VERSION ""

NS_ :

BS_:

BU_: VT OPC

BO_ 2632384254 VT12: 33 Vector__XXX
 SG_ AssignedAttribute2 m39 : 105|1@1+ (1,0) [0|1] "" Vector__XXX
 SG_ AssignedAttribute1 m39 : 104|1@1+ (1,0) [0|1] "" Vector__XXX
 SG_ FunctionAttribute m39 : 96|8@1+ (1,0) [0|255] "" Vector__XXX
 SG_ NumberOfInstances m39 : 88|8@1+ (1,0) [0|255] "" Vector__XXX
 SG_ NumberOfDifferentSets m39 : 80|8@1+ (1,0) [0|255] "" Vector__XXX
 SG_ NameOfAuxiliaryUnit m39 : 16|64@1+ (1,0) [0|0] "" Vector__XXX
 SG_ NumberOfAuxiliaryUnits m39 : 8|8@1+ (1,0) [0|255] "" Vector__XXX
 SG_ ExtendedVersionLables m211 : 8|256@1+ (1,0) [0|7.20575940379279E+016] "" Vector__XXX
 SG_ VTFunctionVTtoECU M : 0|8@1+ (1,0) [0|255] "" Vector__XXX
 SG_ BootTime m199 : 8|8@1+ (1,0) [0|255] "s" Vector__XXX
 SG_ NumberOfSupportedObjects m197 : 8|8@1+ (1,0) [0|255] "" Vector__XXX
 SG_ BckgndColourUserLayoutDataMask m196 : 8|8@1+ (1,0) [0|255] "" Vector__XXX
 SG_ ObjectID_1 m9 : 8|16@1+ (1,0) [0|65535] "" Vector__XXX
 SG_ InputNumber m33 : 8|8@1+ (1,0) [0|250] "" Vector__XXX
 SG_ TerminationCause m10 : 8|8@1+ (1,0) [0|255] "" Vector__XXX
 SG_ KeyActivationCode m0 : 8|8@1+ (1,0) [0|2] "" Vector__XXX
 SG_ ButtonActivationCode m1 : 8|8@1+ (1,0) [0|2] "" Vector__XXX
 SG_ XPosition m2 : 8|16@1+ (1,0) [0|65535] "" Vector__XXX
 SG_ VTSelectInputObjectID m3 : 8|16@1+ (1,0) [0|65535] "" Vector__XXX
 SG_ VTEscObjectID m4 : 8|16@1+ (1,0) [0|65535] "" Vector__XXX
 SG_ VTChangeNumericValueObjectID m5 : 8|16@1+ (1,0) [0|65535] "" Vector__XXX
 SG_ VTChangeActiveMaskObjectID m6 : 8|16@1+ (1,0) [0|65535] "" Vector__XXX
 SG_ VTChangeSoftKeyMaskParentID m7 : 8|16@1+ (1,0) [0|65535] "" Vector__XXX
 SG_ ObjectToChangeStringID m8 : 8|16@1+ (1,0) [0|65535] "" Vector__XXX
 SG_ ErrorCodeEndOfObjectPool1 m18 : 8|1@1+ (1,0) [0|1] "" Vector__XXX
 SG_ IdentityNumber m36 : 8|21@1+ (1,0) [0|2097150] "" Vector__XXX
 SG_ InputObjectId m38 : 8|16@1+ (1,0) [0|255] "" Vector__XXX
 SG_ AuxPreferredAssignmentRespError1 m34 : 8|1@1+ (1,0) [0|1] "" Vector__XXX
 SG_ InputStatusObjectId m37 : 8|16@1+ (1,0) [0|255] "" Vector__XXX
 SG_ ObjectEscapeID m146 : 8|16@1+ (1,0) [0|65535] "" Vector__XXX
 SG_ ObjectToHideShowID m160 : 8|16@1+ (1,0) [0|65535] "" Vector__XXX
 SG_ ObjectToEnableDisableID m161 : 8|16@1+ (1,0) [0|65535] "" Vector__XXX
 SG_ SelectInputObjectID m162 : 8|16@1+ (1,0) [0|65535] "" Vector__XXX
 SG_ ErrorCodeControlAudioDevice1 m163 : 8|1@1+ (1,0) [0|1] "" Vector__XXX
 SG_ ErrorCodeAudioVolume1 m164 : 8|1@1+ (1,0) [0|1] "" Vector__XXX
 SG_ ChangeChildLocationParentObjectI m165 : 8|16@1+ (1,0) [0|65535] "" Vector__XXX
 SG_ ObjectToSizeID m166 : 8|16@1+ (1,0) [0|65535] "" Vector__XXX
 SG_ ObjectToChangeColourID m167 : 8|16@1+ (1,0) [0|65535] "" Vector__XXX
 SG_ ObjectToChangeNumValueID m168 : 8|16@1+ (1,0) [0|65535] "" Vector__XXX
 SG_ ObjectToChangeEndPointID m169 : 8|16@1+ (1,0) [0|65535] "" Vector__XXX
 SG_ ObjectToChangeFontID m170 : 8|16@1+ (1,0) [0|65535] "" Vector__XXX
 SG_ ObjectToChangeLineAttributeID m171 : 8|16@1+ (1,0) [0|65535] "" Vector__XXX
 SG_ ObjectToChangeFillAttributesID m172 : 8|16@1+ (1,0) [0|65535] "" Vector__XXX
 SG_ ActiveMaskObjectID m173 : 8|16@1+ (1,0) [0|0] "" Vector__XXX
 SG_ DataOrAlarmMaskObjectID m174 : 8|16@1+ (1,0) [0|65535] "" Vector__XXX
 SG_ ObjectToChangeAttributeID m175 : 8|16@1+ (1,0) [0|65535] "" Vector__XXX
 SG_ AlarmMaskObjectID m176 : 8|16@1+ (1,0) [0|65535] "" Vector__XXX
 SG_ ListInputObjectID m177 : 8|16@1+ (1,0) [0|65535] "" Vector__XXX
 SG_ ErrorCodeDeleteObjectPool1 m178 : 8|1@1+ (1,0) [0|1] "" Vector__XXX
 SG_ ChangeChildPositionParentObjectI m180 : 8|16@1+ (1,0) [0|65535] "" Vector__XXX
 SG_ ErrorCodeSetObjectLabel1 m181 : 8|1@1+ (1,0) [0|1] "" Vector__XXX
 SG_ PolygonObjectToChangeID m182 : 8|16@1+ (1,0) [0|65535] "" Vector__XXX
 SG_ PolygonObjectToScaleID m183 : 8|16@1+ (1,0) [0|65535] "" Vector__XXX
 SG_ GraphicsContextObjectID m184 : 8|16@1+ (1,0) [0|65535] "" Vector__XXX
 SG_ ObjectToGetAttributeID m185 : 8|16@1+ (1,0) [0|65535] "" Vector__XXX
 SG_ ColourMapObjectID m186 : 8|16@1+ (1,0) [0|65535] "" Vector__XXX
 SG_ LockUnlockCommand m189 : 8|8@1+ (1,0) [0|1] "" Vector__XXX
 SG_ MacroObjecID m190 : 8|8@1+ (1,0) [0|255] "" Vector__XXX
 SG_ VersionNumberISO11783Part6 m192 : 8|8@1+ (1,0) [0|255] "" Vector__XXX
 SG_ CodePlane m193 : 8|8@1+ (1,0) [0|16] "" Vector__XXX
 SG_ NavigationSoftKeys m194 : 8|8@1+ (1,0) [0|254] "" Vector__XXX
 SG_ NrOfVersionStrings m224 : 8|8@1+ (1,0) [0|255] "" Vector__XXX
 SG_ ParentIDOfFaultyObject m240 : 8|16@1+ (1,0) [0|65535] "" Vector__XXX
 SG_ SourceAdressOfActiveWSM m254 : 8|8@1+ (1,0) [0|255] "" Vector__XXX
 SG_ ErrorCodeEndOfObjectPool2 m18 : 9|1@1+ (1,0) [0|1] "" Vector__XXX
 SG_ AuxPreferredAssignmentRespError2 m34 : 9|1@1+ (1,0) [0|1] "" Vector__XXX
 SG_ ErrorCodeSetObjectLabel2 m181 : 9|1@1+ (1,0) [0|1] "" Vector__XXX
 SG_ AuxPreferredAssignmentRespError3 m34 : 10|1@1+ (1,0) [0|1] "" Vector__XXX
 SG_ ErrorCodeSetObjectLabel3 m181 : 10|1@1+ (1,0) [0|1] "" Vector__XXX
 SG_ AuxPreferredAssignmentRespError4 m34 : 11|1@1+ (1,0) [0|1] "" Vector__XXX
 SG_ ErrorCodeSetObjectLabel4 m181 : 11|1@1+ (1,0) [0|1] "" Vector__XXX
 SG_ AuxPreferredAssignmentRespError5 m34 : 12|1@1+ (1,0) [0|1] "" Vector__XXX
 SG_ ErrorCodeEndOfObjectPool3 m18 : 12|1@1+ (1,0) [0|1] "" Vector__XXX
 SG_ ErrorCodeControlAudioDevice2 m163 : 12|1@1+ (1,0) [0|1] "" Vector__XXX
 SG_ ErrorCodeAudioVolume2 m164 : 12|1@1+ (1,0) [0|1] "" Vector__XXX
 SG_ ErrorCodeDeleteObjectPool2 m178 : 12|1@1+ (1,0) [0|1] "" Vector__XXX
 SG_ ErrorCodeSetObjectLabel5 m181 : 12|1@1+ (1,0) [0|1] "" Vector__XXX
 SG_ ErrorCodeSetObjectLabel6 m181 : 13|1@1+ (1,0) [0|1] "" Vector__XXX
 SG_ BckgndColourUserLayoutSoftkeyMas m196 : 16|8@1+ (1,0) [0|255] "" Vector__XXX
 SG_ AnalogValue m33 : 16|16@1+ (1,0) [0|65535] "" Vector__XXX
 SG_ AuxFunctObjOfFaultyAssignment m34 : 16|16@1- (1,0) [0|65535] "" Vector__XXX
 SG_ KeyObjectID m0 : 16|16@1+ (1,0) [0|65535] "" Vector__XXX
 SG_ ButtonObjectID m1 : 16|16@1+ (1,0) [0|65535] "" Vector__XXX
 SG_ ParentObjectIDOfFaultyObject m18 : 16|16@1+ (1,0) [0|65535] "" Vector__XXX
 SG_ ErrorCodeLockUnlockMask1 m189 : 16|1@1+ (1,0) [0|1] "" Vector__XXX
 SG_ ErrorCodeExecuteMacro1 m190 : 16|1@1+ (1,0) [0|1] "" Vector__XXX
 SG_ MemoryStatus m192 : 16|8@1+ (1,0) [0|1] "" Vector__XXX
 SG_ FirstWideChar m193 : 16|16@1+ (1,0) [0|65535] "" Vector__XXX
 SG_ SupportedGraphicMode m199 : 16|8@1+ (1,0) [0|2] "" Vector__XXX
 SG_ VersionLables m224 : 16|56@1+ (1,0) [0|0] "" Vector__XXX
 SG_ VisibleDataOrAlarmMaskObjectID m254 : 16|16@1+ (1,0) [0|65535] "" Vector__XXX
 SG_ ErrorCodeLockUnlockMask2 m189 : 17|1@1+ (1,0) [0|1] "" Vector__XXX
 SG_ ErrorCodeExecuteMacro2 m190 : 17|1@1+ (1,0) [0|1] "" Vector__XXX
 SG_ ErrorCodeLockUnlockMask3 m189 : 18|1@1+ (1,0) [0|1] "" Vector__XXX
 SG_ ErrorCodeExecuteMacro3 m190 : 18|1@1+ (1,0) [0|1] "" Vector__XXX
 SG_ ErrorCodeLockUnlockMask4 m189 : 19|1@1+ (1,0) [0|1] "" Vector__XXX
 SG_ ErrorCodeLockUnlockMask5 m189 : 20|1@1+ (1,0) [0|1] "" Vector__XXX
 SG_ ErrorCodeLockUnlockMask6 m189 : 21|1@1+ (1,0) [0|1] "" Vector__XXX
 SG_ ErrorCodeLockUnlockMask7 m189 : 22|1@1+ (1,0) [0|1] "" Vector__XXX
 SG_ ErrorCodeLockUnlockMask8 m189 : 23|1@1+ (1,0) [0|1] "" Vector__XXX
 SG_ Status_1 m9 : 24|8@1+ (1,0) [0|1] "" Vector__XXX
 SG_ YPosition m2 : 24|16@1+ (1,0) [0|65535] "" Vector__XXX
 SG_ VTSelectInputObjectStatus m3 : 24|8@1+ (1,0) [0|1] "" Vector__XXX
 SG_ ErrorCodeVTEsc1 m4 : 24|1@1+ (1,0) [0|1] "" Vector__XXX
 SG_ VTChangeSoftKeyMaskObjectID m7 : 24|16@1+ (1,0) [0|65535] "" Vector__XXX
 SG_ EnteredStringValue m8 : 24|8@1+ (1,0) [0|255] "" Vector__XXX
 SG_ Value1 m38 : 24|16@1+ (1,0) [0|65535] "" Vector__XXX
 SG_ AuxInputEnable m37 : 24|8@1+ (1,0) [0|1] "" Vector__XXX
 SG_ ErrorCodeEscapeObj1 m146 : 24|1@1+ (1,0) [0|1] "" Vector__XXX
 SG_ ObjectShowStatus m160 : 24|8@1+ (1,0) [0|1] "" Vector__XXX
 SG_ ObjectEnableStatus m161 : 24|8@1+ (1,0) [0|1] "" Vector__XXX
 SG_ ObjectSelectStatus m162 : 24|8@1+ (1,0) [0|2] "" Vector__XXX
 SG_ ChangeChildLocationObjectID m165 : 24|16@1+ (1,0) [0|65535] "" Vector__XXX
 SG_ ErrorCodeObjToSize1 m166 : 24|1@1+ (1,0) [0|1] "" Vector__XXX
 SG_ NewBackgroundColour m167 : 24|8@1+ (1,0) [0|255] "" Vector__XXX
 SG_ ErrorCodeChangeNumValue1 m168 : 24|1@1+ (1,0) [0|1] "" Vector__XXX
 SG_ ErrorCodeChangeEditPoint1 m169 : 24|1@1+ (1,0) [0|1] "" Vector__XXX
 SG_ ErrorCodeChangeFont1 m170 : 24|1@1+ (1,0) [0|1] "" Vector__XXX
 SG_ ErrorCodeChangeLineAttribute1 m171 : 24|1@1+ (1,0) [0|1] "" Vector__XXX
 SG_ ErrorCodeChangeFillAttributes1 m172 : 24|1@1+ (1,0) [0|1] "" Vector__XXX
 SG_ ErrorCodeChangeActiveMask1 m173 : 24|1@1+ (1,0) [0|1] "" Vector__XXX
 SG_ SoftKeyMaskObjectID m174 : 24|16@1+ (1,0) [0|65535] "" Vector__XXX
 SG_ AttributeToChangeID m175 : 24|8@1+ (1,0) [0|65535] "" Vector__XXX
 SG_ NewPriority m176 : 24|8@1+ (1,0) [0|255] "" Vector__XXX
 SG_ ListIndex m177 : 24|8@1+ (1,0) [0|255] "" Vector__XXX
 SG_ ChangeStringValueObjectID m179 : 24|16@1+ (1,0) [0|65535] "" Vector__XXX
 SG_ ChangeChildPositionObjectID m180 : 24|16@1+ (1,0) [0|65535] "" Vector__XXX
 SG_ ErrorCodeChangePoygonPoint1 m182 : 24|1@1+ (1,0) [0|1] "" Vector__XXX
 SG_ NewWidthAttribute m183 : 24|16@1+ (1,0) [0|65535] "" Vector__XXX
 SG_ SubCommandID m184 : 24|8@1+ (1,0) [0|0] "" Vector__XXX
 SG_ AttributeID m185 : 24|8@1+ (1,0) [0|0] "" Vector__XXX
 SG_ ErrorCodeSelectColourMap1 m186 : 24|1@1+ (1,0) [0|1] "" Vector__XXX
 SG_ Hardware1 m199 : 24|1@1+ (1,0) [0|1] "" Vector__XXX
 SG_ ObjectIDOfFaultyObject m240 : 24|16@1+ (1,0) [0|65535] "" Vector__XXX
 SG_ ErrorCodeObjToSize2 m166 : 25|1@1+ (1,0) [0|1] "" Vector__XXX
 SG_ ErrorCodeChangeNumValue2 m168 : 25|1@1+ (1,0) [0|1] "" Vector__XXX
 SG_ ErrorCodeChangeEditPoint2 m169 : 25|1@1+ (1,0) [0|1] "" Vector__XXX
 SG_ ErrorCodeChangeFont2 m170 : 25|1@1+ (1,0) [0|1] "" Vector__XXX
 SG_ ErrorCodeChangeLineAttribute2 m171 : 25|1@1+ (1,0) [0|1] "" Vector__XXX
 SG_ ErrorCodeChangeFillAttributes2 m172 : 25|1@1+ (1,0) [0|1] "" Vector__XXX
 SG_ ErrorCodeChangeActiveMask2 m173 : 25|1@1+ (1,0) [0|1] "" Vector__XXX
 SG_ ErrorCodeChangePoygonPoint2 m182 : 25|1@1+ (1,0) [0|1] "" Vector__XXX
 SG_ ErrorCodeSelectColourMap2 m186 : 25|1@1+ (1,0) [0|1] "" Vector__XXX
 SG_ Hardware2 m199 : 25|1@1+ (1,0) [0|1] "" Vector__XXX
 SG_ ErrorCodeMissingObjects m6 : 26|1@1+ (1,0) [0|1] "" Vector__XXX
 SG_ ErrorCodeObjToSize3 m166 : 26|1@1+ (1,0) [0|1] "" Vector__XXX
 SG_ ErrorCodeChangeFont3 m170 : 26|1@1+ (1,0) [0|1] "" Vector__XXX
 SG_ ErrorCodeChangeLineAttribute3 m171 : 26|1@1+ (1,0) [0|1] "" Vector__XXX
 SG_ ErrorCodeChangeFillAttributes3 m172 : 26|1@1+ (1,0) [0|1] "" Vector__XXX
 SG_ ErrorCodeChangeActiveMask3 m173 : 26|1@1+ (1,0) [0|1] "" Vector__XXX
 SG_ ErrorCodeChangePoygonPoint3 m182 : 26|1@1+ (1,0) [0|1] "" Vector__XXX
 SG_ Hardware3 m199 : 26|1@1+ (1,0) [0|1] "" Vector__XXX
 SG_ ErrorCodeMaskOrChildObjectError m6 : 27|1@1+ (1,0) [0|1] "" Vector__XXX
 SG_ ErrorCodeChangeFont4 m170 : 27|1@1+ (1,0) [0|1] "" Vector__XXX
 SG_ ErrorCodeChangeFillAttributes4 m172 : 27|1@1+ (1,0) [0|1] "" Vector__XXX
 SG_ ErrorCodeChangeActiveMask4 m173 : 27|1@1+ (1,0) [0|1] "" Vector__XXX
 SG_ Hardware4 m199 : 27|1@1+ (1,0) [0|1] "" Vector__XXX
 SG_ ErrorCodeChangeNumValue4 m168 : 28|1@1+ (1,0) [0|1] "" Vector__XXX
 SG_ ErrorCodeVTEsc2 m4 : 28|1@1+ (1,0) [0|1] "" Vector__XXX
 SG_ ErrorCodeAnyOtherError m6 : 28|1@1+ (1,0) [0|1] "" Vector__XXX
 SG_ ErrorCodeEscapeObj2 m146 : 28|1@1+ (1,0) [0|1] "" Vector__XXX
 SG_ ErrorCodeObjToSize4 m166 : 28|1@1+ (1,0) [0|1] "" Vector__XXX
 SG_ ErrorCodeChangeNumValue3 m168 : 26|1@1+ (1,0) [0|1] "" Vector__XXX
 SG_ ErrorCodeChangeEditPoint3 m169 : 28|1@1+ (1,0) [0|1] "" Vector__XXX
 SG_ ErrorCodeChangeFont5 m170 : 28|1@1+ (1,0) [0|1] "" Vector__XXX
 SG_ ErrorCodeChangeLineAttribute4 m171 : 28|1@1+ (1,0) [0|1] "" Vector__XXX
 SG_ ErrorCodeChangeFillAttributes5 m172 : 28|1@1+ (1,0) [0|1] "" Vector__XXX
 SG_ ErrorCodeChangeActiveMask5 m173 : 28|1@1+ (1,0) [0|1] "" Vector__XXX
 SG_ Hardware5 m199 : 28|1@1+ (1,0) [0|1] "" Vector__XXX
 SG_ ErrorCodePoolDeleted m6 : 29|1@1+ (1,0) [0|1] "" Vector__XXX
 SG_ ManufacturerCode m36 : 29|11@1+ (1,0) [0|2047] "" Vector__XXX
 SG_ ErrorCodeChangeFont6 m170 : 29|1@1+ (1,0) [0|1] "" Vector__XXX
 SG_ Hardware6 m199 : 29|1@1+ (1,0) [0|1] "" Vector__XXX
 SG_ ObjectID_2 m9 : 32|16@1+ (1,0) [0|65535] "" Vector__XXX
 SG_ NumTransitionsDisabledToEnabled m33 : 32|16@1+ (1,0) [0|65535] "" Vector__XXX
 SG_ KeyObjectParentID m0 : 32|16@1+ (1,0) [0|65535] "" Vector__XXX
 SG_ ButtonObjectParentID m1 : 32|16@1+ (1,0) [0|65535] "" Vector__XXX
 SG_ VTSelectInputObjectIsEdited m3 : 32|1@1+ (1,0) [0|1] "" Vector__XXX
 SG_ VTChangeNumericValueValue m5 : 32|32@1+ (1,0) [0|4294967295] "" Vector__XXX
 SG_ VTChangeActiveMaskErrorID m6 : 32|16@1+ (1,0) [0|65535] "" Vector__XXX
 SG_ ObjectIdOfFaultyObject m18 : 32|16@1+ (1,0) [0|65535] "" Vector__XXX
 SG_ ErrorCodeHideShowObj1 m160 : 32|1@1+ (1,0) [0|1] "" Vector__XXX
 SG_ ErrorCodeSelectObject1 m162 : 32|1@1+ (1,0) [0|1] "" Vector__XXX
 SG_ ErrorCodeChangeColour1 m167 : 32|1@1+ (1,0) [0|1] "" Vector__XXX
 SG_ ValueOfTheObject m168 : 32|32@1+ (1,0) [0|2704] "" Vector__XXX
 SG_ ErrorCodeChangeAttribute1 m175 : 32|1@1+ (1,0) [0|1] "" Vector__XXX
 SG_ ErrorCodeChangePriority1 m176 : 32|1@1+ (1,0) [0|1] "" Vector__XXX
 SG_ NewObjectID m177 : 32|16@1+ (1,0) [0|65535] "" Vector__XXX
 SG_ ErrorCodeGraphicsContextCmd1 m184 : 32|1@1+ (1,0) [0|1] "" Vector__XXX
 SG_ LastWideChar m193 : 32|16@1+ (1,0) [0|65535] "" Vector__XXX
 SG_ XDotsForSoftKeyDescriptor m194 : 32|8@1+ (1,0) [0|255] "" Vector__XXX
 SG_ NrOfXPixelsInDataAreaMask m199 : 32|16@1+ (1,0) [0|65535] "" Vector__XXX
 SG_ VisibleSoftKeyMaskObjectID m254 : 32|16@1+ (1,0) [0|65535] "" Vector__XXX
 SG_ ErrorCodeHideShowObj2 m160 : 33|1@1+ (1,0) [0|1] "" Vector__XXX
 SG_ ErrorCodeEnableDisableObj1 m161 : 33|1@1+ (1,0) [0|1] "" Vector__XXX
 SG_ ErrorCodeSelectObject2 m162 : 33|1@1+ (1,0) [0|1] "" Vector__XXX
 SG_ ErrorCodeChangeColour2 m167 : 33|1@1+ (1,0) [0|1] "" Vector__XXX
 SG_ ErrorCodeChangeAttribute2 m175 : 33|1@1+ (1,0) [0|1] "" Vector__XXX
 SG_ ErrorCodeChangePriority2 m176 : 33|1@1+ (1,0) [0|1] "" Vector__XXX
 SG_ ErrorCodeGraphicsContextCmd2 m184 : 33|1@1+ (1,0) [0|1] "" Vector__XXX
 SG_ ErrorCodeEnableDisableObj2 m161 : 34|1@1+ (1,0) [0|1] "" Vector__XXX
 SG_ ErrorCodeSelectObject3 m162 : 34|1@1+ (1,0) [0|1] "" Vector__XXX
 SG_ ErrorCodeChangeAttribute3 m175 : 34|1@1+ (1,0) [0|1] "" Vector__XXX
 SG_ ErrorCodeGraphicsContextCmd3 m184 : 34|1@1+ (1,0) [0|1] "" Vector__XXX
 SG_ ErrorCodeHideShowObj3 m160 : 35|1@1+ (1,0) [0|1] "" Vector__XXX
 SG_ ErrorCodeEnableDisableObj3 m161 : 35|1@1+ (1,0) [0|1] "" Vector__XXX
 SG_ ErrorCodeSelectObject4 m162 : 35|1@1+ (1,0) [0|1] "" Vector__XXX
 SG_ ErrorCodeGraphicsContextCmd4 m184 : 35|1@1+ (1,0) [0|1] "" Vector__XXX
 SG_ ErrorCodeEnableDisableObj4 m161 : 36|1@1+ (1,0) [0|1] "" Vector__XXX
 SG_ ErrorCodeSelectObject5 m162 : 36|1@1+ (1,0) [0|1] "" Vector__XXX
 SG_ ErrorCodeChangeColour3 m167 : 36|1@1+ (1,0) [0|1] "" Vector__XXX
 SG_ ErrorCodeChangeAttribute4 m175 : 35|1@1+ (1,0) [0|1] "" Vector__XXX
 SG_ ErrorCodeChangePriority3 m176 : 36|1@1+ (1,0) [0|1] "" Vector__XXX
 SG_ ErrorCodeGraphicsContextCmd5 m184 : 36|1@1+ (1,0) [0|1] "" Vector__XXX
 SG_ ErrorCodeSelectObject6 m162 : 37|1@1+ (1,0) [0|1] "" Vector__XXX
 SG_ ErrorCodeVTChangeSoftKeyMask1 m7 : 40|1@1+ (1,0) [0|1] "" Vector__XXX
 SG_ TouchState m2 : 40|8@1+ (1,0) [0|255] "" Vector__XXX
 SG_ ECUInstance m36 : 40|3@1+ (1,0) [0|7] "" Vector__XXX
 SG_ Value2 m38 : 40|16@1+ (1,0) [0|65535] "" Vector__XXX
 SG_ ErrorCodeChangeChildLocation1 m165 : 40|1@1+ (1,0) [0|1] "" Vector__XXX
 SG_ ErrorCodeChangeSoftKeyMask1 m174 : 40|1@1+ (1,0) [0|1] "" Vector__XXX
 SG_ ErrorCodeChangePosInvalidParent m180 : 40|1@1+ (1,0) [0|1] "" Vector__XXX
 SG_ NewHeigthAttribute m183 : 40|16@1+ (1,0) [0|0] "" Vector__XXX
 SG_ YDotsForSoftKeyDescriptor m194 : 40|8@1+ (1,0) [0|255] "" Vector__XXX
 SG_ FontSize_8x8 m195 : 40|1@1+ (1,0) [0|1] "" Vector__XXX
 SG_ AcknowledgmentStoreVersion m208 : 40|4@1+ (1,0) [0|8] "" Vector__XXX
 SG_ AcknowledgmentLoadVersion m209 : 40|4@1+ (1,0) [0|8] "" Vector__XXX
 SG_ AcknowledgmentDeleteVersion m210 : 40|4@1+ (1,0) [0|8] "" Vector__XXX
 SG_ ErrorCodeVtObjPoolError1 m240 : 40|1@1+ (1,0) [0|1] "" Vector__XXX
 SG_ ErrorCodeVTChangeSoftKeyMask2 m7 : 41|1@1+ (1,0) [0|1] "" Vector__XXX
 SG_ ErrorCodeChangeChildLocation2 m165 : 41|1@1+ (1,0) [0|1] "" Vector__XXX
 SG_ ErrorCodeChangeSoftKeyMask2 m174 : 41|1@1+ (1,0) [0|1] "" Vector__XXX
 SG_ ErrorCodeChangeStrObjectID m179 : 41|1@1+ (1,0) [0|1] "" Vector__XXX
 SG_ ErrorCodeChangePosInvalidObject m180 : 41|1@1+ (1,0) [0|1] "" Vector__XXX
 SG_ FontSize_8x12 m195 : 41|1@1+ (1,0) [0|1] "" Vector__XXX
 SG_ ErrorCodeVtObjPoolError2 m240 : 41|1@1+ (1,0) [0|1] "" Vector__XXX
 SG_ ErrorCodeVTChangeSoftKeyMask3 m7 : 42|1@1+ (1,0) [0|1] "" Vector__XXX
 SG_ ErrorCodeChangeSoftKeyMask3 m174 : 42|1@1+ (1,0) [0|1] "" Vector__XXX
 SG_ ErrorCodeChangeStrTooLong m179 : 42|1@1+ (1,0) [0|1] "" Vector__XXX
 SG_ FontSize_12x16 m195 : 42|1@1+ (1,0) [0|1] "" Vector__XXX
 SG_ ErrorCodeVtObjPoolError3 m240 : 42|1@1+ (1,0) [0|1] "" Vector__XXX
 SG_ ErrorCodeVTChangeSoftKeyMask4 m7 : 43|1@1+ (1,0) [0|1] "" Vector__XXX
 SG_ FunctionInstance m36 : 43|5@1+ (1,0) [0|31] "" Vector__XXX
 SG_ ErrorCodeChangeSoftKeyMask4 m174 : 43|1@1+ (1,0) [0|1] "" Vector__XXX
 SG_ ErrorCodeChangeStrError m179 : 43|1@1+ (1,0) [0|1] "" Vector__XXX
 SG_ FontSize_16x16 m195 : 43|1@1+ (1,0) [0|1] "" Vector__XXX
 SG_ ErrorCodeVtObjPoolError4 m240 : 43|1@1+ (1,0) [0|1] "" Vector__XXX
 SG_ ErrorCodeChangeStrValueInUse m179 : 44|1@1+ (1,0) [0|1] "" Vector__XXX
 SG_ ErrorCodeVTChangeSoftKeyMask5 m7 : 44|1@1+ (1,0) [0|1] "" Vector__XXX
 SG_ ErrorCodeChangeChildLocation5 m165 : 44|1@1+ (1,0) [0|1] "" Vector__XXX
 SG_ ErrorCodeChangeSoftKeyMask5 m174 : 44|1@1+ (1,0) [0|1] "" Vector__XXX
 SG_ ErrorCodeChangePosInvalidError m180 : 44|1@1+ (1,0) [0|1] "" Vector__XXX
 SG_ FontSize_16x24 m195 : 44|1@1+ (1,0) [0|1] "" Vector__XXX
 SG_ FontSize_24x32 m195 : 45|1@1+ (1,0) [0|1] "" Vector__XXX
 SG_ FontSize_32x32 m195 : 46|1@1+ (1,0) [0|1] "" Vector__XXX
 SG_ Status_2 m9 : 48|8@1+ (1,0) [0|1] "" Vector__XXX
 SG_ BooleanValue m33 : 48|8@1+ (1,0) [0|2] "" Vector__XXX
 SG_ SoftKeyCode m0 : 48|8@1+ (1,0) [0|255] "" Vector__XXX
 SG_ ButtonKeyCode m1 : 48|8@1+ (1,0) [0|255] "" Vector__XXX
 SG_ VTChangeActiveMaskParentID m6 : 48|16@1+ (1,0) [0|65535] "" Vector__XXX
 SG_ ErrorCodeObjectPool1 m18 : 48|1@1+ (1,0) [0|1] "" Vector__XXX
 SG_ Function m36 : 48|8@1+ (1,0) [0|255] "" Vector__XXX
 SG_ ErrorCodeChangeListItem1 m177 : 48|1@1+ (1,0) [0|1] "" Vector__XXX
 SG_ ErrorCodeGetSupportedWideChars1 m193 : 48|1@1+ (1,0) [0|1] "" Vector__XXX
 SG_ NumberOfPossibleVirtualSoftKeys m194 : 48|8@1+ (1,0) [0|255] "" Vector__XXX
 SG_ FontSize_32x48 m195 : 48|1@1+ (1,0) [0|1] "" Vector__XXX
 SG_ NrOfYPixelsInDataAreaMask m199 : 48|16@1+ (1,0) [0|65535] "" Vector__XXX
 SG_ VTBusyCode1 m254 : 48|1@1+ (1,0) [0|1] "" Vector__XXX
 SG_ ErrorCodeObjectPool2 m18 : 49|1@1+ (1,0) [0|1] "" Vector__XXX
 SG_ ErrorCodeChangeListItem2 m177 : 49|1@1+ (1,0) [0|1] "" Vector__XXX
 SG_ FontSize_48x64 m195 : 49|1@1+ (1,0) [0|1] "" Vector__XXX
 SG_ VTBusyCode2 m254 : 49|1@1+ (1,0) [0|1] "" Vector__XXX
 SG_ ErrorCodeObjectPool3 m18 : 50|1@1+ (1,0) [0|1] "" Vector__XXX
 SG_ ErrorCodeChangeListItem3 m177 : 50|1@1+ (1,0) [0|1] "" Vector__XXX
 SG_ FontSize_64x64 m195 : 50|1@1+ (1,0) [0|1] "" Vector__XXX
 SG_ VTBusyCode3 m254 : 50|1@1+ (1,0) [0|1] "" Vector__XXX
 SG_ ErrorCodeObjectPool4 m18 : 51|1@1+ (1,0) [0|1] "" Vector__XXX
 SG_ FontSize_64x96 m195 : 51|1@1+ (1,0) [0|1] "" Vector__XXX
 SG_ VTBusyCode4 m254 : 51|1@1+ (1,0) [0|1] "" Vector__XXX
 SG_ ErrorCodeChangeListItem4 m177 : 51|1@1+ (1,0) [0|1] "" Vector__XXX
 SG_ ErrorCodeChangeListItem5 m177 : 52|1@1+ (1,0) [0|1] "" Vector__XXX
 SG_ ErrorCodeGetSupportedWideChars2 m193 : 52|1@1+ (1,0) [0|1] "" Vector__XXX
 SG_ FontSize_96x128 m195 : 52|1@1+ (1,0) [0|1] "" Vector__XXX
 SG_ VTBusyCode5 m254 : 52|1@1+ (1,0) [0|1] "" Vector__XXX
 SG_ FontSize_128x128 m195 : 53|1@1+ (1,0) [0|1] "" Vector__XXX
 SG_ VTBusyCode7 m254 : 54|1@1+ (1,0) [0|1] "" Vector__XXX
 SG_ FontSize_128x192 m195 : 54|1@1+ (1,0) [0|1] "" Vector__XXX
 SG_ VTBusyCode8 m254 : 55|1@1+ (1,0) [0|1] "" Vector__XXX
 SG_ OperatingState1 m38 : 56|1@1+ (1,0) [0|1] "" Vector__XXX
 SG_ ErrorCodeChangePolygonScale1 m183 : 56|1@1+ (1,0) [0|1] "" Vector__XXX
 SG_ NumberOfRanges m193 : 56|8@1+ (1,0) [0|255] "" Vector__XXX
 SG_ NumberOfPhysicalSoftKeys m194 : 56|8@1+ (1,0) [0|255] "" Vector__XXX
 SG_ FontType_BoldText m195 : 56|1@1+ (1,0) [0|1] "" Vector__XXX
 SG_ VTFunctionCode m254 : 56|8@1+ (1,0) [0|255] "" Vector__XXX
 SG_ OperatingState2 m38 : 57|1@1+ (1,0) [0|1] "" Vector__XXX
 SG_ DeviceClass m36 : 57|7@1+ (1,0) [0|127] "" Vector__XXX
 SG_ FontType_CrossedOutText m195 : 57|1@1+ (1,0) [0|1] "" Vector__XXX
 SG_ FontType_UnderlinedText m195 : 58|1@1+ (1,0) [0|1] "" Vector__XXX
 SG_ FontType_ItalicsText m195 : 59|1@1+ (1,0) [0|1] "" Vector__XXX
 SG_ ErrorCodeChangePolygonScale5 m183 : 60|1@1+ (1,0) [0|1] "" Vector__XXX
 SG_ FontType_InvertedText m195 : 60|1@1+ (1,0) [0|1] "" Vector__XXX
 SG_ FontType_FlashInverted m195 : 61|1@1+ (1,0) [0|1] "" Vector__XXX
 SG_ FontType_FlashHidden m195 : 62|1@1+ (1,0) [0|1] "" Vector__XXX
 SG_ FontType_ProportionalFont m195 : 63|1@1+ (1,0) [0|1] "" Vector__XXX
 SG_ IndustryGroup m36 : 64|3@1+ (1,0) [0|7] "" Vector__XXX
 SG_ DeviceClassInstance m36 : 67|4@1+ (1,0) [0|15] "" Vector__XXX
 SG_ SelfConfigurableAddress m36 : 71|1@1+ (1,0) [0|1] "" Vector__XXX
 SG_ AuxiliaryFunctionType m36 : 72|4@1+ (1,0) [0|15] "" Vector__XXX
 SG_ ErrorCodeChangeAttribute5 m175 : 76|1@1+ (1,0) [0|1] "" Vector__XXX
 SG_ StoreAsPreferredAssignment m36 : 79|1@1+ (1,0) [0|1] "" Vector__XXX
 SG_ AuxiliaryInputObjectID m36 : 80|16@1+ (1,0) [0|65535] "" Vector__XXX
 SG_ AuxiliaryFunctionObjectID m36 : 96|16@1+ (1,0) [0|65535] "" Vector__XXX

BO_ 2565340926 VT21: 33 OPC
 SG_ AuxCapabilitiesRequestType m39 : 8|8@1+ (1,0) [0|255] "" Vector__XXX
 SG_ MacroObjectID_2 m188 : 8|16@1+ (1,0) [0|65535] "" Vector__XXX
 SG_ ExtendedVersionLabelToStore m212 : 8|256@1+ (1,0) [0|3338120000] "" Vector__XXX
 SG_ ExtendedVersionLabelToLoad m213 : 8|256@1+ (1,0) [0|3338120000] "" Vector__XXX
 SG_ ExtendedVersionLabelToDelete m214 : 8|256@1+ (1,0) [0|3338120000] "" Vector__XXX
 SG_ VTFunctionECUtoVT M : 0|8@1+ (1,0) [0|255] "" Vector__XXX
 SG_ ObjectId_1 m9 : 8|16@1+ (1,0) [0|65535] "" Vector__XXX
 SG_ SourceAddressOfAuxiliaryInputDev m32 : 8|8@1+ (1,0) [0|255] "" Vector__XXX
 SG_ InputObjectId m33 : 8|16@1+ (1,0) [0|255] "" Vector__XXX
 SG_ KeyActivationCode m0 : 8|8@1+ (1,0) [0|2] "" Vector__XXX
 SG_ ButtonActivationCode m1 : 8|8@1+ (1,0) [0|2] "" Vector__XXX
 SG_ XPosition m2 : 8|16@1+ (1,0) [0|65535] "" Vector__XXX
 SG_ VTSelectInputObjectID m3 : 8|16@1+ (1,0) [0|65535] "" Vector__XXX
 SG_ VTEscObjectID m4 : 8|16@1+ (1,0) [0|65535] "" Vector__XXX
 SG_ VTChangeNumericValueObjectID m5 : 8|16@1+ (1,0) [0|65535] "" Vector__XXX
 SG_ VTChangeActiveMaskObjectID m6 : 8|16@1+ (1,0) [0|65535] "" Vector__XXX
 SG_ VTChangeSoftKeyMaskParentID m7 : 8|16@1+ (1,0) [0|65535] "" Vector__XXX
 SG_ ChangeChildPositionParentOb_0000 m180 : 8|16@1+ (1,0) [0|65535] "" Vector__XXX
 SG_ ObjectPoolRecord m17 : 8|56@1+ (1,0) [0|3338120000] "" Vector__XXX
 SG_ AuxiliaryFunctionObjectID m36 : 8|16@1+ (1,0) [0|65535] "" Vector__XXX
 SG_ NumberOfInpuUnits m34 : 8|8@1+ (1,0) [0|255] "" Vector__XXX
 SG_ AuxModelIdentification m35 : 8|16@1+ (1,0) [0|65535] "" Vector__XXX
 SG_ InputStatusObjectId m37 : 8|16@1+ (1,0) [0|255] "" Vector__XXX
 SG_ ObjectToShowHideID m160 : 8|16@1+ (1,0) [0|65535] "" Vector__XXX
 SG_ ObjectoEnableDisbaleID m161 : 8|16@1+ (1,0) [0|65535] "" Vector__XXX
 SG_ SelectInputObjectID m162 : 8|16@1+ (1,0) [0|65535] "" Vector__XXX
 SG_ NumberOfRepetitions_Audio m163 : 8|8@1+ (1,0) [0|255] "" Vector__XXX
 SG_ AudioVolume m164 : 8|8@1+ (1,0) [0|100] "%" Vector__XXX
 SG_ ChangeChildLocationParentOb_0000 m165 : 8|16@1+ (1,0) [0|65535] "" Vector__XXX
 SG_ ObjectToSizeID m166 : 8|16@1+ (1,0) [0|65535] "" Vector__XXX
 SG_ ObjectToChangeColourID m167 : 8|16@1+ (1,0) [0|65535] "" Vector__XXX
 SG_ ObjectToChangeNumValueID m168 : 8|16@1+ (1,0) [0|65535] "" Vector__XXX
 SG_ ObjectToChangeEndPointID m169 : 8|16@1+ (1,0) [0|65535] "" Vector__XXX
 SG_ ObjectToChangeFontID m170 : 8|16@1+ (1,0) [0|65535] "" Vector__XXX
 SG_ ObjectToChangeLineAttributesID m171 : 8|16@1+ (1,0) [0|65535] "" Vector__XXX
 SG_ ObjectToChangeFillAttributesID m172 : 8|16@1+ (1,0) [0|65535] "" Vector__XXX
 SG_ WorkingSetObjectID m173 : 8|16@1+ (1,0) [0|65535] "" Vector__XXX
 SG_ MaskType m174 : 8|8@1+ (1,0) [0|255] "" Vector__XXX
 SG_ ObjectToChangeAttributeID m175 : 8|16@1+ (1,0) [0|65535] "" Vector__XXX
 SG_ AlarmMaskObjectID m176 : 8|16@1+ (1,0) [0|65535] "" Vector__XXX
 SG_ ListInputObjectID m177 : 8|16@1+ (1,0) [0|65535] "" Vector__XXX
 SG_ ObjectToChangeStringValueID m179 : 8|16@1+ (1,0) [0|65535] "" Vector__XXX
 SG_ ParentObjectID m8 : 8|16@1+ (1,0) [0|65535] "" Vector__XXX
 SG_ ObjectToAssociateLabelWithID m181 : 8|16@1+ (1,0) [0|65535] "" Vector__XXX
 SG_ PolygonObjectToChangeID m182 : 8|16@1+ (1,0) [0|65535] "" Vector__XXX
 SG_ PolygonObjectToScaleID m183 : 8|16@1+ (1,0) [0|65535] "" Vector__XXX
 SG_ GraphicsContextObjectID m184 : 8|16@1+ (1,0) [0|65535] "" Vector__XXX
 SG_ ObjectToGetAttributeID m185 : 8|16@1+ (1,0) [0|65535] "" Vector__XXX
 SG_ ColourMapObjectID m186 : 8|16@1+ (1,0) [0|65535] "" Vector__XXX
 SG_ LockUnlockCommand m189 : 8|8@1+ (1,0) [0|1] "" Vector__XXX
 SG_ MacroObjecID m190 : 8|8@1+ (1,0) [0|255] "" Vector__XXX
 SG_ CodePlane m193 : 8|8@1+ (1,0) [0|16] "" Vector__XXX
 SG_ VersionLabelToStore m208 : 8|56@1+ (1,0) [0|3338120000] "" Vector__XXX
 SG_ VersionLabelToLoad m209 : 8|56@1+ (1,0) [0|3338120000] "" Vector__XXX
 SG_ VersionLabelToDelete m210 : 8|56@1+ (1,0) [0|3338120000] "" Vector__XXX
 SG_ WSMaintenanceInitiating m3 : 8|1@1+ (1,0) [0|1] "" Vector__XXX
 SG_ AuxiliaryInputNumber m32 : 16|8@1+ (1,0) [0|255] "" Vector__XXX
 SG_ WSMaintenanceVersion m255M : 16|8@1+ (1,0) [0|255] "" Vector__XXX
 SG_ KeyObjectID m0 : 16|16@1+ (1,0) [0|65535] "" Vector__XXX
 SG_ ButtonObjectID m1 : 16|16@1+ (1,0) [0|65535] "" Vector__XXX
 SG_ Frequency_Audio m163 : 16|16@1+ (1,0) [0|65535] "hz" Vector__XXX
 SG_ DataOrAlarmMaskObjectID m174 : 16|16@1+ (1,0) [0|65535] "" Vector__XXX
 SG_ ObjectIDOfDataMaskToLock m189 : 16|16@1+ (1,0) [0|65535] "" Vector__XXX
 SG_ MemoryRequired m192 : 16|32@1+ (1,0) [0|4294967295] "" Vector__XXX
 SG_ FirstWideChar m193 : 16|16@1+ (1,0) [0|65535] "" Vector__XXX
 SG_ Status_1 m9 : 24|8@1+ (1,0) [0|1] "" Vector__XXX
 SG_ AuxiliaryFunctionID m32 : 24|16@1+ (1,0) [0|65535] "" Vector__XXX
 SG_ YPosition m2 : 24|16@1+ (1,0) [0|65535] "" Vector__XXX
 SG_ VTSelectInputObjectStatus m3 : 24|8@1+ (1,0) [0|1] "" Vector__XXX
 SG_ VTChangeSoftKeyMaskObjectID m7 : 24|16@1+ (1,0) [0|65535] "" Vector__XXX
 SG_ ObjectOfChangedStringValueID m8 : 24|16@1+ (1,0) [0|65535] "" Vector__XXX
 SG_ AssignmentErrorNotAccepted m36 : 24|1@1+ (1,0) [0|1] "" Vector__XXX
 SG_ AuxInputEnable m37 : 24|8@1+ (1,0) [0|1] "" Vector__XXX
 SG_ ShowOrHide m160 : 24|8@1+ (1,0) [0|1] "" Vector__XXX
 SG_ EnableOrDisable m161 : 24|8@1+ (1,0) [0|1] "" Vector__XXX
 SG_ SetFocusOpenForEditing m162 : 24|8@1+ (1,0) [0|255] "" Vector__XXX
 SG_ ChangeChildPositionObjectID m180 : 24|16@1+ (1,0) [0|65535] "" Vector__XXX
 SG_ NewWidth m166 : 24|16@1+ (1,0) [0|65535] "" Vector__XXX
 SG_ NewBackgroundColour m167 : 24|8@1+ (1,0) [0|255] "" Vector__XXX
 SG_ Width m169 : 24|16@1+ (1,0) [0|65535] "" Vector__XXX
 SG_ FontColour m170 : 24|8@1+ (1,0) [0|255] "" Vector__XXX
 SG_ LineColour m171 : 24|8@1+ (1,0) [0|255] "" Vector__XXX
 SG_ FillType m172 : 24|8@1+ (1,0) [0|255] "" Vector__XXX
 SG_ NewActiveMaskObjectID m173 : 24|16@1+ (1,0) [0|65535] "" Vector__XXX
 SG_ AttributeID m185 : 24|8@1+ (1,0) [0|16777200] "" Vector__XXX
 SG_ NewPriority m176 : 24|8@1+ (1,0) [0|255] "" Vector__XXX
 SG_ ListIndex m177 : 24|8@1+ (1,0) [0|255] "" Vector__XXX
 SG_ ChangeChildLocationObjectID m165 : 24|16@1+ (1,0) [0|65535] "" Vector__XXX
 SG_ StringVariableObjectID m181 : 24|16@1+ (1,0) [0|65535] "" Vector__XXX
 SG_ IndexOfThePointToReplace m182 : 24|8@1+ (1,0) [0|255] "" Vector__XXX
 SG_ NewWidthAttribute m183 : 24|16@1+ (1,0) [0|65535] "" Vector__XXX
 SG_ SubCommandID m184M : 24|8@1+ (1,0) [0|0] "" Vector__XXX
 SG_ AttributeIDToChange m175 : 24|8@1+ (1,0) [0|0] "" Vector__XXX
 SG_ TotalNumberOfBytes m179 : 24|16@1- (1,0) [0|0] "bytes" Vector__XXX
 SG_ Value1 m33 : 24|16@1+ (1,0) [0|65535] "" Vector__XXX
 SG_ ObjectId_2 m9 : 32|16@1+ (1,0) [0|65535] "" Vector__XXX
 SG_ KeyObjectParentID m0 : 32|16@1+ (1,0) [0|65535] "" Vector__XXX
 SG_ ButtonObjectParentID m1 : 32|16@1+ (1,0) [0|65535] "" Vector__XXX
 SG_ VTChangeNumericValueValue m5 : 32|32@1+ (1,0) [0|4294967295] "" Vector__XXX
 SG_ AuxErrorInvalidInputID m37 : 32|1@1+ (1,0) [0|1] "" Vector__XXX
 SG_ OnTimeDuration_Audio m163 : 32|16@1+ (1,0) [0|65535] "ms" Vector__XXX
 SG_ NewValue m168 : 32|32@1+ (1,0) [0|65535] "" Vector__XXX
 SG_ FontSize m170 : 32|8@1+ (1,0) [0|255] "" Vector__XXX
 SG_ LineWidth m171 : 32|8@1+ (1,0) [0|255] "" Vector__XXX
 SG_ FillColour m172 : 32|8@1+ (1,0) [0|255] "" Vector__XXX
 SG_ NewSoftKeyMaskObjectID m174 : 32|16@1+ (1,0) [0|65535] "" Vector__XXX
 SG_ NewAttributeValue m175 : 32|32@1+ (1,0) [0|0] "" Vector__XXX
 SG_ NewObjectID m177 : 32|16@1+ (1,0) [0|65535] "" Vector__XXX
 SG_ NewValueX m182 : 32|16@1+ (1,0) [0|65535] "" Vector__XXX
 SG_ LockTimeout m189 : 32|16@1+ (1,0) [0|65535] "" Vector__XXX
 SG_ LastWideChar m193 : 32|16@1+ (1,0) [0|65535] "" Vector__XXX
 SG_ PictureGraphicsID_Viewport m20 : 32|16@1+ (1,0) [0|65534] "" Vector__XXX
 SG_ PictureGraphicsID_Canvas m19 : 32|16@1+ (1,0) [0|65534] "" Vector__XXX
 SG_ ObjectID m18 : 32|16@1+ (1,0) [0|65534] "" Vector__XXX
 SG_ NewViewportWidth m17 : 32|16@1+ (1,0) [0|65535] "" Vector__XXX
 SG_ ViewportX_PanZoom m16 : 32|16@1- (1,0) [-32768|32767] "" Vector__XXX
 SG_ ZoomValue m15 : 32|32@1- (1,0) [-32|32] "" Vector__XXX
 SG_ ViewportX m14 : 32|16@1- (1,0) [-32768|32767] "" Vector__XXX
 SG_ TextOption m13 : 32|8@1+ (1,0) [0|1] "" Vector__XXX
 SG_ NumberOfPoints m12 : 32|8@1+ (1,0) [0|255] "" Vector__XXX
 SG_ EllipseWidth m11 : 32|16@1+ (1,0) [0|65535] "" Vector__XXX
 SG_ RectangleWidth_Draw m10 : 32|16@1+ (1,0) [0|65535] "" Vector__XXX
 SG_ EndPixelOffsetX m9 : 32|16@1- (1,0) [-32768|32767] "" Vector__XXX
 SG_ PixelOffsetX m8 : 32|16@1- (1,0) [-32768|32767] "" Vector__XXX
 SG_ RectangleHeight_Erase m7 : 48|16@1+ (1,0) [0|65535] "" Vector__XXX
 SG_ RectangleWidth_Erase m7 : 32|16@1+ (1,0) [0|65535] "" Vector__XXX
 SG_ FontAttributesObjectID m6 : 32|16@1+ (1,0) [0|65535] "" Vector__XXX
 SG_ FillAttributesObjectID m5 : 32|16@1+ (1,0) [0|65535] "" Vector__XXX
 SG_ LineAttributesObjectID m4 : 32|16@1+ (1,0) [0|65535] "" Vector__XXX
 SG_ BackgroundColour m3 : 32|8@1+ (1,0) [0|255] "" Vector__XXX
 SG_ ForegroundColour m2 : 32|8@1+ (1,0) [0|255] "" Vector__XXX
 SG_ CursorOffsetY m1 : 48|16@1- (1,0) [-32768|32767] "" Vector__XXX
 SG_ CursorOffsetX m1 : 32|16@1- (1,0) [-32768|32767] "" Vector__XXX
 SG_ CursorPosX m0 : 32|16@1- (1,0) [-32768|32767] "" Vector__XXX
 SG_ AuxErrorAnyOther m37 : 33|1@1+ (1,0) [0|1] "" Vector__XXX
 SG_ TextLength m13 : 40|8@1+ (1,0) [0|255] "bytes" Vector__XXX
 SG_ TouchState m2 : 40|8@1+ (1,0) [0|255] "" Vector__XXX
 SG_ XPosChangeTopLeft m165 : 40|8@1+ (1,-127) [-127|128] "" Vector__XXX
 SG_ NewHeight m166 : 40|16@1+ (1,0) [0|65535] "" Vector__XXX
 SG_ Height m169 : 40|16@1+ (1,0) [0|65535] "" Vector__XXX
 SG_ LabelFontType m181 : 40|8@1+ (1,0) [0|255] "" Vector__XXX
 SG_ LineArt m171 : 40|16@1+ (1,0) [0|65535] "" Vector__XXX
 SG_ FillPatternObjectID m172 : 40|16@1+ (1,0) [0|65535] "" Vector__XXX
 SG_ XPosChangeTopLeftLong m180 : 40|16@1- (1,0) [-32768|32767] "" Vector__XXX
 SG_ FontType m170 : 40|8@1+ (1,0) [0|255] "" Vector__XXX
 SG_ NewHeigthAttribute m183 : 40|16@1+ (1,0) [0|0] "" Vector__XXX
 SG_ Value2 m33 : 40|16@1+ (1,0) [0|65535] "" Vector__XXX
 SG_ NewStringValue m179 : 40|16@1+ (1,0) [0|65535] "" Vector__XXX
 SG_ CursorPosY m0 : 48|16@1- (1,0) [-32768|32767] "" Vector__XXX
 SG_ PixelOffsetY m8 : 48|16@1- (1,0) [-32768|32767] "" Vector__XXX
 SG_ EndPixelOffsetY m9 : 48|16@1- (1,0) [-32768|32767] "" Vector__XXX
 SG_ RectangleHeight_Draw m10 : 48|16@1+ (1,0) [0|65535] "" Vector__XXX
 SG_ EllipseHeight m11 : 48|16@1+ (1,0) [0|65535] "" Vector__XXX
 SG_ ViewportY m14 : 48|16@1- (1,0) [-32768|32767] "" Vector__XXX
 SG_ ViewportY_PanZoom m16 : 48|16@1- (1,0) [-32768|32767] "" Vector__XXX
 SG_ NewViewportHeight m17 : 48|16@1+ (1,0) [0|65535] "" Vector__XXX
 SG_ Status_2 m9 : 48|8@1+ (1,0) [0|1] "" Vector__XXX
 SG_ SoftKeyCode m0 : 48|8@1+ (1,0) [0|255] "" Vector__XXX
 SG_ ButtonKeyCode m1 : 48|8@1+ (1,0) [0|255] "" Vector__XXX
 SG_ OffTimeDuration_Audio m163 : 48|16@1+ (1,0) [0|65535] "ms" Vector__XXX
 SG_ YPosChangeTopLeft m165 : 48|8@1+ (1,-127) [-127|128] "" Vector__XXX
 SG_ FontStyle m170 : 48|8@1+ (1,0) [0|255] "" Vector__XXX
 SG_ GraphicRepresentationObjectID m181 : 48|16@1+ (1,0) [0|255] "" Vector__XXX
 SG_ NewValueY m182 : 48|16@1+ (1,0) [0|65535] "" Vector__XXX
 SG_ LineDirection m169 : 56|8@1+ (1,0) [0|1] "" Vector__XXX
 SG_ YPosChangeTopLeftLong m180 : 56|16@1- (1,0) [-32768|32767] "" Vector__XXX
 SG_ OperatingState1 m33 : 56|1@1+ (1,0) [0|1] "" Vector__XXX
 SG_ OperatingState2 m33 : 57|1@1+ (1,0) [0|1] "" Vector__XXX
 SG_ ZoomValue_PanZoom m16 : 64|32@1- (1,0) [-32|32] "" Vector__XXX
 SG_ ModelIdentificationCode m34 : 80|16@1+ (1,0) [0|65535] "" Vector__XXX
 SG_ NumOfPreferredFunctions m34 : 96|8@1- (1,0) [0|255] "" Vector__XXX
 SG_ AuxiliaryFunctionID_1 m34 : 104|16@1+ (1,0) [0|65535] "" Vector__XXX
 SG_ AuxiliaryInputID_1 m34 : 120|16@1+ (1,0) [0|65535] "" Vector__XXX

BO_ 2565406462 ACKM: 8 Vector__XXX
 SG_ ControlByte M : 0|8@1+ (1,0) [0|255] "" Vector__XXX
 SG_ GroupFunctionValue : 8|8@1+ (1,0) [0|255] "" Vector__XXX
 SG_ AddressAcknowledged m0 : 32|8@1+ (1,0) [0|255] "" Vector__XXX
 SG_ AddressNegativeAcknowledgement m1 : 32|8@1+ (1,0) [0|255] "" Vector__XXX
 SG_ AddressAccessDenied m2 : 32|8@1+ (1,0) [0|255] "" Vector__XXX
 SG_ AddressBusy m3 : 32|8@1+ (1,0) [0|255] "" Vector__XXX
 SG_ ParameterGroupNumber : 40|24@1+ (1,0) [0|16777215] "" Vector__XXX

BO_ 2565537534 RQST: 3 Vector__XXX
 SG_ ParameterGroupNumber : 0|24@1+ (1,0) [0|16777215] "" Vector__XXX

BO_ 2632711934 TPDT: 8 Vector__XXX
 SG_ SequenceNumber : 0|8@1+ (1,0) [0|255] "" Vector__XXX

BO_ 2632777470 TPCM: 8 Vector__XXX
 SG_ ControlByte M : 0|8@1+ (1,0) [0|255] "" Vector__XXX
 SG_ TotalMessageSizeEoMA m19 : 8|16@1+ (1,0) [0|64255] "counts" Vector__XXX
 SG_ TotalMessageSizeBAM m32 : 8|16@1+ (1,0) [0|64255] "counts" Vector__XXX
 SG_ TotalMessageSize m16 : 8|16@1+ (1,0) [0|64255] "counts" Vector__XXX
 SG_ NumberOfPacketsThatCanBeSent m17 : 8|8@1+ (1,0) [0|255] "" Vector__XXX
 SG_ ConnectionAbortReason m255 : 8|8@1+ (1,0) [0|255] "" Vector__XXX
 SG_ NextPacketNumberToBeSent m17 : 16|8@1+ (1,0) [0|255] "" Vector__XXX
 SG_ TotalNumberOfPacketsEoMA m19 : 24|8@1+ (1,0) [0|255] "" Vector__XXX
 SG_ TotalNumberOfPacketsBAM m32 : 24|8@1+ (1,0) [0|255] "" Vector__XXX
 SG_ TotalNumberOfPackets m16 : 24|8@1+ (1,0) [0|255] "" Vector__XXX
 SG_ MaximumNumberOfPackets m16 : 32|8@1+ (1,0) [0|255] "" Vector__XXX
 SG_ PGNumber : 40|24@1+ (1,0) [0|16777200] "" Vector__XXX

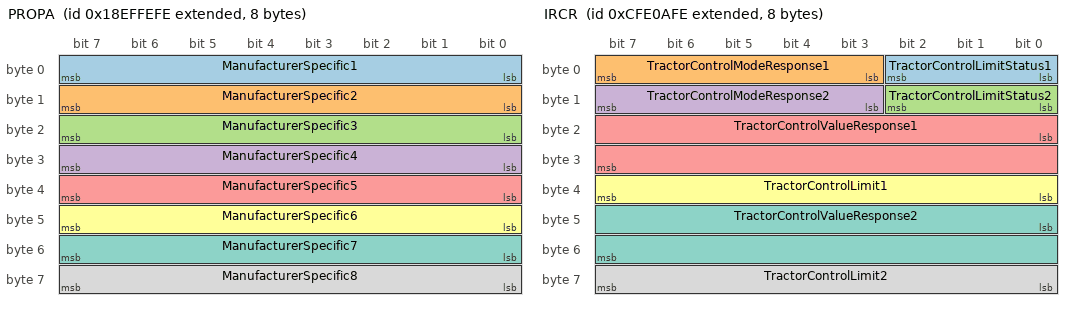
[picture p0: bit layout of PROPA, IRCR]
BO_ 2565865214 PROPA: 8 Vector__XXX
 SG_ ManufacturerSpecific1 : 0|8@1+ (1,0) [0|255] "" Vector__XXX
 SG_ ManufacturerSpecific2 : 8|8@1+ (1,0) [0|255] "" Vector__XXX
 SG_ ManufacturerSpecific3 : 16|8@1+ (1,0) [0|255] "" Vector__XXX
 SG_ ManufacturerSpecific4 : 24|8@1+ (1,0) [0|255] "" Vector__XXX
 SG_ ManufacturerSpecific5 : 32|8@1+ (1,0) [0|255] "" Vector__XXX
 SG_ ManufacturerSpecific6 : 40|8@1+ (1,0) [0|255] "" Vector__XXX
 SG_ ManufacturerSpecific7 : 48|8@1+ (1,0) [0|255] "" Vector__XXX
 SG_ ManufacturerSpecific8 : 56|8@1+ (1,0) [0|255] "" Vector__XXX

BO_ 2365458686 RTF: 8 Vector__XXX
 SG_ SpeedInfo_EngineSpeed : 0|1@1+ (1,0) [0|1] "" Vector__XXX
 SG_ SpeedInfo_GroundBasedSpeed : 1|1@1+ (1,0) [0|1] "" Vector__XXX
 SG_ SpeedInfo_WheelBasedSpeed : 2|1@1+ (1,0) [0|1] "" Vector__XXX
 SG_ PowerMgt_MaintainPower : 3|1@1+ (1,0) [0|1] "" Vector__XXX
 SG_ PowerMgt_MaxTimeTractorPower : 4|1@1+ (1,0) [0|1] "" Vector__XXX
 SG_ PowerMgt_KeySwitch : 5|1@1+ (1,0) [0|1] "" Vector__XXX
 SG_ TractorClass : 6|2@1+ (1,0) [0|3] "" Vector__XXX
 SG_ LanguageCmdStorageInTractorECU : 10|1@1+ (1,0) [0|1] "" Vector__XXX
 SG_ Lighting_MinimalSet : 11|1@1+ (1,0) [0|1] "" Vector__XXX
 SG_ PTOInfo_RearShaftEngagement : 12|1@1+ (1,0) [0|0] "" Vector__XXX
 SG_ PTOInfo_RearShaftSpeed : 13|1@1+ (1,0) [0|1] "" Vector__XXX
 SG_ HitchInfo_RearInWork : 14|1@1+ (1,0) [0|1] "" Vector__XXX
 SG_ HitchInfo_RearPosition : 15|1@1+ (1,0) [0|1] "" Vector__XXX
 SG_ EstimatedOrMeasuredAuxValveState : 16|1@1+ (1,0) [0|1] "" Vector__XXX
 SG_ Light_FullImplLightingMessageSet : 17|1@1+ (1,0) [0|1] "" Vector__XXX
 SG_ AddHitchParameter_RearDraft : 18|1@1+ (1,0) [0|1] "" Vector__XXX
 SG_ SpeedAndDist_WheelBasedDirection : 19|1@1+ (1,0) [0|1] "" Vector__XXX
 SG_ SpeedAndDist_WheelBasedDistance : 20|1@1+ (1,0) [0|1] "" Vector__XXX
 SG_ SpeedAndDist_GndBasedDirection : 21|1@1+ (1,0) [0|1] "" Vector__XXX
 SG_ SpeedAndDist_GndBasedDistance : 22|1@1+ (1,0) [0|1] "" Vector__XXX
 SG_ TimeDate : 23|1@1+ (1,0) [0|1] "" Vector__XXX
 SG_ LimitStatusReporting : 27|1@1+ (1,0) [0|0] "" Vector__XXX
 SG_ AuxiliaryValveCmd : 28|1@1+ (1,0) [0|1] "" Vector__XXX
 SG_ PTOCmd_RearPTOEngagementCmd : 29|1@1+ (1,0) [0|1] "" Vector__XXX
 SG_ PTOCmd_RearPTOSpeedCmd : 30|1@1+ (1,0) [0|1] "" Vector__XXX
 SG_ HitchCmd_RearHitchPosition : 31|1@1+ (1,0) [0|1] "" Vector__XXX
 SG_ DirectionControl : 32|1@1+ (1,0) [0|1] "" Vector__XXX
 SG_ SelectedMachineSpeedControl : 33|1@1+ (1,0) [0|1] "" Vector__XXX
 SG_ SelectedMachineSpeed : 34|1@1+ (1,0) [0|1] "" Vector__XXX
 SG_ OperatorExternalLightControls : 35|1@1+ (1,0) [0|1] "" Vector__XXX
 SG_ NavigPseudorangeNoiseStatistic : 37|1@1+ (1,0) [0|1] "" Vector__XXX
 SG_ NavigSystemPositionData : 38|1@1+ (1,0) [0|1] "" Vector__XXX
 SG_ NavigSystemHighOutputPosition : 39|1@1+ (1,0) [0|1] "" Vector__XXX
 SG_ PTOCmd_FrontPTOEngagementCmd : 40|1@1+ (1,0) [0|1] "" Vector__XXX
 SG_ PTOCmd_FrontPTOSpeedCmd : 41|1@1+ (1,0) [0|1] "" Vector__XXX
 SG_ HitchCmd_FrontHitchPosition : 42|1@1+ (1,0) [0|1] "" Vector__XXX
 SG_ AddHitchParameter__FrontDraft : 43|1@1+ (1,0) [0|1] "" Vector__XXX
 SG_ PTOInfo_FrontShaftEngagement : 44|1@1+ (1,0) [0|1] "" Vector__XXX
 SG_ PTOInfo_FrontShaftSpeed : 45|1@1+ (1,0) [0|1] "" Vector__XXX
 SG_ HitchInfo_FrontInWork : 46|1@1+ (1,0) [0|1] "" Vector__XXX
 SG_ HitchInfo_FrontPosition : 47|1@1+ (1,0) [0|1] "" Vector__XXX
 SG_ ReservedBitIndicator : 56|1@1- (1,0) [0|1] "" Vector__XXX

BO_ 2365458942 TFR: 8 Vector__XXX
 SG_ SpeedInfo_EngineSpeed : 0|1@1+ (1,0) [0|1] "" Vector__XXX
 SG_ SpeedInfo_GroundBasedSpeed : 1|1@1+ (1,0) [0|1] "" Vector__XXX
 SG_ SpeedInfo_WheelBasedSpeed : 2|1@1+ (1,0) [0|1] "" Vector__XXX
 SG_ PowerMgt_MaintainPower : 3|1@1+ (1,0) [0|1] "" Vector__XXX
 SG_ PowerMgt_MaxTimeTractorPower : 4|1@1+ (1,0) [0|1] "" Vector__XXX
 SG_ PowerMgt_KeySwitch : 5|1@1+ (1,0) [0|1] "" Vector__XXX
 SG_ TractorClass : 6|2@1+ (1,0) [0|3] "" Vector__XXX
 SG_ LanguageCmdStorageInTractorECU : 10|1@1+ (1,0) [0|1] "" Vector__XXX
 SG_ Lighting_MinimalSet : 11|1@1+ (1,0) [0|1] "" Vector__XXX
 SG_ PTOInfo_RearShaftEngagement : 12|1@1+ (1,0) [0|0] "" Vector__XXX
 SG_ PTOInfo_RearShaftSpeed : 13|1@1+ (1,0) [0|1] "" Vector__XXX
 SG_ HitchInfo_RearInWork : 14|1@1+ (1,0) [0|1] "" Vector__XXX
 SG_ HitchInfo_RearPosition : 15|1@1+ (1,0) [0|1] "" Vector__XXX
 SG_ EstimatedOrMeasuredAuxValveState : 16|1@1+ (1,0) [0|1] "" Vector__XXX
 SG_ Light_FullImplLightingMessageSet : 17|1@1+ (1,0) [0|1] "" Vector__XXX
 SG_ AddHitchParameter_RearDraft : 18|1@1+ (1,0) [0|1] "" Vector__XXX
 SG_ SpeedAndDist_WheelBasedDirection : 19|1@1+ (1,0) [0|1] "" Vector__XXX
 SG_ SpeedAndDist_WheelBasedDistance : 20|1@1+ (1,0) [0|1] "" Vector__XXX
 SG_ SpeedAndDist_GndBasedDirection : 21|1@1+ (1,0) [0|1] "" Vector__XXX
 SG_ SpeedAndDist_GndBasedDistance : 22|1@1+ (1,0) [0|1] "" Vector__XXX
 SG_ TimeDate : 23|1@1+ (1,0) [0|1] "" Vector__XXX
 SG_ LimitStatusReporting : 27|1@1+ (1,0) [0|0] "" Vector__XXX
 SG_ AuxiliaryValveCmd : 28|1@1+ (1,0) [0|1] "" Vector__XXX
 SG_ PTOCmd_RearPTOEngagementCmd : 29|1@1+ (1,0) [0|1] "" Vector__XXX
 SG_ PTOCmd_RearPTOSpeedCmd : 30|1@1+ (1,0) [0|1] "" Vector__XXX
 SG_ HitchCmd_RearHitchPosition : 31|1@1+ (1,0) [0|1] "" Vector__XXX
 SG_ NavigPseudorangeNoiseStatistic : 37|1@1+ (1,0) [0|1] "" Vector__XXX
 SG_ NavigSystemPositionData : 38|1@1+ (1,0) [0|1] "" Vector__XXX
 SG_ NavigSystemHighOutputPosition : 39|1@1+ (1,0) [0|1] "" Vector__XXX
 SG_ PTOCmd_FrontPTOEngagementCmd : 40|1@1+ (1,0) [0|1] "" Vector__XXX
 SG_ PTOCmd_FrontPTOSpeedCmd : 41|1@1+ (1,0) [0|1] "" Vector__XXX
 SG_ HitchCmd_FrontHitchPosition : 42|1@1+ (1,0) [0|1] "" Vector__XXX
 SG_ AddHitchParameter__FrontDraft : 43|1@1+ (1,0) [0|1] "" Vector__XXX
 SG_ PTOInfo_FrontShaftEngagement : 44|1@1+ (1,0) [0|1] "" Vector__XXX
 SG_ PTOInfo_FrontShaftSpeed : 45|1@1+ (1,0) [0|1] "" Vector__XXX
 SG_ HitchInfo_FrontInWork : 46|1@1+ (1,0) [0|1] "" Vector__XXX
 SG_ HitchInfo_FrontPosition : 47|1@1+ (1,0) [0|1] "" Vector__XXX
 SG_ ReservedBitIndicator : 56|1@1- (1,0) [0|1] "" Vector__XXX

BO_ 2365459198 IRCR: 8 Vector__XXX
 SG_ TractorControlLimitStatus1 : 0|3@1+ (1,0) [0|7] "" Vector__XXX
 SG_ TractorControlModeResponse1 : 3|5@1+ (1,0) [0|31] "" Vector__XXX
 SG_ TractorControlLimitStatus2 : 8|3@1+ (1,0) [0|7] "" Vector__XXX
 SG_ TractorControlModeResponse2 : 11|5@1+ (1,0) [0|31] "" Vector__XXX
 SG_ TractorControlValueResponse1 : 16|16@1+ (1,0) [0|0] "" Vector__XXX
 SG_ TractorControlLimit1 : 32|8@1- (1,0) [0|0] "" Vector__XXX
 SG_ TractorControlValueResponse2 : 40|16@1+ (1,0) [0|0] "" Vector__XXX
 SG_ TractorControlLimit2 : 56|8@1- (1,0) [0|0] "" Vector__XXX

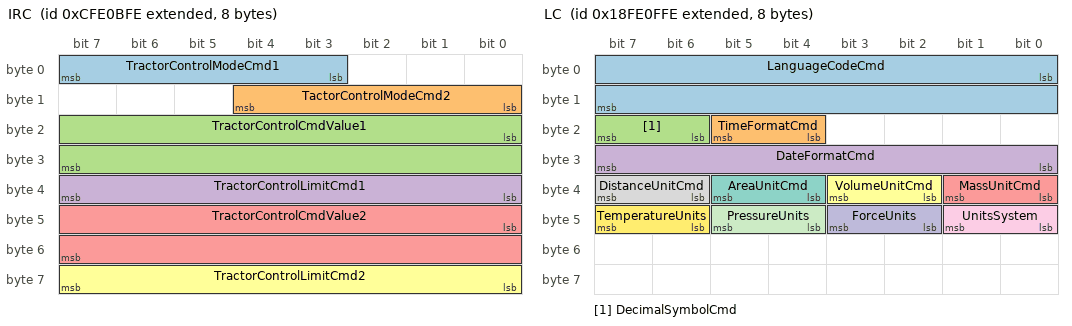
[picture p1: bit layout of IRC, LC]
BO_ 2365459454 IRC: 8 Vector__XXX
 SG_ TractorControlModeCmd1 : 3|5@1+ (1,0) [0|31] "" Vector__XXX
 SG_ TactorControlModeCmd2 : 8|5@1+ (1,0) [0|31] "" Vector__XXX
 SG_ TractorControlCmdValue1 : 16|16@1+ (1,0) [0|0] "" Vector__XXX
 SG_ TractorControlLimitCmd1 : 32|8@1- (1,0) [0|0] "" Vector__XXX
 SG_ TractorControlCmdValue2 : 40|16@1+ (1,0) [0|0] "" Vector__XXX
 SG_ TractorControlLimitCmd2 : 56|8@1- (1,0) [0|0] "" Vector__XXX

BO_ 2633895166 WSMEM: 8 Vector__XXX
 SG_ VehicleSystemInstance m0 : 56|4@1+ (1,0) [0|15] "" Vector__XXX
 SG_ VehicleSystem5 m5 : 49|7@1+ (1,0) [0|127] "" Vector__XXX
 SG_ VehicleSystem4 m4 : 49|7@1+ (1,0) [0|127] "" Vector__XXX
 SG_ VehicleSystem3 m3 : 49|7@1+ (1,0) [0|127] "" Vector__XXX
 SG_ VehicleSystem2 m2 : 49|7@1+ (1,0) [0|127] "" Vector__XXX
 SG_ VehicleSystem1 m1 : 49|7@1+ (1,0) [0|127] "" Vector__XXX
 SG_ VehicleSystem m0 : 49|7@1+ (1,0) [0|127] "" Vector__XXX
 SG_ ManufacturerCode : 21|11@1+ (1,0) [0|2047] "" Vector__XXX
 SG_ IndustryGroup M : 60|3@1+ (1,0) [0|7] "" Vector__XXX
 SG_ IdentityNumber : 0|21@1+ (1,0) [0|2097152] "" Vector__XXX
 SG_ FunctionInstance : 35|5@1+ (1,0) [0|31] "" Vector__XXX
 SG_ Function : 40|8@1+ (1,0) [0|255] "" Vector__XXX
 SG_ ECUInstance : 32|3@1+ (1,0) [0|7] "" Vector__XXX
 SG_ ArbitraryAddressCapable : 63|1@1+ (1,0) [0|1] "" Vector__XXX

BO_ 2633895422 WSMSTR: 8 OPC
 SG_ NumberOfMembers : 0|8@1+ (1,0) [0|0] "" Vector__XXX

BO_ 2566786814 RESRR: 8 Vector__XXX
 SG_ PGN : 0|24@1+ (1,0) [0|16777200] "" Vector__XXX
 SG_ ActualRepetitionRate : 24|16@1+ (1,0) [0|64255] "ms" Vector__XXX

BO_ 2566787070 LC: 8 Vector__XXX
 SG_ LanguageCodeCmd : 0|16@1+ (1,0) [0|16383] "" Vector__XXX
 SG_ TimeFormatCmd : 20|2@1+ (1,0) [0|3] "" Vector__XXX
 SG_ DecimalSymbolCmd : 22|2@1+ (1,0) [0|3] "" Vector__XXX
 SG_ DateFormatCmd : 24|8@1+ (1,0) [0|255] "" Vector__XXX
 SG_ MassUnitCmd : 32|2@1+ (1,0) [0|3] "" Vector__XXX
 SG_ VolumeUnitCmd : 34|2@1+ (1,0) [0|3] "" Vector__XXX
 SG_ AreaUnitCmd : 36|2@1+ (1,0) [0|3] "" Vector__XXX
 SG_ DistanceUnitCmd : 38|2@1+ (1,0) [0|3] "" Vector__XXX
 SG_ UnitsSystem : 40|2@1+ (1,0) [0|3] "" Vector__XXX
 SG_ ForceUnits : 42|2@1+ (1,0) [0|3] "" Vector__XXX
 SG_ PressureUnits : 44|2@1+ (1,0) [0|3] "" Vector__XXX
 SG_ TemperatureUnits : 46|2@1+ (1,0) [0|3] "" Vector__XXX

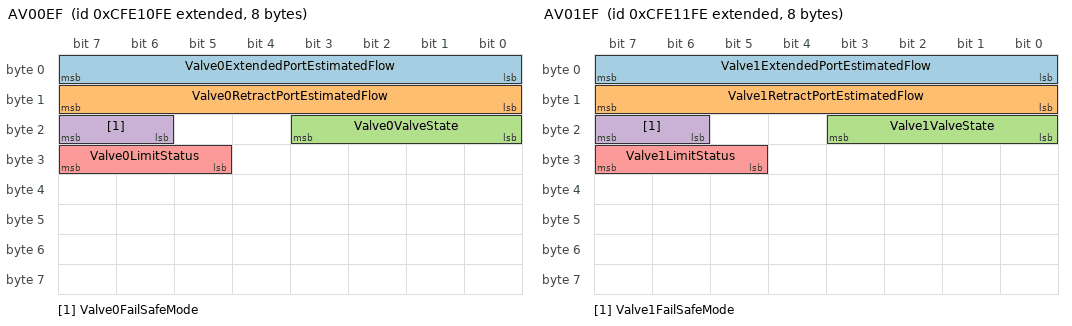
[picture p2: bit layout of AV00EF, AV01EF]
BO_ 2365460734 AV00EF: 8 Vector__XXX
 SG_ Valve0ExtendedPortEstimatedFlow : 0|8@1+ (1,-125) [-125|125] "%" Vector__XXX
 SG_ Valve0RetractPortEstimatedFlow : 8|8@1+ (1,-125) [-125|125] "%" Vector__XXX
 SG_ Valve0ValveState : 16|4@1+ (1,0) [0|15] "" Vector__XXX
 SG_ Valve0FailSafeMode : 22|2@1+ (1,0) [0|3] "" Vector__XXX
 SG_ Valve0LimitStatus : 29|3@1+ (1,0) [0|7] "" Vector__XXX

BO_ 2365460990 AV01EF: 8 Vector__XXX
 SG_ Valve1ExtendedPortEstimatedFlow : 0|8@1+ (1,-125) [-125|125] "%" Vector__XXX
 SG_ Valve1RetractPortEstimatedFlow : 8|8@1+ (1,-125) [-125|125] "%" Vector__XXX
 SG_ Valve1ValveState : 16|4@1+ (1,0) [0|15] "" Vector__XXX
 SG_ Valve1FailSafeMode : 22|2@1+ (1,0) [0|3] "" Vector__XXX
 SG_ Valve1LimitStatus : 29|3@1+ (1,0) [0|7] "" Vector__XXX

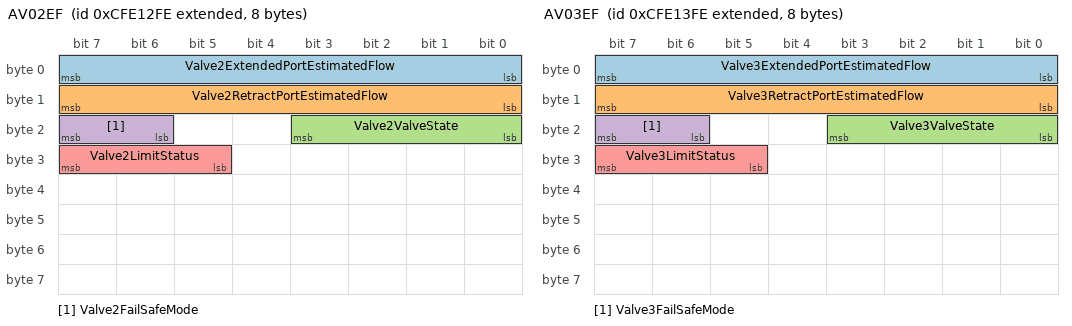
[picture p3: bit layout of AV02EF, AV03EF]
BO_ 2365461246 AV02EF: 8 Vector__XXX
 SG_ Valve2ExtendedPortEstimatedFlow : 0|8@1+ (1,-125) [-125|125] "%" Vector__XXX
 SG_ Valve2RetractPortEstimatedFlow : 8|8@1+ (1,-125) [-125|125] "%" Vector__XXX
 SG_ Valve2ValveState : 16|4@1+ (1,0) [0|15] "" Vector__XXX
 SG_ Valve2FailSafeMode : 22|2@1+ (1,0) [0|3] "" Vector__XXX
 SG_ Valve2LimitStatus : 29|3@1+ (1,0) [0|7] "" Vector__XXX

BO_ 2365461502 AV03EF: 8 Vector__XXX
 SG_ Valve3ExtendedPortEstimatedFlow : 0|8@1+ (1,-125) [-125|125] "%" Vector__XXX
 SG_ Valve3RetractPortEstimatedFlow : 8|8@1+ (1,-125) [-125|125] "%" Vector__XXX
 SG_ Valve3ValveState : 16|4@1+ (1,0) [0|15] "" Vector__XXX
 SG_ Valve3FailSafeMode : 22|2@1+ (1,0) [0|3] "" Vector__XXX
 SG_ Valve3LimitStatus : 29|3@1+ (1,0) [0|7] "" Vector__XXX

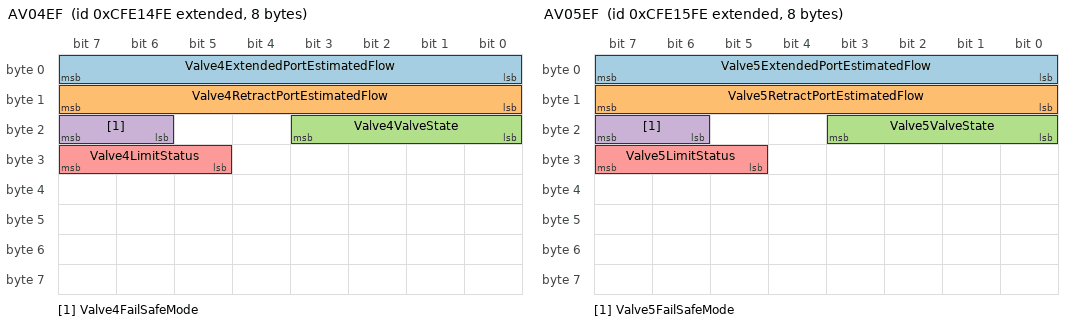
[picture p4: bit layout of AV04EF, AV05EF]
BO_ 2365461758 AV04EF: 8 Vector__XXX
 SG_ Valve4ExtendedPortEstimatedFlow : 0|8@1+ (1,-125) [-125|125] "%" Vector__XXX
 SG_ Valve4RetractPortEstimatedFlow : 8|8@1+ (1,-125) [-125|125] "%" Vector__XXX
 SG_ Valve4ValveState : 16|4@1+ (1,0) [0|15] "" Vector__XXX
 SG_ Valve4FailSafeMode : 22|2@1+ (1,0) [0|3] "" Vector__XXX
 SG_ Valve4LimitStatus : 29|3@1+ (1,0) [0|7] "" Vector__XXX

BO_ 2365462014 AV05EF: 8 Vector__XXX
 SG_ Valve5ExtendedPortEstimatedFlow : 0|8@1+ (1,-125) [-125|125] "%" Vector__XXX
 SG_ Valve5RetractPortEstimatedFlow : 8|8@1+ (1,-125) [-125|125] "%" Vector__XXX
 SG_ Valve5ValveState : 16|4@1+ (1,0) [0|15] "" Vector__XXX
 SG_ Valve5FailSafeMode : 22|2@1+ (1,0) [0|3] "" Vector__XXX
 SG_ Valve5LimitStatus : 29|3@1+ (1,0) [0|7] "" Vector__XXX

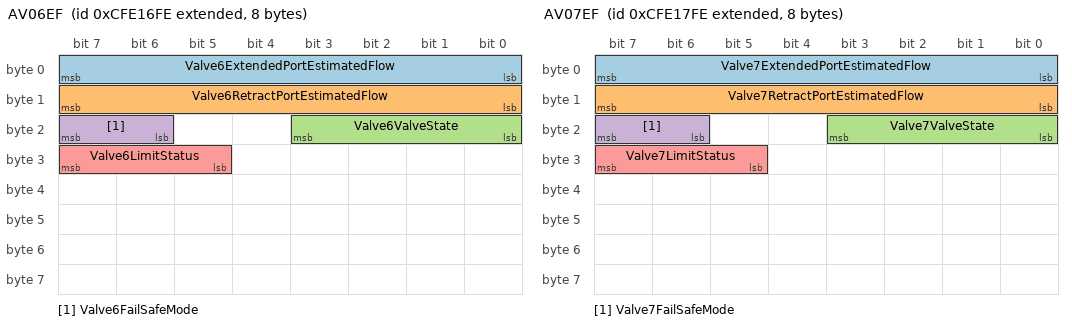
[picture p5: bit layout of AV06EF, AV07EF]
BO_ 2365462270 AV06EF: 8 Vector__XXX
 SG_ Valve6ExtendedPortEstimatedFlow : 0|8@1+ (1,-125) [-125|125] "%" Vector__XXX
 SG_ Valve6RetractPortEstimatedFlow : 8|8@1+ (1,-125) [-125|125] "%" Vector__XXX
 SG_ Valve6ValveState : 16|4@1+ (1,0) [0|15] "" Vector__XXX
 SG_ Valve6FailSafeMode : 22|2@1+ (1,0) [0|3] "" Vector__XXX
 SG_ Valve6LimitStatus : 29|3@1+ (1,0) [0|7] "" Vector__XXX

BO_ 2365462526 AV07EF: 8 Vector__XXX
 SG_ Valve7ExtendedPortEstimatedFlow : 0|8@1+ (1,-125) [-125|125] "%" Vector__XXX
 SG_ Valve7RetractPortEstimatedFlow : 8|8@1+ (1,-125) [-125|125] "%" Vector__XXX
 SG_ Valve7ValveState : 16|4@1+ (1,0) [0|15] "" Vector__XXX
 SG_ Valve7FailSafeMode : 22|2@1+ (1,0) [0|3] "" Vector__XXX
 SG_ Valve7LimitStatus : 29|3@1+ (1,0) [0|7] "" Vector__XXX

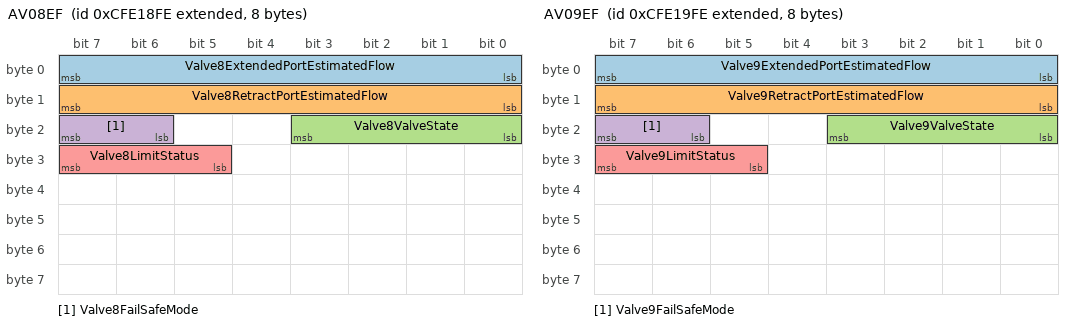
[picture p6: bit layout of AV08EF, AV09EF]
BO_ 2365462782 AV08EF: 8 Vector__XXX
 SG_ Valve8ExtendedPortEstimatedFlow : 0|8@1+ (1,-125) [-125|125] "%" Vector__XXX
 SG_ Valve8RetractPortEstimatedFlow : 8|8@1+ (1,-125) [-125|125] "%" Vector__XXX
 SG_ Valve8ValveState : 16|4@1+ (1,0) [0|15] "" Vector__XXX
 SG_ Valve8FailSafeMode : 22|2@1+ (1,0) [0|3] "" Vector__XXX
 SG_ Valve8LimitStatus : 29|3@1+ (1,0) [0|7] "" Vector__XXX

BO_ 2365463038 AV09EF: 8 Vector__XXX
 SG_ Valve9ExtendedPortEstimatedFlow : 0|8@1+ (1,-125) [-125|125] "%" Vector__XXX
 SG_ Valve9RetractPortEstimatedFlow : 8|8@1+ (1,-125) [-125|125] "%" Vector__XXX
 SG_ Valve9ValveState : 16|4@1+ (1,0) [0|15] "" Vector__XXX
 SG_ Valve9FailSafeMode : 22|2@1+ (1,0) [0|3] "" Vector__XXX
 SG_ Valve9LimitStatus : 29|3@1+ (1,0) [0|7] "" Vector__XXX

CM_ BO_ 2632384254 "VT to ECU";
CM_ SG_ 2632384254 AnalogValue "Analog value of 0xFFFF if input type is boolean";
CM_ SG_ 2632384254 AuxInputEnable "Auxiliary Input Enable";
CM_ SG_ 2632384254 ErrorCodeAnyOtherError "VT change mask error code: Any other error";
CM_ SG_ 2632384254 ErrorCodePoolDeleted "VT change mask error code: Pool being deleted";
CM_ SG_ 2632384254 NumTransitionsDisabledToEnabled "Number of transitions of disabled to enabled";
CM_ SG_ 2632384254 VTChangeActiveMaskErrorID "Object ID containing error";
CM_ SG_ 2632384254 VTChangeActiveMaskParentID "Parent object ID of error object ID";
CM_ SG_ 2632384254 AuxiliaryFunctionType "Auxiliary function type of assigned auxiliary input";
CM_ BO_ 2565340926 "ECU to VT";
CM_ SG_ 2565340926 AuxModelIdentification "Model Identification Code of the Auxiliary Input Unit";
CM_ SG_ 2565340926 AuxInputEnable "Auxiliary Input Enable";
CM_ SG_ 2565340926 AuxErrorInvalidInputID "Invalid Auxiliary Input Object ID";
CM_ SG_ 2565340926 AuxErrorAnyOther "Any other error";
CM_ BO_ 2565406462 "Acknowledgment Message";
CM_ SG_ 2565406462 ParameterGroupNumber "PGN which is requested by the Request message";
CM_ BO_ 2565537534 "Request";
CM_ SG_ 2565537534 ParameterGroupNumber "PGN which is requested by the Request message";
CM_ BO_ 2632711934 "Transport Protocol - Data Transfer";
CM_ BO_ 2632777470 "Transport Protocol - Connection Management";
CM_ SG_ 2632777470 NumberOfPacketsThatCanBeSent "Number of Packets that can be sent (TP.CM_CTS)";
CM_ SG_ 2632777470 ConnectionAbortReason "Reason for connection abort message.";
CM_ SG_ 2632777470 NextPacketNumberToBeSent "Next Packet Number to be sent (TP.CM_CTS)";
CM_ SG_ 2632777470 MaximumNumberOfPackets "Maximum number of packets for RTS/CTS message.";
CM_ BO_ 2565865214 "Proprietary A";
CM_ BO_ 2365458686 "Required Tractor Facilities message";
CM_ SG_ 2365458686 LimitStatusReporting "Parameter used to respond to a request of a facility of a tractor ECU";
CM_ SG_ 2365458686 DirectionControl "Parameter used to respond to a request of a facility of a tractor ECU";
CM_ SG_ 2365458686 SelectedMachineSpeedControl "Parameter used to respond to a request of a facility of a tractor ECU";
CM_ SG_ 2365458686 SelectedMachineSpeed "Parameter used to respond to a request of a facility of a tractor ECU";
CM_ SG_ 2365458686 OperatorExternalLightControls "Parameter used to respond to a request of a facility of a tractor ECU";
CM_ BO_ 2365458942 "Tractor Facilities response message";
CM_ SG_ 2365458942 LimitStatusReporting "Parameter used to respond to a request of a facility of a tractor ECU";
CM_ BO_ 2365459198 "Tractor control command tractor response (previoulsy: Implement remote control command Tractor response)";
CM_ SG_ 2365459198 TractorControlLimitStatus1 "Parameter used to report the tractor ECUs present limit status associated with a parameter whose commands are persistent";
CM_ SG_ 2365459198 TractorControlLimitStatus2 "Parameter used to report the tractor ECUs present limit status associated with a parameter whose commands are persistent";
CM_ BO_ 2365459454 "Tractor control mode command (previously: Implement remote control command)";
CM_ BO_ 2633895166 "Working Set Member";
CM_ BO_ 2633895422 "Working Set Master";
CM_ BO_ 2566786814 "Response for Repetition Rate";
CM_ BO_ 2566787070 "Language Command";
CM_ BO_ 2365460734 "Esimated flow of auxiliary valve number 0 ";
CM_ SG_ 2365460734 Valve0LimitStatus "Parameter used to report the tractor ECUs present limit status associated with a parameter whose commands are persistent";
CM_ BO_ 2365460990 "Esimated flow of auxiliary valve number 0 ";
CM_ SG_ 2365460990 Valve1LimitStatus "Parameter used to report the tractor ECUs present limit status associated with a parameter whose commands are persistent";
CM_ BO_ 2365461246 "Esimated flow of auxiliary valve number 0 ";
CM_ SG_ 2365461246 Valve2LimitStatus "Parameter used to report the tractor ECUs present limit status associated with a parameter whose commands are persistent";
CM_ BO_ 2365461502 "Esimated flow of auxiliary valve number 0 ";
CM_ SG_ 2365461502 Valve3LimitStatus "Parameter used to report the tractor ECUs present limit status associated with a parameter whose commands are persistent";
CM_ BO_ 2365461758 "Esimated flow of auxiliary valve number 0 ";
CM_ SG_ 2365461758 Valve4LimitStatus "Parameter used to report the tractor ECUs present limit status associated with a parameter whose commands are persistent";
CM_ BO_ 2365462014 "Esimated flow of auxiliary valve number 0 ";
CM_ SG_ 2365462014 Valve5LimitStatus "Parameter used to report the tractor ECUs present limit status associated with a parameter whose commands are persistent";
CM_ BO_ 2365462270 "Esimated flow of auxiliary valve number 0 ";
CM_ SG_ 2365462270 Valve6LimitStatus "Parameter used to report the tractor ECUs present limit status associated with a parameter whose commands are persistent";
CM_ BO_ 2365462526 "Esimated flow of auxiliary valve number 0 ";
CM_ SG_ 2365462526 Valve7LimitStatus "Parameter used to report the tractor ECUs present limit status associated with a parameter whose commands are persistent";
CM_ BO_ 2365462782 "Esimated flow of auxiliary valve number 0 ";
CM_ SG_ 2365462782 Valve8LimitStatus "Parameter used to report the tractor ECUs present limit status associated with a parameter whose commands are persistent";
CM_ BO_ 2365463038 "Esimated flow of auxiliary valve number 0 ";
CM_ SG_ 2365463038 Valve9LimitStatus "Parameter used to report the tractor ECUs present limit status associated with a parameter whose commands are persistent";
BA_DEF_ SG_  "GenSigStartValue" INT -2147483648 2147483647;
BA_DEF_ SG_  "SigType" ENUM  "Default","Range","RangeSigned","ASCII","Discrete","Control","ReferencePGN","DTC","StringDelimiter","StringLength","StringLengthControl";
BA_DEF_ SG_  "GenSigSendType" ENUM  "Cyclic","OnWrite","OnWriteWithRepetition","OnChange","OnChangeWithRepetition","IfActive","IfActiveWithRepetition","NoSigSendType";
BA_DEF_ SG_  "SPN" INT 0 524287;
BA_DEF_ BO_  "GenMsgCycleTimeFast" INT 0 3600000;
BA_DEF_ BO_  "GenMsgRequestable" INT 0 1;
BA_DEF_ BO_  "GenMsgCycleTime" INT 0 3600000;
BA_DEF_ BO_  "GenMsgSendType" ENUM  "cyclic","NotUsed","IfActive","NotUsed","NotUsed","NotUsed","NotUsed","NotUsed","noMsgSendType","vector_leerstring";
BA_DEF_ BO_  "VFrameFormat" ENUM  "StandardCAN","ExtendedCAN","reserved","J1939PG","vector_leerstring";
BA_DEF_ BO_  "SingleFrame" INT 0 1;
BA_DEF_ SG_  "DDI" INT 0 65535;
BA_DEF_ SG_  "SystemSignalLongSymbol" STRING ;
BA_DEF_DEF_  "GenSigStartValue" 0;
BA_DEF_DEF_  "SigType" "Default";
BA_DEF_DEF_  "GenSigSendType" "NoSigSendType";
BA_DEF_DEF_  "SPN" 0;
BA_DEF_DEF_  "GenMsgCycleTimeFast" 0;
BA_DEF_DEF_  "GenMsgRequestable" 1;
BA_DEF_DEF_  "GenMsgCycleTime" 0;
BA_DEF_DEF_  "GenMsgSendType" "noMsgSendType";
BA_DEF_DEF_  "VFrameFormat" "J1939PG";
BA_DEF_DEF_  "SingleFrame" 1;
BA_DEF_DEF_  "DDI" 0;
BA_DEF_DEF_  "SystemSignalLongSymbol" "";
BA_ "GenMsgCycleTime" BO_ 2632384254 100;
BA_ "GenMsgCycleTime" BO_ 2565340926 1000;
BA_ "GenMsgSendType" BO_ 2565340926 2;
BA_ "GenMsgCycleTime" BO_ 2565865214 100;
BA_ "GenMsgSendType" BO_ 2565865214 8.63482481761913E-317;
BA_ "GenMsgCycleTime" BO_ 2365458686 100;
BA_ "GenMsgCycleTime" BO_ 2365458942 100;
BA_ "GenMsgCycleTime" BO_ 2365459198 100;
BA_ "GenMsgCycleTime" BO_ 2365459454 100;
BA_ "GenMsgSendType" BO_ 2365459454 8.61276577466361E-317;
BA_ "GenMsgCycleTime" BO_ 2566786814 100;
BA_ "GenMsgCycleTime" BO_ 2566787070 100;
BA_ "GenMsgCycleTime" BO_ 2365460734 100;
BA_ "GenMsgSendType" BO_ 2365460734 8.60420065262731E-317;
BA_ "GenMsgCycleTime" BO_ 2365460990 100;
BA_ "GenMsgSendType" BO_ 2365460990 8.60320856881046E-317;
BA_ "GenMsgCycleTime" BO_ 2365461246 100;
BA_ "GenMsgSendType" BO_ 2365461246 8.60221253246844E-317;
BA_ "GenMsgCycleTime" BO_ 2365461502 100;
BA_ "GenMsgSendType" BO_ 2365461502 8.60122044865159E-317;
BA_ "GenMsgCycleTime" BO_ 2365461758 100;
BA_ "GenMsgSendType" BO_ 2365461758 8.60022836483475E-317;
BA_ "GenMsgCycleTime" BO_ 2365462014 100;
BA_ "GenMsgSendType" BO_ 2365462014 8.5992362810179E-317;
BA_ "GenMsgCycleTime" BO_ 2365462270 100;
BA_ "GenMsgSendType" BO_ 2365462270 8.59824419720105E-317;
BA_ "GenMsgCycleTime" BO_ 2365462526 100;
BA_ "GenMsgSendType" BO_ 2365462526 8.5972521133842E-317;
BA_ "GenMsgCycleTime" BO_ 2365462782 100;
BA_ "GenMsgSendType" BO_ 2365462782 8.59626002956735E-317;
BA_ "GenMsgCycleTime" BO_ 2365463038 100;
BA_ "GenMsgSendType" BO_ 2365463038 8.5952679457505E-317;
BA_ "SigType" SG_ 2632384254 ExtendedVersionLables 3;
BA_ "SystemSignalLongSymbol" SG_ 2632384254 ChangeChildLocationParentObjectI "ChangeChildLocationParentObjectID";
BA_ "SystemSignalLongSymbol" SG_ 2632384254 ChangeChildPositionParentObjectI "ChangeChildPositionParentObjectID";
BA_ "SystemSignalLongSymbol" SG_ 2632384254 BckgndColourUserLayoutSoftkeyMas "BckgndColourUserLayoutSoftkeyMask";
BA_ "SigType" SG_ 2632384254 VersionLables 3;
BA_ "SigType" SG_ 2632384254 EnteredStringValue 9;
BA_ "SigType" SG_ 2632384254 ManufacturerCode 1;
BA_ "SPN" SG_ 2632384254 ManufacturerCode 2838;
BA_ "SigType" SG_ 2565340926 ExtendedVersionLabelToStore 3;
BA_ "SigType" SG_ 2565340926 ExtendedVersionLabelToLoad 3;
BA_ "SigType" SG_ 2565340926 ExtendedVersionLabelToDelete 3;
BA_ "SystemSignalLongSymbol" SG_ 2565340926 ChangeChildPositionParentOb_0000 "ChangeChildPositionParentObjectID";
BA_ "SystemSignalLongSymbol" SG_ 2565340926 ChangeChildLocationParentOb_0000 "ChangeChildLocationParentObjectID";
BA_ "SigType" SG_ 2565340926 VersionLabelToStore 3;
BA_ "SigType" SG_ 2565340926 VersionLabelToLoad 3;
BA_ "SigType" SG_ 2565340926 VersionLabelToDelete 3;
BA_ "SigType" SG_ 2565340926 NewStringValue 9;
BA_ "SPN" SG_ 2565406462 ControlByte 2541;
BA_ "SigType" SG_ 2565406462 GroupFunctionValue 1;
BA_ "SPN" SG_ 2565406462 GroupFunctionValue 2542;
BA_ "SPN" SG_ 2565406462 ParameterGroupNumber 2574;
BA_ "SigType" SG_ 2565406462 ParameterGroupNumber 6;
BA_ "SPN" SG_ 2565537534 ParameterGroupNumber 2574;
BA_ "SigType" SG_ 2565537534 ParameterGroupNumber 6;
BA_ "SPN" SG_ 2632711934 SequenceNumber 2572;
BA_ "SPN" SG_ 2632777470 ControlByte 2556;
BA_ "SPN" SG_ 2632777470 NumberOfPacketsThatCanBeSent 2561;
BA_ "SPN" SG_ 2632777470 ConnectionAbortReason 2570;
BA_ "SPN" SG_ 2632777470 NextPacketNumberToBeSent 2562;
BA_ "SPN" SG_ 2632777470 TotalNumberOfPackets 2558;
BA_ "SPN" SG_ 2632777470 MaximumNumberOfPackets 2559;
BA_ "SPN" SG_ 2632777470 PGNumber 2560;
BA_ "SigType" SG_ 2632777470 PGNumber 6;
BA_ "SigType" SG_ 2565865214 ManufacturerSpecific1 1;
BA_ "SigType" SG_ 2565865214 ManufacturerSpecific2 1;
BA_ "SigType" SG_ 2565865214 ManufacturerSpecific3 1;
BA_ "SigType" SG_ 2565865214 ManufacturerSpecific4 1;
BA_ "SigType" SG_ 2565865214 ManufacturerSpecific5 1;
BA_ "SigType" SG_ 2565865214 ManufacturerSpecific6 1;
BA_ "SigType" SG_ 2565865214 ManufacturerSpecific7 1;
BA_ "SigType" SG_ 2565865214 ManufacturerSpecific8 1;
BA_ "SPN" SG_ 2365458686 SpeedInfo_EngineSpeed 5233;
BA_ "SPN" SG_ 2365458686 TractorClass 5232;
BA_ "SigType" SG_ 2365458686 TractorClass 4;
BA_ "SPN" SG_ 2365458942 SpeedInfo_EngineSpeed 5235;
BA_ "SPN" SG_ 2365458942 TractorClass 5234;
BA_ "SigType" SG_ 2365458942 TractorClass 4;
BA_ "SPN" SG_ 2365458942 ReservedBitIndicator 5236;
BA_ "SPN" SG_ 2365459198 TractorControlLimitStatus1 5227;
BA_ "SPN" SG_ 2365459198 TractorControlModeResponse1 5213;
BA_ "SigType" SG_ 2365459198 TractorControlValueResponse1 1;
BA_ "SigType" SG_ 2365459198 TractorControlValueResponse2 1;
BA_ "SPN" SG_ 2365459454 TractorControlModeCmd1 5204;
BA_ "SigType" SG_ 2365459454 TractorControlCmdValue1 1;
BA_ "SigType" SG_ 2365459454 TractorControlCmdValue2 1;
BA_ "SPN" SG_ 2633895166 VehicleSystemInstance 2843;
BA_ "SPN" SG_ 2633895166 ManufacturerCode 2838;
BA_ "SigType" SG_ 2633895166 ManufacturerCode 1;
BA_ "SPN" SG_ 2633895166 IndustryGroup 2846;
BA_ "SPN" SG_ 2633895166 IdentityNumber 2837;
BA_ "SPN" SG_ 2633895166 FunctionInstance 2839;
BA_ "SPN" SG_ 2633895166 Function 2841;
BA_ "SPN" SG_ 2633895166 ECUInstance 2840;
BA_ "SPN" SG_ 2633895166 ArbitraryAddressCapable 2844;
BA_ "SigType" SG_ 2633895422 NumberOfMembers 3;
BA_ "SigType" SG_ 2566786814 PGN 6;
BA_ "SPN" SG_ 2566786814 ActualRepetitionRate 5198;
BA_ "SigType" SG_ 2566786814 ActualRepetitionRate 1;
BA_ "SigType" SG_ 2566787070 LanguageCodeCmd 3;
BA_ "SPN" SG_ 2566787070 LanguageCodeCmd 2410;
BA_ "SigType" SG_ 2566787070 TimeFormatCmd 4;
BA_ "SPN" SG_ 2566787070 TimeFormatCmd 2413;
BA_ "SigType" SG_ 2566787070 DecimalSymbolCmd 4;
BA_ "SPN" SG_ 2566787070 DecimalSymbolCmd 2411;
BA_ "SigType" SG_ 2566787070 DateFormatCmd 1;
BA_ "SPN" SG_ 2566787070 DateFormatCmd 2412;
BA_ "SigType" SG_ 2566787070 MassUnitCmd 4;
BA_ "SPN" SG_ 2566787070 MassUnitCmd 2417;
BA_ "SigType" SG_ 2566787070 VolumeUnitCmd 4;
BA_ "SPN" SG_ 2566787070 VolumeUnitCmd 2416;
BA_ "SigType" SG_ 2566787070 AreaUnitCmd 4;
BA_ "SPN" SG_ 2566787070 AreaUnitCmd 2415;
BA_ "SigType" SG_ 2566787070 DistanceUnitCmd 4;
BA_ "SPN" SG_ 2566787070 DistanceUnitCmd 2414;
BA_ "SPN" SG_ 2566787070 UnitsSystem 5197;
BA_ "SigType" SG_ 2566787070 UnitsSystem 4;
BA_ "SPN" SG_ 2566787070 ForceUnits 5196;
BA_ "SigType" SG_ 2566787070 ForceUnits 4;
BA_ "SPN" SG_ 2566787070 PressureUnits 5195;
BA_ "SigType" SG_ 2566787070 PressureUnits 4;
BA_ "SPN" SG_ 2566787070 TemperatureUnits 5194;
BA_ "SigType" SG_ 2566787070 TemperatureUnits 4;
BA_ "SPN" SG_ 2365460734 Valve0ExtendedPortEstimatedFlow 1901;
BA_ "SigType" SG_ 2365460734 Valve0ExtendedPortEstimatedFlow 1;
BA_ "SigType" SG_ 2365460734 Valve0RetractPortEstimatedFlow 1;
BA_ "SPN" SG_ 2365460734 Valve0RetractPortEstimatedFlow 1902;
BA_ "SPN" SG_ 2365460734 Valve0ValveState 1903;
BA_ "SigType" SG_ 2365460734 Valve0FailSafeMode 4;
BA_ "SPN" SG_ 2365460734 Valve0FailSafeMode 1910;
BA_ "SPN" SG_ 2365460734 Valve0LimitStatus 5161;
BA_ "SigType" SG_ 2365460990 Valve1ExtendedPortEstimatedFlow 1;
BA_ "SPN" SG_ 2365460990 Valve1ExtendedPortEstimatedFlow 1913;
BA_ "SigType" SG_ 2365460990 Valve1RetractPortEstimatedFlow 1;
BA_ "SPN" SG_ 2365460990 Valve1RetractPortEstimatedFlow 1914;
BA_ "SPN" SG_ 2365460990 Valve1ValveState 1915;
BA_ "SigType" SG_ 2365460990 Valve1FailSafeMode 4;
BA_ "SPN" SG_ 2365460990 Valve1FailSafeMode 1922;
BA_ "SPN" SG_ 2365460990 Valve1LimitStatus 5163;
BA_ "SigType" SG_ 2365461246 Valve2ExtendedPortEstimatedFlow 1;
BA_ "SPN" SG_ 2365461246 Valve2ExtendedPortEstimatedFlow 1925;
BA_ "SigType" SG_ 2365461246 Valve2RetractPortEstimatedFlow 1;
BA_ "SPN" SG_ 2365461246 Valve2RetractPortEstimatedFlow 1926;
BA_ "SPN" SG_ 2365461246 Valve2ValveState 1927;
BA_ "SigType" SG_ 2365461246 Valve2FailSafeMode 4;
BA_ "SPN" SG_ 2365461246 Valve2FailSafeMode 1934;
BA_ "SPN" SG_ 2365461246 Valve2LimitStatus 5165;
BA_ "SigType" SG_ 2365461502 Valve3ExtendedPortEstimatedFlow 1;
BA_ "SPN" SG_ 2365461502 Valve3ExtendedPortEstimatedFlow 1937;
BA_ "SigType" SG_ 2365461502 Valve3RetractPortEstimatedFlow 1;
BA_ "SPN" SG_ 2365461502 Valve3RetractPortEstimatedFlow 1938;
BA_ "SPN" SG_ 2365461502 Valve3ValveState 1939;
BA_ "SigType" SG_ 2365461502 Valve3FailSafeMode 4;
BA_ "SPN" SG_ 2365461502 Valve3FailSafeMode 1946;
BA_ "SPN" SG_ 2365461502 Valve3LimitStatus 5167;
BA_ "SigType" SG_ 2365461758 Valve4ExtendedPortEstimatedFlow 1;
BA_ "SPN" SG_ 2365461758 Valve4ExtendedPortEstimatedFlow 1949;
BA_ "SigType" SG_ 2365461758 Valve4RetractPortEstimatedFlow 1;
BA_ "SPN" SG_ 2365461758 Valve4RetractPortEstimatedFlow 1950;
BA_ "SPN" SG_ 2365461758 Valve4ValveState 1951;
BA_ "SigType" SG_ 2365461758 Valve4FailSafeMode 4;
BA_ "SPN" SG_ 2365461758 Valve4FailSafeMode 1958;
BA_ "SPN" SG_ 2365461758 Valve4LimitStatus 5169;
BA_ "SigType" SG_ 2365462014 Valve5ExtendedPortEstimatedFlow 1;
BA_ "SPN" SG_ 2365462014 Valve5ExtendedPortEstimatedFlow 1961;
BA_ "SigType" SG_ 2365462014 Valve5RetractPortEstimatedFlow 1;
BA_ "SPN" SG_ 2365462014 Valve5RetractPortEstimatedFlow 1962;
BA_ "SPN" SG_ 2365462014 Valve5ValveState 1963;
BA_ "SigType" SG_ 2365462014 Valve5FailSafeMode 4;
BA_ "SPN" SG_ 2365462014 Valve5FailSafeMode 1970;
BA_ "SPN" SG_ 2365462014 Valve5LimitStatus 5171;
BA_ "SigType" SG_ 2365462270 Valve6ExtendedPortEstimatedFlow 1;
BA_ "SPN" SG_ 2365462270 Valve6ExtendedPortEstimatedFlow 1973;
BA_ "SigType" SG_ 2365462270 Valve6RetractPortEstimatedFlow 1;
BA_ "SPN" SG_ 2365462270 Valve6RetractPortEstimatedFlow 1974;
BA_ "SPN" SG_ 2365462270 Valve6ValveState 1975;
BA_ "SigType" SG_ 2365462270 Valve6FailSafeMode 4;
BA_ "SPN" SG_ 2365462270 Valve6FailSafeMode 1982;
BA_ "SPN" SG_ 2365462270 Valve6LimitStatus 5173;
BA_ "SigType" SG_ 2365462526 Valve7ExtendedPortEstimatedFlow 1;
BA_ "SPN" SG_ 2365462526 Valve7ExtendedPortEstimatedFlow 1985;
BA_ "SigType" SG_ 2365462526 Valve7RetractPortEstimatedFlow 1;
BA_ "SPN" SG_ 2365462526 Valve7RetractPortEstimatedFlow 1986;
BA_ "SPN" SG_ 2365462526 Valve7ValveState 1987;
BA_ "SigType" SG_ 2365462526 Valve7FailSafeMode 4;
BA_ "SPN" SG_ 2365462526 Valve7FailSafeMode 1994;
BA_ "SPN" SG_ 2365462526 Valve7LimitStatus 5175;
BA_ "SigType" SG_ 2365462782 Valve8ExtendedPortEstimatedFlow 1;
BA_ "SPN" SG_ 2365462782 Valve8ExtendedPortEstimatedFlow 1997;
BA_ "SigType" SG_ 2365462782 Valve8RetractPortEstimatedFlow 1;
BA_ "SPN" SG_ 2365462782 Valve8RetractPortEstimatedFlow 1998;
BA_ "SPN" SG_ 2365462782 Valve8ValveState 1999;
BA_ "SigType" SG_ 2365462782 Valve8FailSafeMode 4;
BA_ "SPN" SG_ 2365462782 Valve8FailSafeMode 2262;
BA_ "SPN" SG_ 2365462782 Valve8LimitStatus 5177;
BA_ "SigType" SG_ 2365463038 Valve9ExtendedPortEstimatedFlow 1;
BA_ "SPN" SG_ 2365463038 Valve9ExtendedPortEstimatedFlow 2265;
BA_ "SigType" SG_ 2365463038 Valve9RetractPortEstimatedFlow 1;
BA_ "SPN" SG_ 2365463038 Valve9RetractPortEstimatedFlow 2266;
BA_ "SPN" SG_ 2365463038 Valve9ValveState 2267;
BA_ "SigType" SG_ 2365463038 Valve9FailSafeMode 4;
BA_ "SPN" SG_ 2365463038 Valve9FailSafeMode 2274;
BA_ "SPN" SG_ 2365463038 Valve9LimitStatus 5179;
VAL_ 2632384254 AssignedAttribute2 1 "InputIsAssigned" ;
VAL_ 2632384254 AssignedAttribute1 1 "AuxiliaryFunction" 0 "AuxiliaryInput" ;
VAL_ 2632384254 VTFunctionVTtoECU 39 " AuxiliaryCapabilitiesResponse" 214 "ExtendedDeleteVersionResponse" 213 "ExtendedLoadVersionResponse" 212 "ExtendedStoreVersionResponse" 211 "ExtendedGetVersionsResponse" 188 "ExecuteExtendedMacroResponse" 11 "VTOpCodeNotification" 197 "GetSupportedObjectsResponse" 187 "IdentifyVTResponse" 38 "AuxiliaryInputStatusType2" 36 "AuxiliaryAssignmentCommandType2" 193 "GetSupported WideCharsResponse" 37 "AuxiliaryInputStatusEnableCommand" 190 "ExecuteMacroResponse" 189 "LockUnlockMaskResponse" 35 "AuxiliaryInputMaintenance" 10 "VTControlAudioDeviceTermination" 9 "VTOnUserLayoutHideShow" 186 "SelectColourMapResponse" 185 "GetAttributeValueResponse" 184 "GraphicsContextCommandResponse" 183 "ChangePolygonScaleResponse" 182 "ChangePolygonPointResponse" 181 "SetObjectLabelResponse" 0 "SoftKeyActivation" 1 "ButtonActivation" 2 "PointingEvent" 18 "EndOfObjectPoolResponse" 32 "AuxiliaryAssignmentCommand" 146 "ESCResponse" 160 "ShowHideObjectResponse" 161 "EnableDisableObjectResponse" 162 "SelectInputObjectResponse" 163 "ControlAudioDeviceResponse" 164 "SetAudioVolumeResponse" 165 "ChangeChildLocationResponse" 166 "ChangeSizeResponse" 167 "ChangeBackgroundColourResponse" 168 "ChangeNumericValueResponse" 169 "ChangeEndPointResponse" 170 "ChangeFontAttributesResponse" 171 "ChangeLineAttributesResponse" 172 "ChangeFillAttributesResponse" 173 "ChangeActiveMaskResponse" 174 "ChangeSoftKeyMaskResponse" 175 "ChangeAttributeResponse" 176 "ChangePriorityResponse" 177 "ChangeListItemResponse" 178 "DeleteObjectPoolResponse" 192 "GetMemoryResponse" 194 "GetNumberOfSoftKeysResponse" 195 "GetTextFontDataResponse" 199 "GetHardwareResponse" 208 "StoreVersionResponse" 209 "LoadVersionResponse" 210 "DeleteVersionResponse" 224 "GetVersionsResponse" 254 "VTStatusMessage" 33 "AuxiliaryInputStatus" 3 "VTSelectInputObject" 4 "VTESC" 5 "VTChangeNumericValue" 6 "VTChangeActiveMask" 7 "VTChangeSoftKeyMask" 8 "VTChangeStringValue" 196 "GetWindowMaskDataResponse" 240 "VTObjectPoolErrorMessage" 179 "ChangeStringValueResponse" 180 "ChangeChildPositionResponse" 34 "AuxiliaryPreferredAssignmentResponse" ;
VAL_ 2632384254 BootTime 255 "Information not available" ;
VAL_ 2632384254 TerminationCause 1 "AudioWasTerminated" ;
VAL_ 2632384254 KeyActivationCode 3 "KeyPressAborted" 0 "KeyHasBeenReleased" 1 "KeyHasBeenPressed" 2 "KeyIsStillPressed" ;
VAL_ 2632384254 ButtonActivationCode 3 "ButtonPressAborted" 0 "ButtonHasBeenUnlatched" 1 "ButtonHasBeenLatched" 2 "ButtonIsStillHeld" ;
VAL_ 2632384254 ErrorCodeEndOfObjectPool1 1 "ErrorsInTheObjectPool" 0 "NoErrors" ;
VAL_ 2632384254 AuxPreferredAssignmentRespError1 1 "AuxiliaryInputUnit(s)NotValid" 0 "NoErrors" ;
VAL_ 2632384254 ErrorCodeControlAudioDevice1 0 "NoErrors" 1 "AudioDeviceIsBusy" ;
VAL_ 2632384254 ErrorCodeAudioVolume1 0 "NoErrors" 1 "AudioDeviceIsBusy" ;
VAL_ 2632384254 ErrorCodeDeleteObjectPool1 0 "NoErrors" 1 "DeletionError" ;
VAL_ 2632384254 ErrorCodeSetObjectLabel1 1 "InvalidObjectId" 0 "NoError" ;
VAL_ 2632384254 LockUnlockCommand 1 "LockMask" 0 "UnlockMask" ;
VAL_ 2632384254 VersionNumberISO11783Part6 0 "Hannover Agritechnica 2001 limit" 1 "FDIS_Version" 2 "VersionOfThe1PublishedEdition" 3 "VersionOfThe2PublishedEdition" 4 "VersionOfThe3PublishedEdition" 5 "VersionOfThe4PublishedEdition" 6 "VersionOfThe5PublishedEdition" 7 "VersionOfThe6PublishedEdition" 8 "VersionOfThe7PublishedEdition" 9 "VersionOfThe8PublishedEdition" 10 "VersionOfThe9PublishedEdition" 11 "VersionOfThe10PublishedEdition" 12 "VersionOfThe11PublishedEdition" 13 "VersionOfThe12PublishedEdition" 14 "VersionOfThe13PublishedEdition" 15 "VersionOfThe14PublishedEdition" 16 "VersionOfThe15PublishedEdition" 17 "VersionOfThe16PublishedEdition" 18 "VersionOfThe17PublishedEdition" 19 "VersionOfThe18PublishedEdition" 20 "VersionOfThe19PublishedEdition" 21 "VersionOfThe20PublishedEdition" 22 "VersionOfThe21PublishedEdition" 23 "VersionOfThe22PublishedEdition" 24 "VersionOfThe23PublishedEdition" 25 "VersionOfThe24PublishedEdition" 26 "VersionOfThe25PublishedEdition" 27 "VersionOfThe26PublishedEdition" 28 "VersionOfThe27PublishedEdition" 29 "VersionOfThe28PublishedEdition" 30 "VersionOfThe29PublishedEdition" 31 "VersionOfThe30PublishedEdition" 32 "VersionOfThe31PublishedEdition" 33 "VersionOfThe32PublishedEdition" 34 "VersionOfThe33PublishedEdition" 35 "VersionOfThe34PublishedEdition" 36 "VersionOfThe35PublishedEdition" 37 "VersionOfThe36PublishedEdition" 38 "VersionOfThe37PublishedEdition" 39 "VersionOfThe38PublishedEdition" 40 "VersionOfThe39PublishedEdition" 41 "VersionOfThe40PublishedEdition" 42 "VersionOfThe41PublishedEdition" 43 "VersionOfThe42PublishedEdition" 44 "VersionOfThe43PublishedEdition" 45 "VersionOfThe44PublishedEdition" 46 "VersionOfThe45PublishedEdition" 47 "VersionOfThe46PublishedEdition" 48 "VersionOfThe47PublishedEdition" 49 "VersionOfThe48PublishedEdition" 50 "VersionOfThe50PublishedEdition" ;
VAL_ 2632384254 ErrorCodeEndOfObjectPool2 0 "NoErrors" 1 "VTRanOutOfMemoryDuringTransfer" ;
VAL_ 2632384254 AuxPreferredAssignmentRespError2 1 "FunctionObjectID(s)NotValid" 0 "NoErrors" ;
VAL_ 2632384254 ErrorCodeSetObjectLabel2 1 "InvalidStringVariableObjectId" 0 "NoError" ;
VAL_ 2632384254 AuxPreferredAssignmentRespError3 1 "InputObjectID(s)NotValid" 0 "NoErrors" ;
VAL_ 2632384254 ErrorCodeSetObjectLabel3 1 "InvalidFontType" 0 "NoError" ;
VAL_ 2632384254 AuxPreferredAssignmentRespError4 1 "DuplicateObjectIdOfAuxFct" 0 "NoErrors" ;
VAL_ 2632384254 ErrorCodeSetObjectLabel4 1 "InvalidDesignatorObjectReference" 0 "NoError" ;
VAL_ 2632384254 AuxPreferredAssignmentRespError5 1 "GeneralError" 0 "NoErrors" ;
VAL_ 2632384254 ErrorCodeEndOfObjectPool3 0 "NoErrors" 1 "GeneralError" ;
VAL_ 2632384254 ErrorCodeControlAudioDevice2 0 "NoErrors" 1 "GeneralError" ;
VAL_ 2632384254 ErrorCodeAudioVolume2 0 "NoErrors" 1 "GeneralError" ;
VAL_ 2632384254 ErrorCodeDeleteObjectPool2 0 "NoErrors" 1 "GeneralError" ;
VAL_ 2632384254 ErrorCodeSetObjectLabel5 1 "DesignatorReferencesInvalidObjects" 0 "NoError" ;
VAL_ 2632384254 ErrorCodeSetObjectLabel6 1 "GeneralError" 0 "NoError" ;
VAL_ 2632384254 KeyObjectID 0 "KeyHasBeenReleased" 1 "KeyHasBeenPressed" 2 "KeyIsStillPressed" ;
VAL_ 2632384254 ButtonObjectID 0 "KeyHasBeenReleased" 1 "KeyHasBeenPressed" 2 "KeyIsStillPressed" ;
VAL_ 2632384254 ErrorCodeLockUnlockMask1 1 "MaskNotVisibleOrInvalidObjectId" 0 "NoError" ;
VAL_ 2632384254 ErrorCodeExecuteMacro1 1 "ObjectIdNotExist" 0 "NoError" ;
VAL_ 2632384254 MemoryStatus 0 "EnoughMemoryMayBeAvailable" 1 "NotEnoughMemoryAvailable" ;
VAL_ 2632384254 SupportedGraphicMode 0 "Monocrome" 1 "Colour16" 2 "Colour256" ;
VAL_ 2632384254 ErrorCodeLockUnlockMask2 1 "MaskAlreadyLocked" 0 "NoError" ;
VAL_ 2632384254 ErrorCodeExecuteMacro2 1 "ObjectIdIsNoMacro" 0 "NoError" ;
VAL_ 2632384254 ErrorCodeLockUnlockMask3 1 "MaskNotLocked" 0 "NoError" ;
VAL_ 2632384254 ErrorCodeExecuteMacro3 1 "GeneralError" 0 "NoError" ;
VAL_ 2632384254 ErrorCodeLockUnlockMask4 1 "AlarmMaskIsActive" 0 "NoError" ;
VAL_ 2632384254 ErrorCodeLockUnlockMask5 1 "UnsolicitedUnlock_TimeoutOccured" 0 "NoError" ;
VAL_ 2632384254 ErrorCodeLockUnlockMask6 1 "UnsolicitedUnlock_MaskChanged" 0 "NoError" ;
VAL_ 2632384254 ErrorCodeLockUnlockMask7 1 "UnsolicitedUnlock_OperatorInduce" 0 "NoError" ;
VAL_ 2632384254 ErrorCodeLockUnlockMask8 1 "GeneralError" 0 "NoError" ;
VAL_ 2632384254 Status_1 1 "Shown" 0 "Hidden" ;
VAL_ 2632384254 VTSelectInputObjectStatus 0 "ObjectIsDeselected" 1 "ObjectIsSelected" ;
VAL_ 2632384254 ErrorCodeVTEsc1 0 "NoError" 1 "NoInputFieldSelected ESC_Ignored" ;
VAL_ 2632384254 ErrorCodeEscapeObj1 0 "NoErrors" 1 "NoInputFieldIsOpenForInput" ;
VAL_ 2632384254 ObjectShowStatus 0 "ObjectIsHidden" 1 "ObjectIsShown" ;
VAL_ 2632384254 ObjectEnableStatus 0 "ObjectIsDisabled" 1 "ObjectIsEnabled" ;
VAL_ 2632384254 ObjectSelectStatus 2 "ObjectIsOpenedForEdit" 0 "ObjectIsDeselectedOrObjectIDIsNullObject" 1 "ObjectIsSelected" ;
VAL_ 2632384254 ErrorCodeObjToSize1 0 "NoErrors" 1 "InvalidObjectID" ;
VAL_ 2632384254 ErrorCodeChangeNumValue1 0 "NoErrors" 1 "InvalidObjectID" ;
VAL_ 2632384254 ErrorCodeChangeEditPoint1 0 "NoErrors" 1 "InvalidObjectID" ;
VAL_ 2632384254 ErrorCodeChangeFont1 0 "NoErrors" 1 "InvalidObjectID" ;
VAL_ 2632384254 ErrorCodeChangeLineAttribute1 0 "NoErrors" 1 "InvalidObjectID" ;
VAL_ 2632384254 ErrorCodeChangeFillAttributes1 0 "NoErrors" 1 "InvalidObjectID" ;
VAL_ 2632384254 ErrorCodeChangeActiveMask1 0 "NoErrors" 1 "InvalidWorkingSetObject" ;
VAL_ 2632384254 ErrorCodeChangePoygonPoint1 1 "InvalidObjectId" 0 "NoError" ;
VAL_ 2632384254 SubCommandID 20 "CopyViewportToPictureGraphic" 19 "CopyCanvasToPictureGraphic" 18 "DrawVTObject" 17 "ChangeViewportSize" 16 "PanAndZoomViewport" 15 "ZoomViewport" 14 "PanViewport" 13 "DrawText" 12 "DrawPolygon" 11 "DrawClosedEllipse" 10 "DrawRectangle" 9 "DrawLine" 8 "DrawPoint" 7 "EraseRectangle" 6 "SetFontAttributesID" 5 "SetFillAttributesObjectID" 4 "SetLineAttributesObjectID" 3 "SetBackgroundColour" 2 "SetForegroundColour" 1 "MoveGraphicsCursor" 0 "SetGraphicsCursor" ;
VAL_ 2632384254 ErrorCodeSelectColourMap1 1 "InvalidObjectID" 0 "NoError" ;
VAL_ 2632384254 Hardware1 0 "VT has no touch screen and no pointing device" 1 "VT has a touch screen or pointing device" ;
VAL_ 2632384254 ErrorCodeObjToSize2 0 "NoErrors" 1 "InvalidWidth" ;
VAL_ 2632384254 ErrorCodeChangeNumValue2 0 "NoErrors" 1 "InvalidValue" ;
VAL_ 2632384254 ErrorCodeChangeEditPoint2 0 "NoErrors" 1 "InvalidLineDirection" ;
VAL_ 2632384254 ErrorCodeChangeFont2 0 "NoErrors" 1 "InvalidColour" ;
VAL_ 2632384254 ErrorCodeChangeLineAttribute2 0 "NoErrors" 1 "InvalidObjectColour" ;
VAL_ 2632384254 ErrorCodeChangeFillAttributes2 0 "NoErrors" 1 "InvalidType" ;
VAL_ 2632384254 ErrorCodeChangeActiveMask2 0 "NoErrors" 1 "InvalidMaskObjectID" ;
VAL_ 2632384254 ErrorCodeChangePoygonPoint2 1 "InvalidPointIndex" 0 "NoError" ;
VAL_ 2632384254 ErrorCodeSelectColourMap2 1 "GeneralError" 0 "NoError" ;
VAL_ 2632384254 Hardware2 0 "VT does not report drag operation" 1 "VT reports drag operation" ;
VAL_ 2632384254 ErrorCodeMissingObjects 0 "NoErrors" 1 "MissingObjects" ;
VAL_ 2632384254 ErrorCodeObjToSize3 0 "NoErrors" 1 "InvalidHeight" ;
VAL_ 2632384254 ErrorCodeChangeFont3 0 "NoErrors" 1 "InvalidSize" ;
VAL_ 2632384254 ErrorCodeChangeLineAttribute3 0 "NoErrors" 1 "InvalidWidth" ;
VAL_ 2632384254 ErrorCodeChangeFillAttributes3 0 "NoErrors" 1 "InvalidColour" ;
VAL_ 2632384254 ErrorCodeChangeActiveMask3 0 "NoErrors" 1 "MissingObjects" ;
VAL_ 2632384254 ErrorCodeChangePoygonPoint3 1 "GeneralError" 0 "NoError" ;
VAL_ 2632384254 Hardware3 0 "VT has no multiple frequency audio output" 1 "VT has multiple frequency audio output" ;
VAL_ 2632384254 ErrorCodeMaskOrChildObjectError 0 "NoErrors" 1 "MaskOrChildObjectHasErrors" ;
VAL_ 2632384254 ErrorCodeChangeFont4 0 "NoErrors" 1 "InvalidType" ;
VAL_ 2632384254 ErrorCodeChangeFillAttributes4 0 "NoErrors" 1 "InvalidPatternObjectID" ;
VAL_ 2632384254 ErrorCodeChangeActiveMask4 0 "NoErrors" 1 "MaskOrChildObjectHasErrors" ;
VAL_ 2632384254 Hardware4 0 "VT has no adjustable volume audio output" 1 "VT has adjustable volume audio output" ;
VAL_ 2632384254 ErrorCodeChangeNumValue4 0 "NoErrors" 1 "ValueInUse" ;
VAL_ 2632384254 ErrorCodeVTEsc2 0 "NoError" 1 "GeneralError" ;
VAL_ 2632384254 ErrorCodeAnyOtherError 0 "NoErrors" 1 "GeneralError" ;
VAL_ 2632384254 ErrorCodeEscapeObj2 0 "NoErrors" 1 "GeneralError" ;
VAL_ 2632384254 ErrorCodeObjToSize4 0 "NoErrors" 1 "GeneralError" ;
VAL_ 2632384254 ErrorCodeChangeNumValue3 0 "NoErrors" 1 "ValueInUse" ;
VAL_ 2632384254 ErrorCodeChangeEditPoint3 0 "NoErrors" 1 "GeneralError" ;
VAL_ 2632384254 ErrorCodeChangeFont5 0 "NoErrors" 1 "InvalidStyle" ;
VAL_ 2632384254 ErrorCodeChangeLineAttribute4 0 "NoErrors" 1 "GeneralError" ;
VAL_ 2632384254 ErrorCodeChangeFillAttributes5 0 "NoErrors" 1 "GeneralError" ;
VAL_ 2632384254 ErrorCodeChangeActiveMask5 0 "NoErrors" 1 "GeneralError" ;
VAL_ 2632384254 Hardware5 0 "VT does not support simultaneous activations of softkeys" 1 "VT supports simultaneous activations of softkeys" ;
VAL_ 2632384254 ErrorCodePoolDeleted 0 "NoErrors" 1 "PoolBeingDeleted" ;
VAL_ 2632384254 ManufacturerCode 454 "NGK Spark Plug Co. Ltd" 453 "Cooper Bussmann" 452 "WIKA Alexander Wiegand SE & Co. KG" 451 "Parker Hannifin Corp" 450 "Dycor Technologies Ltd." 449 "Polaris Industries Inc" 448 "Stanadyne Corporation, Electronics Systems" 447 "Great Plains Mfg." 446 "CertTech, L.L.C." 445 "KAT MECHATRONIC, Electronic Product Division" 444 "ITT Power Solutions" 443 "SignalQuest, Inc." 442 "Horsch Maschinen GmbH" 441 "PTG Reifendruckregelsysteme GmbH" 440 "Cummins Power Generation" 439 "Hyundai Heavy Industries" 438 "Comar Systems Ltd" 437 "Digital Yacht Limited" 436 "Kinze Manufacturing" 435 "Zunhammer GmbH" 434 "Stored Energy Systems" 433 "Rowe Electronics" 432 "S&A Systems, Inc." 431 "Tohatsu Corporation" 430 "Auteq Telematica S.A." 479 "Vapor Bus International" 478 "OceanSat BV" 477 "OilQuick AB" 476 "Hummingbird Marine Electronics" 475 "GME" 474 "Persen Technologies Inc." 473 "Boss Industries, Inc." 472 "Tenneco Inc." 471 "Sea Cross Marine AB" 470 "SI-TEX Marine Electronics" 469 "RA Consulting GmbH" 468 "Tyco Fire Protection Products" 467 "Lely Industries N.V." 466 "Veethree Electronics and Marine LLC" 465 "Ashcroft Inc" 464 "Leach International Corporation" 463 "PROBOTIQ" 462 "IHI Shibaura Machinery Corporation" 461 "HAWE Hydraulik SE" 460 "San Giorgio S.E.I.N." 459 "Alltek Marine Electronics Corp" 458 "Control Solutions, Inc." 457 "RUSELPROM-ElectricDrive Ltd" 456 "General Kinetics" 455 "ADZ NAGANO GmbH" 429 "Rota Engineering Ltd." 428 "Mfg_428" 427 "Mfg_427" 426 "Mfg_426" 425 "Methode Electronics Inc, MDI" 424 "Odyne LLC" 423 "BSM Wireless, Inc." 422 "True Heading AB" 421 "Vertex Standard Co., Ltd" 420 "Vermeer Corporation, ACS Group" 419 "Fusion Electronics Ltd" 418 "Intellistick Inc" 417 "KZValve" 416 "Kubota Corporation" 415 "Valid Manufacturing Ltd." 414 "Cattron Group International" 413 "Datapross Nijbroek bv" 412 "WebTech Wireless Inc." 411 "Hy-Drive Technologies Ltd." 410 "COBO S.p.A. Divisione 3B6" 409 "Transfluid S.r.L." 408 "Corvus Energy Ltd." 407 "Comtech Mobile Datacom" 406 "Vecima Networks Inc." 405 "Wema System AS" 404 "Com Nav Marine Ltd" 403 "Trackwell ADS, Inc." 402 "Simma Software, Inc." 401 "Torqeedo GmbH" 400 "Livorsi Marine" 399 "ISEKI & Co., Ltd." 398 "Hilite International" 397 "Sanyo-kiki Co Ltd." 396 "Beyond Measure" 395 "GENTEC S.R.L." 394 "Capi 2 Nederland BV" 393 "Harvest Tec, Inc" 392 "Tianyuan Technology Co Ltd." 391 "Electronic Design for Industry, Inc" 390 "Partech Inc." 389 "Benchmark Electronics, Minnesota Division" 388 "Innomatix, LLC" 387 "Orscheln Products, LLC" 386 "JLG Automation BVBA" 385 "Johnson Outdoor Marine Electronics" 384 "Camano Light" 383 "MCL Industries" 382 "National Agricultural and Food Research Organization" 380 "Suntech International Ltd." 379 "Yamabiko Corporation" 378 "Glendinning Marine Products" 377 "ifm electronic gmbh" 376 "Quake Global" 375 "Williams Controls Inc." 372 "Delphi" 381 "B&G" 374 "Northern Lights, Inc." 373 "Electronic Design Inc." 371 "Heinzmann GmbH & Co. KG" 370 "Rolls-Royce Marine AS" 369 "Power Torque Engineering Ltd" 368 "HANSENHOF_electronic" 367 "Fliegl Agrartechnik" 366 "Viewnyx Corp." 365 "Digi-Star, LLC" 364 "OEM Controls Inc." 363 "BEI Duncan" 362 "Alois Poettinger Maschinenfabrik GmbH" 361 "InMach" 360 "HJS Emission Technology GmbH & Co KG" 359 "Ludwig Bergmann GmbH" 358 "Victron Energy BV" 357 "Hardi International A/S" 356 "Fischer Panda Generators, Inc" 355 "Mastervolt International B.V." 354 "Junkkari OY" 353 "Hegemon Electronics, Inc." 352 "SAME DEUTZ-FAHR" 351 "Thrane & Thrane" 350 "Noris Marine Systems GmbH & Co KG" 349 "Suonentiet" 348 "Amazonen Werke H. Dreyer" 347 "Honeywell" 346 "Control Solutions" 345 "Korean Maritime University" 344 "Parvus Corporation" 343 "Baumer Group" 342 "THOMAS MAGNETE GmbH" 341 "Boning GmbH & Co" 340 "Continental AG" 339 "Competence Center ISOBUS e.V." 338 "GRAF-SYTECO" 337 "Carraro S.p.A." 336 "APE s.r.o." 335 "Evo Electric Ltd" 334 "Takata-Petri AG" 333 "Hadley Products Corporation" 332 "HWH Corporation" 331 "Horton, Inc." 330 "Kidde Aerospace and Defense" 329 "Deif A/S" 328 "Qwerty Electronik AB" 252 "Sensor-Technik Wiedemann GmbH" 251 "German Agricultural Society" 250 "Kuhn Group" 249 "Schaltbau GmbH" 233 "Yacht Monitoring Solutions Inc." 232 "TSD Integrated Controls" 1863 "Thomas G. Faria Co." 1862 "Sanshin" 1861 "Vector North America" 1860 "MMP" 1859 "Kvasar AB" 1858 "Litton" 1857 "Simrad" 1856 "Trimble" 1855 "Furuno USA" 1854 "Northstar Technologies" 1853 "Japan Radio Co." 1852 "Navionics" 1851 "Raymarine" 1850 "Teleflex" 222 "Generac Power Systems, Inc." 221 "SiE" 220 "Beede Electrical Instrument Company, Inc." 219 "Cat OEM Solutions" 218 "Gits Manufacturing Company" 217 "RM Michaelides Software & Elektronik GmbH" 216 "Paneltronics Inc." 215 "Aetna Engineering/Fireboy-Xintex" 214 "MC elettronica Srl" 213 "CNH Belgium N.V." 212 "Sure Power Industries, Inc." 211 "DNA Group" 210 "Iteris, Inc." 209 "Bell Equip. Co. SA (PTY) LTD" 208 "Drew Technologies, Inc." 207 "Otto Engineering" 206 "port GmbH" 205 "SmarTire Systems Inc" 204 "The Morey Corporation" 203 "MILtronik GmbH" 202 "Curtis Instruments, Inc." 201 "Disenos y Tecnologia S.A." 200 "MGM Brakes" 199 "Actia Corp." 198 "Mystic Valley Communications" 197 "Mechron Power Systems" 196 "LEMKEN GmbH & Co. KG" 195 "General Engine Products" 194 "TriMark Corporation" 193 "Nobletec" 192 "Floscan" 191 "XATA Corporation" 190 "Hella KGaA Hueck & Co." 189 "QUALCOMM" 188 "EMP Corp." 187 "Air-Weigh" 186 "Altronic, Inc." 185 "Beede Electrical Instrument Company" 184 "EIA Electronics" 183 "KDS Controls, Inc." 182 "Vehicle Systems Engineering B.V." 181 "Coretronics, Inc." 180 "Smart Power Systems" 179 "TeeJet Technologies Denmark" 178 "Siemens VDO Automotive AG" 177 "Diagnostic System Associates" 176 "Moritz Aerospace" 175 "Veris Technologies, Inc." 174 "AB Volvo Penta" 173 "Ryeso, Inc." 172 "Yanmar Marine USA" 171 "Wachendorff Elektronik GmbH & Co. KG" 170 "Computronics Corporation Ltd." 169 "Marlin Technologies Inc." 168 "Xantrex" 167 "JLG Industries Inc." 166 "Phoenix International" 165 "CPAC Systems AB" 164 "DaimlerChrysler Off-Highway" 163 "BRP Inc." 162 "Axiomatic Technologies" 161 "Offshore Systems (UK) Limited" 160 "Nido" 159 "NTech Industries Inc." 158 "Firestone Industrial Products Company" 157 "ISSPRO Inc." 156 "ITT Industries - Cannon" 155 "Vetronix Corporation" 154 "Westerbeke Corporation" 153 "Woodward, Industrial Controls Division" 152 "elobau GmbH & Co. KG" 151 "Raven Industries Inc. - Flow Controls Division" 150 "Fleetguard" 149 "Holset" 148 "Blue Water Data, Inc." 147 "Nautibus Electronic GmbH" 146 "Maxima Technologies" 145 "MurCal Controls" 144 "Mercury Marine" 143 "W. Gmeiner GmbH & Co." 142 "TRW Automotive (Commercial Steering Systems)" 141 "Thales Navigation Ltd." 140 "Lowrance Electronics, Inc." 139 "Caterpillar Trimble Control Technologies (CTCT), LLC" 138 "Georg Fritzmeier GmbH & Co. KG" 137 "Maretron" 136 "Komatsu Ltd." 135 "Airmar Technology Corporation" 134 "Iris Technology Ltd." 133 "Bucher Schoerling GmbH" 132 "Mulag-Fahrzeugwerk" 131 "ITT Industries" 130 "Nido - Universal Machines B.V." 129 "OMNEX Control Systems, Inc." 128 "Gerhard Duecker GmbH & Co. KG" 127 "Holland USA" 126 "Driver Tech" 125 "Nevada Automotive Test Center" 124 "Hydac Electronic" 123 "Basler Electric" 122 "FG Wilson (Engineering) Limited" 121 "HED (Hydro Electronic Devices, Inc.)" 120 "RDS Technology Ltd." 119 "IntegriNautics" 118 "Intron GmbH" 117 "HUSCO International" 116 "BEELINE Technologies" 115 "NACCO Materials Handling Group, Inc." 114 "EControls, Inc." 113 "Stress-Tek, Inc." 112 "MECALAC" 111 "Maschinenfabrik Bernard Krone GmbH" 110 "EPIQ Sensor-Nite" 109 "TeeJet Technologies Denmark" 108 "WTK-Elecktronik GmbH" 107 "Grimme Landmaschinen GmbH & Co. KG" 106 "BAE Systems Controls, Inc." 105 "Kiepe Elektrik GmbH & Co. KG" 104 "Claas Selbstfahrende Erntemaschinen GmbH" 103 "CLAAS Agrosystems GmbH & Co. KG" 102 "AGCO GmbH & Co." 101 "Sensoria" 100 "VDO Technik AG" 99 "International Transmissions Ltd (ITL)" 98 "Mueller-Elektronik GmbH & Co." 97 "Ag Leader Technology, Inc." 96 "Mech@tronic IT GmbH" 95 "Pacific Insight Electronics Corp." 94 "CNH Global N.V." 93 "Perkins Engines Company Ltd." 92 "Ag-Chem Equipment Co., Inc." 91 "BSG Bodensee Steuergeraete GmbH" 90 "Knorr-Bremse SfN GmbH" 89 "Kverneland Group, Electronics Division" 88 "Satloc Precision GPS" 87 "J.C. Bamford Excavators Ltd (JCB)" 86 "C.E. Niehoff & Company" 85 "Kohler Co." 84 "New Holland UK Limited" 83 "Eaton VORAD Technologies" 82 "Bobcat/Ingersoll-Rand" 81 "Fire Research Corp" 80 "Twin Disc, Inc." 79 "Daimler Benz AG - Engine Division (PBM)" 78 "Frank W. Murphy Manufacturing, Inc." 77 "Deere Power Systems Group" 76 "unused" 75 "Deere & Co. Agricultural Division" 74 "Eaton Axle-Brake Division" 73 "LeTourneau, Inc." 72 "Sisu Corporation" 71 "Vansco Electronics Ltd." 70 "Flex-Coil Limited" 69 "Trimble Navigation" 68 "Scania" 67 "Funk Manufacturing Company" 66 "John Deere Construction Equipment Division" 65 "MAN Nutzfahrzeuge AG" 64 "unused" 63 "ZF Industries Inc." 62 "Wabco" 61 "Volvo Truck Corp." 60 "Volvo Trucks North America Inc." 59 "VES Inc." 58 "SPX Corporation, OTC Division" 57 "Sauer-Danfoss Co." 56 "SAIC" 55 "Ryder System Inc." 54 "Meritor Wabco" 53 "Continental Automotive Systems US, Inc." 52 "Meritor Automotive, Inc." 51 "Robert Bosch GmbH" 50 "Robert Bosch Corp" 49 "RE America Inc." 48 "Pollak Alphabet" 47 "Phillips Semiconductor" 46 "Noregon Systems, Inc" 45 "PACCAR" 44 "Nippondenso Co. Ltd." 43 "International Truck and Engine Corp. Vehicle Electronics" 42 "International Truck and Engine Corp. Engine Electronics" 41 "Motorola Inc." 40 "Motorola AIEG Inc." 39 "Microfirm Inc." 38 "Micro Processor Systems Inc." 37 "Mack Trucks Inc." 36 "Lucas Ltd." 35 "Kenworth Truck Co." 34 "Kelsey Hayes Co." 33 "John Deere" 32 "Jacobs Vehicle Systems" 31 "J Pollak Corp." 30 "Isuzu Motors Ltd." 29 "Hino Motors Ltd." 28 "Grote Ind. Inc." 27 "GMC" 26 "General Motors Corp., Service Technology Group" 25 "Daimler Trucks North America LLC" 24 "Ford Motor Co., Vehicle Controls" 23 "Ford Motor Co., Heavy Truck" 22 "Ford Motor Co., Electronic Concepts $ Systems" 21 "Echilin Inc., Midland Brake Inc." 20 "Eaton Ltd" 19 "Eaton Corp. Trucking Info Services" 18 "Eaton Corp, Transmission Division" 17 "Eaton Corp. Res & Dev" 16 "Eaton Corp." 15 "Dickey-John Corp." 14 "Detroit Diesel Corporation" 13 "Delco Electronics" 12 "Deere & Company, Precision Farming" 11 "Dearborn Group Inc." 10 "Cummins Engine Co." 9 "Chrysler Corp." 8 "Caterpillar Inc." 7 "Case Corp." 6 "Berifors Electronics AB" 5 "AMP Inc." 4 "Ametek-Dixson" 3 "Ametek, US Gauge Division" 2 "Allison Transmission, GMC" 1 "Allied Signal Inc." 0 "Reserved" 231 "Topcon Positioning Systems, Inc." 230 "Saucon Technologies" 229 "Garmin International Inc." 228 "ZF Marine Electronics" 227 "Lykketronic A/S" 226 "Monaco Coach Corporation" 225 "SKF" 224 "EMMI Network, S.L." 223 "Vaueo Retarder Co., Ltd." 263 "IMMI" 262 "HydraForce, Inc" 261 "Red Dot Corporation" 260 "Reichhardt GmbH" 259 "Jetter AG" 258 "ARAG" 257 "Honda Motor Co., Ltd" 256 "Tyco Electronics AMP" 255 "MEAS France" 254 "GE Sensing" 253 "Mobile Control Systems" 298 "Holley Performance" 297 "Zonar Systems Inc" 296 "micro dynamics GmbH" 295 "BEP Marine" 294 "Grayhill Inc." 293 "Spyder Controls Corp." 292 "IKUSI - Angel Iglesias S.A." 291 "Groeneveld Transport Efficiency BV" 290 "Kuebler GmbH" 289 "Watlow" 288 "Mitsubishi FUSO Truck & Bus Corp." 287 "NTech Industries, Inc" 286 "Coelmo srl" 285 "Sea Recovery Corp" 284 "Mobile Tech Chile" 283 "CWF Hamilton & Co Ltd" 282 "Medallion Instrumentation Systems" 281 "Precision Governors LLC" 311 "Patrick Power Products" 310 "TECNORD srl" 309 "Krauss-Maffei Wegmann GmbH & Co. KG" 308 "Cyntrx" 307 "MAS Technologies" 306 "Sleipner Motor AB" 305 "NovAtel Inc" 304 "EmpirBus AB" 303 "CTS Corporation" 302 "Nissin Kogyo Co., LTD" 301 "Parker Hannifin (UK) Ltd FDE group" 300 "Systron Donner Automotive" 299 "Rauch Landmaschinen GmbH" 280 "Leica Geosystems Pty Ltd" 279 "Geometris LP" 278 "Takata Electronics" 277 "LHP Telematics" 276 "Aqua-Hot Heating Systems" 275 "Navico Egersund AS" 274 "LTW Technology Co., LTD" 273 "Active Research Limited" 272 "Gross Mechanical Laboratories, Inc" 327 "Sonceboz SA" 326 "Akron Brass Company" 325 "ASM Automation Sensorik Messtechnik GmbH" 324 "Snap-on Diagnostics" 323 "Mobileye Vision Technologies Ltd." 322 "MICHENKA s.r.o." 321 "Ultra Electronics, Electrics" 320 "Miedema Landbouwwerktuigenfabriek B.V." 319 "Cadec Global" 318 "SAT Plan" 317 "Navtronics Bvba" 316 "ITT Flow Control" 315 "Icom Incorporated" 314 "CSM GmbH" 313 "Ilmor Engineering, Inc" 312 "Lectronix, Inc." 271 "Cole Hersee" 270 "Tennant" 269 "Saft America Inc.,  Space & Defense Division" 268 "Accurate Technologies" 267 "Red Lion Controls, Inc" 266 "International Thermal Research Ltd" 265 "MTS Sensor Technologie GmbH" 264 "Autolync" 248 "Cooper Standard Automotive Active Systems Group" 247 "ePULSE" 246 "Class 1, Inc" 245 "Capstan Ag Systems, Inc." 244 "Techno-Matic" 243 "eRide, Inc." 242 "Kokusandenki Co. Ltd" 241 "Schneider Automation SAS " 240 "Vanair Mfg" 239 "May & Scofield Ltd" 238 "ZF Friedrichshafen AG" 237 "Agtron Enterprises Inc" 236 "Norac Systems International Inc" 235 "SailorMade Marine Telemetry - Tetra Technology Ltd." 234 "Mondial electronic GmbH" ;
VAL_ 2632384254 ErrorCodeChangeFont6 0 "NoErrors" 1 "GeneralError" ;
VAL_ 2632384254 Hardware6 0 "VT does not support intermediate coordinates during a drag operation" 1 "VT supports intermediate coordinates during a drag operation" ;
VAL_ 2632384254 KeyObjectParentID 0 "KeyHasBeenReleased" 1 "KeyHasBeenPressed" 2 "KeyIsStillPressed" ;
VAL_ 2632384254 ButtonObjectParentID 0 "KeyHasBeenReleased" 1 "KeyHasBeenPressed" 2 "KeyIsStillPressed" ;
VAL_ 2632384254 VTSelectInputObjectIsEdited 0 "ObjectIsNotEdited" 1 "ObjectIsOpenForEditing" ;
VAL_ 2632384254 ErrorCodeHideShowObj1 0 "NoErrors" 1 "ReferencesToMissingObjects" ;
VAL_ 2632384254 ErrorCodeSelectObject1 1 "ObjectIsDisabled" 0 "NoErrors" ;
VAL_ 2632384254 ErrorCodeChangeColour1 0 "NoErrors" 1 "InvalidObjectID" ;
VAL_ 2632384254 ErrorCodeChangeAttribute1 0 "NoErrors" 1 "InvalidObjectID" ;
VAL_ 2632384254 ErrorCodeChangePriority1 0 "NoErrors" 1 "InvalidObjectID" ;
VAL_ 2632384254 ErrorCodeGraphicsContextCmd1 1 "InvalidObjectID" 0 "NoError" ;
VAL_ 2632384254 ErrorCodeHideShowObj2 0 "NoErrors" 1 "InvalidObjectID" ;
VAL_ 2632384254 ErrorCodeEnableDisableObj1 0 "NoErrors" 1 "InvalidObjectID" ;
VAL_ 2632384254 ErrorCodeSelectObject2 0 "NoErrors" 1 "InvalidObjectID" ;
VAL_ 2632384254 ErrorCodeChangeColour2 0 "NoErrors" 1 "InvalidColourCode" ;
VAL_ 2632384254 ErrorCodeChangeAttribute2 0 "NoErrors" 1 "InvalidAttributeID" ;
VAL_ 2632384254 ErrorCodeChangePriority2 0 "NoErrors" 1 "InvalidPriority" ;
VAL_ 2632384254 ErrorCodeGraphicsContextCmd2 1 "InvalidCommandID" 0 "NoError" ;
VAL_ 2632384254 ErrorCodeEnableDisableObj2 0 "NoErrors" 1 "CommandError" ;
VAL_ 2632384254 ErrorCodeSelectObject3 0 "NoErrors" 1 "ObjectIsNotVisible" ;
VAL_ 2632384254 ErrorCodeChangeAttribute3 0 "NoErrors" 1 "InvalidValue" ;
VAL_ 2632384254 ErrorCodeGraphicsContextCmd3 1 "InvalidParameter" 0 "NoError" ;
VAL_ 2632384254 ErrorCodeHideShowObj3 0 "NoErrors" 1 "GeneralError" ;
VAL_ 2632384254 ErrorCodeEnableDisableObj3 1 "Could not complete. Operator inp" 0 "NoErrors" ;
VAL_ 2632384254 ErrorCodeSelectObject4 0 "NoErrors" 1 "CouldNotComplete" ;
VAL_ 2632384254 ErrorCodeGraphicsContextCmd4 1 "CommandWillProduceInvalidResults" 0 "NoError" ;
VAL_ 2632384254 ErrorCodeEnableDisableObj4 0 "NoErrors" 1 "GeneralError" ;
VAL_ 2632384254 ErrorCodeSelectObject5 0 "NoErrors" 1 "GeneralError" ;
VAL_ 2632384254 ErrorCodeChangeColour3 0 "NoErrors" 1 "GeneralError" ;
VAL_ 2632384254 ErrorCodeChangeAttribute4 0 "NoErrors" 1 "ValueInUse" ;
VAL_ 2632384254 ErrorCodeChangePriority3 0 "NoErrors" 1 "GeneralError" ;
VAL_ 2632384254 ErrorCodeGraphicsContextCmd5 1 "GeneralError" 0 "NoError" ;
VAL_ 2632384254 ErrorCodeSelectObject6 0 "NoErrors" 1 "InvalidOptionValue" ;
VAL_ 2632384254 ErrorCodeVTChangeSoftKeyMask1 0 "NoError" 1 "InvalidDataOrAlarmMaskObjectID" ;
VAL_ 2632384254 TouchState 255 "Pressed" 2 "Held" 1 "Pressed" 0 "Released" ;
VAL_ 2632384254 ErrorCodeChangeChildLocation1 0 "NoErrors" 1 "InvalidParentObjectID" ;
VAL_ 2632384254 ErrorCodeChangeSoftKeyMask1 0 "NoErrors" 1 "InvalidDataOrAlarmMaskObjectID" ;
VAL_ 2632384254 ErrorCodeChangePosInvalidParent 0 "NoErrors" 1 "InvalidParentObjectID" ;
VAL_ 2632384254 FontSize_8x8 0 "NotSupported" 1 "Supported" ;
VAL_ 2632384254 AcknowledgmentStoreVersion 0 "SuccessfullyStored" 2 "VersionLabelIsNotCorrect" 4 "InsufficientMemoryAvailable" 8 "GeneralError" ;
VAL_ 2632384254 AcknowledgmentLoadVersion 0 "SuccessfullyLoaded" 2 "VersionLabelNotCorrectOrUnknown" 4 "InsufficientMemoryAvailable" 8 "GeneralError" ;
VAL_ 2632384254 AcknowledgmentDeleteVersion 0 "SuccessfullyDeleted" 2 "VersionLabelIsNotCorrect" 4 "NA" 8 "GeneralError" ;
VAL_ 2632384254 ErrorCodeVtObjPoolError1 0 "NoErrors" 1 "UnsupportedMethodOrAttribute" ;
VAL_ 2632384254 ErrorCodeVTChangeSoftKeyMask2 0 "NoError" 1 "InvalidSoftKeyMaskObjectID" ;
VAL_ 2632384254 ErrorCodeChangeChildLocation2 0 "NoErrors" 1 "InvalidObjectID" ;
VAL_ 2632384254 ErrorCodeChangeSoftKeyMask2 0 "NoErrors" 1 "InvalidSoftKeyMaskObjectID" ;
VAL_ 2632384254 ErrorCodeChangeStrObjectID 0 "NoErrors" 1 "InvalidObjectID" ;
VAL_ 2632384254 ErrorCodeChangePosInvalidObject 0 "NoErrors" 1 "InvalidObjectID" ;
VAL_ 2632384254 FontSize_8x12 0 "NotSupported" 1 "Supported" ;
VAL_ 2632384254 ErrorCodeVtObjPoolError2 0 "NoErrors" 1 "UnknownObjectReference" ;
VAL_ 2632384254 ErrorCodeVTChangeSoftKeyMask3 0 "NoError" 1 "MissingObjects" ;
VAL_ 2632384254 ErrorCodeChangeSoftKeyMask3 0 "NoErrors" 1 "Missing Objects" ;
VAL_ 2632384254 ErrorCodeChangeStrTooLong 0 "NoErrors" 1 "StringTooLong" ;
VAL_ 2632384254 FontSize_12x16 0 "NotSupported" 1 "Supported" ;
VAL_ 2632384254 ErrorCodeVtObjPoolError3 0 "NoErrors" 1 "RecursiveObjectReference" ;
VAL_ 2632384254 ErrorCodeVTChangeSoftKeyMask4 0 "NoError" 1 "MaskOrChildObjectHasErrors" ;
VAL_ 2632384254 ErrorCodeChangeSoftKeyMask4 0 "NoErrors" 1 "Mask or child object has errors" ;
VAL_ 2632384254 ErrorCodeChangeStrError 0 "NoErrors" 1 "GeneralError" ;
VAL_ 2632384254 FontSize_16x16 0 "NotSupported" 1 "Supported" ;
VAL_ 2632384254 ErrorCodeVtObjPoolError4 0 "NoErrors" 1 "OtherError" ;
VAL_ 2632384254 ErrorCodeChangeStrValueInUse 0 "NoErrors" 1 "ValueInUse" ;
VAL_ 2632384254 ErrorCodeVTChangeSoftKeyMask5 0 "NoError" 1 "GeneralError" ;
VAL_ 2632384254 ErrorCodeChangeChildLocation5 0 "NoErrors" 1 "GeneralError" ;
VAL_ 2632384254 ErrorCodeChangeSoftKeyMask5 0 "NoErrors" 1 "GeneralError" ;
VAL_ 2632384254 ErrorCodeChangePosInvalidError 0 "NoErrors" 1 "GeneralError" ;
VAL_ 2632384254 FontSize_16x24 0 "NotSupported" 1 "Supported" ;
VAL_ 2632384254 FontSize_24x32 0 "NotSupported" 1 "Supported" ;
VAL_ 2632384254 FontSize_32x32 0 "NotSupported" 1 "Supported" ;
VAL_ 2632384254 Status_2 1 "Shown" 0 "Hidden" ;
VAL_ 2632384254 BooleanValue 2 "EnabledStillHeld" 1 "Enabled" 0 "Disabled" ;
VAL_ 2632384254 SoftKeyCode 0 "AlarmACK" ;
VAL_ 2632384254 ErrorCodeObjectPool1 0 "NoErrors" 1 "MethodOrAttributeNotSupportedByV" ;
VAL_ 2632384254 Function 127 "Reserved" 126 "Reserved" 125 "Reserved" 124 "Reserved" 123 "Reserved" 122 "Reserved" 121 "Reserved" 120 "Reserved" 119 "Reserved" 118 "Reserved" 117 "Reserved" 116 "Reserved" 115 "Reserved" 114 "Reserved" 113 "Reserved" 112 "Reserved" 111 "Reserved" 110 "Reserved" 109 "Reserved" 108 "Reserved" 107 "Reserved" 106 "Reserved" 105 "Reserved" 104 "Reserved" 103 "Reserved" 102 "Reserved" 101 "Reserved" 42 "Water Pump Control" 41 "Lighting - Operator Controls" 40 "Seat Control" 39 "Ignition Control Module" 38 "Tire Pressure Control" 37 "Cab Controller" 36 "Pneumatic - System Controller" 35 "Suspension - System Controller" 34 "Hydraulic Pump Controller" 33 "System Monitor" 32 "Headway Controller" 31 "Propulsion Battery Charger" 30 "Management Computer" 29 "Virtual Terminal (in cab)" 28 "Off Vehicle Gateway" 27 "Power TakeOff (Secondary or Front)" 26 "Body Controller" 25 "Network Interconnect ECU" 24 "Vehicle Security" 23 "Vehicle Navigation" 22 "Aerodynamic Control" 21 "Cab Climate Control" 20 "Trip Recorder" 19 "Instrument Cluster" 18 "Suspension - Drive Axle" 17 "Suspension - Steer Axle" 16 "Steering Controller" 15 "Fuel System" 14 "Cruise Control" 13 "Retarder - Driveline" 12 "Retarder - Engine" 11 "Brakes - Drive Axle" 10 "Brakes - Steer Axle" 9 "Brakes - System Controller" 8 "Axle - Drive" 7 "Axle - Steering" 6 "Power TakeOff - (Main or Rear)" 5 "Shift Control/Console" 4 "Battery Pack Monitor" 3 "Transmission" 2 "Electric Propulsion Control" 1 "Auxiliary Power Unit (APU)" 0 "Engine" 100 "Reserved" 99 "Reserved" 98 "Reserved" 97 "Reserved" 96 "Reserved" 95 "Reserved" 94 "Reserved" 93 "Reserved" 92 "Reserved" 91 "Reserved" 90 "Reserved" 89 "Reserved" 88 "Reserved" 87 "Reserved" 86 "Reserved" 85 "Reserved" 84 "Reserved" 83 "Reserved" 82 "Reserved" 81 "Reserved" 80 "Reserved" 79 "Reserved" 78 "Reserved" 77 "Fuel Properties Sensor" 76 "Temperature Sensor" 75 "Supplemental Fan" 74 "Lubrication System" 73 "Rollover Detection Control" 72 "Coolant Valve Controller" 71 "Transfer Case Control" 70 "Auxiliary Regeneration Device" 69 "Engine Emission Aftertreatement System" 68 "Aftertreatment system gas measurement" 67 "Electrical System Controller" 66 "I/O Controller" 65 "Gas Flow Measurement" 64 "Endurance Braking" 63 "Engine Valve Controller" 62 "On-Board Diagnostic Unit" 61 "File Server/Printer" 60 "Cab Display" 59 "Starter" 58 "Fan Drive Control" 57 "Steering Column Unit" 56 "Communications Unit, Radio" 55 "Communications Unit, Satellite" 54 "Communications Unit, Cellular" 53 "Alternator/Charging System" 52 "Chassis Controller" 51 "Forward-Looking Collision Warning System" 50 "Auxiliary Heater" 49 "Clutch/Converter Control" 48 "Ramp Control" 47 "Information System Controller" 46 "Oil Sensor Unit" 45 "Vehicle Dynamic Stability Control" 44 "Exhaust Emission Control" 43 "Transmission Display" ;
VAL_ 2632384254 ErrorCodeChangeListItem1 0 "NoErrors" 1 "InvalidListObjectID" ;
VAL_ 2632384254 ErrorCodeGetSupportedWideChars1 1 "TooManyRanges" 0 "NoError" ;
VAL_ 2632384254 FontSize_32x48 0 "NotSupported" 1 "Supported" ;
VAL_ 2632384254 VTBusyCode1 1 "VTIsBusyUpdatingVisibleMask" ;
VAL_ 2632384254 ErrorCodeObjectPool2 0 "NoErrors" 1 "UnknownObjectReference" ;
VAL_ 2632384254 ErrorCodeChangeListItem2 0 "NoErrors" 1 "InvalidListIndex" ;
VAL_ 2632384254 FontSize_48x64 0 "NotSupported" 1 "Supported" ;
VAL_ 2632384254 VTBusyCode2 1 "VTIsBusySavingDataToNonVolMemory" ;
VAL_ 2632384254 ErrorCodeObjectPool3 0 "NoErrors" 1 "GeneralError" ;
VAL_ 2632384254 ErrorCodeChangeListItem3 0 "NoErrors" 1 "InvalidNewListItemObjectID" ;
VAL_ 2632384254 FontSize_64x64 0 "NotSupported" 1 "Supported" ;
VAL_ 2632384254 VTBusyCode3 1 "VTIsBusyExecutingCommand" ;
VAL_ 2632384254 ErrorCodeObjectPool4 0 "NoErrors" 1 "ObjectPoolWasDeletedFromVolatile" ;
VAL_ 2632384254 FontSize_64x96 0 "NotSupported" 1 "Supported" ;
VAL_ 2632384254 VTBusyCode4 1 "VTIsBusyExecutingMacro" ;
VAL_ 2632384254 ErrorCodeChangeListItem4 0 "NoErrors" 1 "ValueInUse" ;
VAL_ 2632384254 ErrorCodeChangeListItem5 0 "NoErrors" 1 "ValueInUse" ;
VAL_ 2632384254 ErrorCodeGetSupportedWideChars2 1 "GeneralError" 0 "NoError" ;
VAL_ 2632384254 FontSize_96x128 0 "NotSupported" 1 "Supported" ;
VAL_ 2632384254 VTBusyCode5 1 "VTIsBusyParsingAnObjectPool" ;
VAL_ 2632384254 FontSize_128x128 0 "NotSupported" 1 "Supported" ;
VAL_ 2632384254 VTBusyCode7 1 "AuxiliaryControlsLearnModeActive" ;
VAL_ 2632384254 FontSize_128x192 0 "NotSupported" 1 "Supported" ;
VAL_ 2632384254 VTBusyCode8 1 "VTIsOutOfMemory" ;
VAL_ 2632384254 OperatingState1 1 "LearnModeActive" 0 "LearnModeInactive" ;
VAL_ 2632384254 ErrorCodeChangePolygonScale1 1 "InvalidObjectId" 0 "NoError" ;
VAL_ 2632384254 FontType_BoldText 0 "NotSupported" 1 "Supported" ;
VAL_ 2632384254 OperatingState2 1 "InputActivatedInLearnMode" 0 "InputNotActivatedInLearnMode" ;
VAL_ 2632384254 FontType_CrossedOutText 0 "NotSupported" 1 "Supported" ;
VAL_ 2632384254 FontType_UnderlinedText 0 "NotSupported" 1 "Supported" ;
VAL_ 2632384254 FontType_ItalicsText 0 "NotSupported" 1 "Supported" ;
VAL_ 2632384254 ErrorCodeChangePolygonScale5 1 "GeneralError" 0 "NoError" ;
VAL_ 2632384254 FontType_InvertedText 0 "NotSupported" 1 "Supported" ;
VAL_ 2632384254 FontType_FlashInverted 0 "NotSupported" 1 "Supported" ;
VAL_ 2632384254 FontType_FlashHidden 0 "NotSupported" 1 "Supported" ;
VAL_ 2632384254 FontType_ProportionalFont 0 "NotSupported" 1 "Supported" ;
VAL_ 2632384254 IndustryGroup 0 "Global" 1 "On-Highway" 2 "Agricultural and Forestry" 3 "Construction" 4 "Marine" 5 "IndustrialProcessCtrlStationary" 7 "Reserved for SAE" ;
VAL_ 2632384254 ErrorCodeChangeAttribute5 0 "NoErrors" 1 "GeneralError" ;
VAL_ 2632384254 StoreAsPreferredAssignment 1 "DoNotStoreAssignment" 0 "StoreAssignment" ;
VAL_ 2565340926 AuxCapabilitiesRequestType 1 "RequestCapabilitiesOfAuxFunctions" 0 "RequestCapabilitiesOfAuxiliaryInputs" ;
VAL_ 2565340926 VTFunctionECUtoVT 39 "AuxiliaryCapabilitiesRequest" 214 "ExtendedDeleteVersion" 213 "ExtendedLoadVersion" 212 "ExtendedStoreVersion" 211 "ExtendedGetVersions" 188 "ExecuteExtendedMacro" 197 "GetSupportedObjects" 187 "Identify VT" 36 "AuxiliaryAssignmentResponseType2" 33 "Auxiliary Input Status" 193 "GetSupported WideChars" 37 "AuxiliaryInputStatusEnableCommandResponse" 35 "AuxiliaryInputMaintenance" 190 "ExecuteMacro" 189 "LockUnlockMask" 34 "AuxiliaryPreferredAssignment" 9 "VTOnUserLayoutHideShowResponse" 186 "SelectColourMap" 185 "GetAttribute" 184 "GraphicsContextCommand" 183 "ChangePolygonScale" 182 "ChangePolygonPoint" 181 "SetObjectLabel" 0 "SoftKeyActivationResponse" 1 "ButtonActivationResponse" 2 "PointingEventResponse" 18 "EndOfObjectPool" 32 "AuxiliaryAssignmentResponse" 146 "ESC" 160 "ShowHideObject" 161 "EnableDisableObject" 162 "SelectInputObject" 163 "ControlAudioDevice" 164 "SetAudioVolume" 165 "ChangeChildLocation" 166 "ChangeSize" 167 "ChangeBackgroundColour" 168 "ChangeNumericValue" 169 "ChangeEndPoint" 170 "ChangeFontAttributes" 171 "ChangeLineAttributes" 172 "ChangeFillAttributes" 173 "ChangeActiveMask" 174 "ChangeSoftKeyMask" 175 "ChangeAttribute" 176 "ChangePriority" 177 "ChangeListItem" 178 "DeleteObjectPool" 192 "GetMemory" 194 "GetNumberOfSoftKeys" 195 "GetTextFontData" 199 "GetHardware" 208 "StoreVersion" 209 "LoadVersion" 210 "DeleteVersion" 223 "GetVersions" 255 "WorkingSetMaintenance" 179 "ChangeStringValue" 3 "VTSelectInputObjectResponse" 4 "VTESCResponse" 5 "VTChangeNumericValueResponse" 6 "VTChangeActiveMaskResponse" 7 "VTChangeSoftKeyMaskResponse" 196 "GetWindowMaskData" 17 "ObjectPoolTransfer" 180 "ChangeChildPosition" 8 "VTChangeStringValueResponse" ;
VAL_ 2565340926 KeyActivationCode 3 "KeyPressAborted" 0 "KeyHasBeenReleased" 1 "KeyHasBeenPressed" 2 "KeyIsStillHeld" ;
VAL_ 2565340926 ButtonActivationCode 3 "ButtonPressAborted" 0 "ButtonHasBeenUnlatched" 1 "ButtonHasBeenLatched" 2 "ButtonsStillHeld" ;
VAL_ 2565340926 MaskType 1 "Data" 2 "Alarm" ;
VAL_ 2565340926 LockUnlockCommand 1 "LockMask" 0 "UnlockMask" ;
VAL_ 2565340926 WSMaintenanceVersion 255 "CompliantWithVTVersion2AndPrior" 4 "CompliantWithVTVersion4" 3 "CompliantWithVTVersion3" ;
VAL_ 2565340926 KeyObjectID 0 "KeyHasBeenReleased" 1 "KeyHasBeenPressed" 2 "KeyIsStillHeld" ;
VAL_ 2565340926 ButtonObjectID 0 "ButtonHasBeenUnlatched" 1 "ButtonHasBeenLatched" 2 "ButtonsStillHeld" ;
VAL_ 2565340926 Status_1 1 "Shown" 0 "Hidden" ;
VAL_ 2565340926 AssignmentErrorNotAccepted 0 "AssignmentAccepted" 1 "AssignmentNotAccepted" ;
VAL_ 2565340926 ShowOrHide 0 "Hide" 1 "Show" ;
VAL_ 2565340926 EnableOrDisable 0 "Disable" 1 "Enable" ;
VAL_ 2565340926 SubCommandID 20 "CopyViewportToPictureGraphic" 19 "CopyCanvasToPictureGraphic" 18 "DrawVTObject" 17 "ChangeViewportSize" 16 "PanAndZoomViewport" 15 "ZoomViewport" 14 "PanViewport" 13 "DrawText" 12 "DrawPolygon" 11 "DrawClosedEllipse" 10 "DrawRectangle" 9 "DrawLine" 8 "DrawPoint" 7 "EraseRectangle" 6 "SetFontAttributesID" 5 "SetFillAttributesObjectID" 4 "SetLineAttributesObjectID" 3 "SetBackgroundColour" 2 "SetForegroundColour" 1 "MoveGraphicsCursor" 0 "SetGraphicsCursor" ;
VAL_ 2565340926 KeyObjectParentID 0 "KeyHasBeenReleased" 1 "KeyHasBeenPressed" 2 "KeyIsStillHeld" ;
VAL_ 2565340926 ButtonObjectParentID 0 "ButtonHasBeenUnlatched" 1 "ButtonHasBeenLatched" 2 "ButtonsStillHeld" ;
VAL_ 2565340926 TextOption 1 "Transparent" 0 "Opaque" ;
VAL_ 2565340926 Status_2 1 "Shown" 0 "Hidden" ;
VAL_ 2565340926 OperatingState1 1 "LearnModeActive" 0 "LearnModeInactive" ;
VAL_ 2565340926 OperatingState2 1 "InputActivatedInLearnMode" 0 "InputNotActivatedInLearnMode" ;
VAL_ 2565406462 ControlByte 3 "CannotRespond" 2 "AccessDenied" 1 "NACK" 0 "ACK" ;
VAL_ 2632777470 ControlByte 32 "BAM" 255 "Abort" 19 "EoMA" 17 "CTS" 16 "RTS" ;
VAL_ 2632777470 ConnectionAbortReason 7 "AnyOtherError" 6 "DuplicateSequenceNumber" 5 "BadSequenceNumber" 4 "UnexpectedDataTransferPacket" 3 "Timeout_CloseSession" 2 "NoFreeSystemResources" 1 "AlreadyInConnManagedSession" ;
VAL_ 2632777470 PGNumber 255 "NotAvailable" ;
VAL_ 2565865214 ManufacturerSpecific1 255 "NotAvailable" ;
VAL_ 2565865214 ManufacturerSpecific2 255 "NotAvailable" ;
VAL_ 2565865214 ManufacturerSpecific3 255 "NotAvailable" ;
VAL_ 2565865214 ManufacturerSpecific4 255 "NotAvailable" ;
VAL_ 2565865214 ManufacturerSpecific5 255 "NotAvailable" ;
VAL_ 2565865214 ManufacturerSpecific6 255 "NotAvailable" ;
VAL_ 2565865214 ManufacturerSpecific7 255 "NotAvailable" ;
VAL_ 2565865214 ManufacturerSpecific8 255 "NotAvailable" ;
VAL_ 2365458686 SpeedInfo_EngineSpeed 0 "EngineSpeedInfoNotAvailable" 1 "EngineSpeedInfoAvailable" ;
VAL_ 2365458686 SpeedInfo_GroundBasedSpeed 0 "GndBasedSpeedInfoNotAvailable" 1 "GndBasedSpeedInfoAvailable" ;
VAL_ 2365458686 SpeedInfo_WheelBasedSpeed 1 "WheelBasedSpeedInfoAvailable" 0 "WheelBasedSpeedInfoNotAvailable" ;
VAL_ 2365458686 PowerMgt_MaintainPower 1 "MainPwrMgtAvailable" 0 "MainPwrMgtNotAvailable" ;
VAL_ 2365458686 PowerMgt_MaxTimeTractorPower 0 "MaxTimeTractorPwrMgtNotAvailable" 1 "MaxTimeTractorPwrMgtAvailable" ;
VAL_ 2365458686 PowerMgt_KeySwitch 0 "KeySwitchPwrMgtNotAvailable" 1 "KeySwitchPwrMgtAvailable" ;
VAL_ 2365458686 TractorClass 0 "TECU_Class_1" 1 "TECU_Class_2" 2 "TECU_Class_3" 3 "NotAvailable" ;
VAL_ 2365458686 LanguageCmdStorageInTractorECU 0 "LangCmdNotAvailableInTractorECU" 1 "LangCmdAvailableInTractorECU" ;
VAL_ 2365458686 Lighting_MinimalSet 0 "MinSetNotAvailable" 1 "MinSetAvailable" ;
VAL_ 2365458686 PTOInfo_RearShaftEngagement 0 "PTOInfo_RearShaftEgtNotAvailable" 1 "PTOInfo_RearShaftEgtAvailable" ;
VAL_ 2365458686 PTOInfo_RearShaftSpeed 0 "PTOInfo_RearShaftSpdNotAvailable" 1 "PTOInfo_RearShaftSpdAvailable" ;
VAL_ 2365458686 HitchInfo_RearInWork 0 "HitchInfo_RearInWorkNotAvailable" 1 "HitchInfo_RearInWorkAvailable" ;
VAL_ 2365458686 HitchInfo_RearPosition 0 "HitchInfo_RearInPosNotAvailable" 1 "HitchInfo_RearInPosAvailable" ;
VAL_ 2365458686 EstimatedOrMeasuredAuxValveState 0 "EstOrMeasAuxValStatNotAvailable" 1 "EstOrMeasAuxValStatAvailable" ;
VAL_ 2365458686 Light_FullImplLightingMessageSet 0 "FullImplLightMsgSetNotAvailable" 1 "FullImplLightMsgSetAvailable" ;
VAL_ 2365458686 AddHitchParameter_RearDraft 0 "HitchInfo_RearDraftNotAvailable" 1 "HitchInfo_RearDraftAvailable" ;
VAL_ 2365458686 SpeedAndDist_WheelBasedDirection 0 "WheelBasedDirectionNotAvailable" 1 "WheelBasedDirectionAvailable" ;
VAL_ 2365458686 SpeedAndDist_WheelBasedDistance 0 "WheelBasedDistanceNotAvailable" 1 "WheelBasedDistanceAvailable" ;
VAL_ 2365458686 SpeedAndDist_GndBasedDirection 0 "GndBasedDirectionNotAvailable" 1 "GndBasedDirectionAvailable" ;
VAL_ 2365458686 SpeedAndDist_GndBasedDistance 0 "GndBasedDistanceNotAvailable" 1 "GndBasedDistanceAvailable" ;
VAL_ 2365458686 TimeDate 0 "TimeAndDateNotAvailable" 1 "TimeAndDateAvailable" ;
VAL_ 2365458686 LimitStatusReporting 1 "Facility available" 0 "Facility not available" ;
VAL_ 2365458686 AuxiliaryValveCmd 0 "AuxiliaryValveCmdsNotAvailable" 1 "AuxiliaryValveCmdsAvailable" ;
VAL_ 2365458686 PTOCmd_RearPTOEngagementCmd 0 "RearPTOEgtCmdNotAvailable" 1 "RearPTOEgtCmdAvailable" ;
VAL_ 2365458686 PTOCmd_RearPTOSpeedCmd 0 "RearPTOSpeedCmdNotAvailable" 1 "RearPTOSpeedCmdAvailable" ;
VAL_ 2365458686 HitchCmd_RearHitchPosition 0 "HitchRearPosNotAvailable" 1 "HitchRearPosAvailable" ;
VAL_ 2365458686 NavigPseudorangeNoiseStatistic 0 "NavigPsdoNoiseStatNotAvailable" 1 "NavigPsdoNoiseStatAvailable" ;
VAL_ 2365458686 NavigSystemPositionData 0 "NavigSysPosDataNotAvailable" 1 "NavigSysPosDataAvailable" ;
VAL_ 2365458686 NavigSystemHighOutputPosition 0 "NavigSysHOutPosDataNotAvailable" 1 "NavigSysHOutPosDataAvailable" ;
VAL_ 2365458686 PTOCmd_FrontPTOEngagementCmd 0 "FrontPTOEgtCmdNotAvailable" 1 "FrontPTOEgtCmdAvailable" ;
VAL_ 2365458686 PTOCmd_FrontPTOSpeedCmd 0 "FrontPTOSpeedCmdNotAvailable" 1 "FrontPTOSpeedCmdAvailable" ;
VAL_ 2365458686 HitchCmd_FrontHitchPosition 0 "FrontHitchPosNotAvailable" 1 "FrontHitchPosAvailable" ;
VAL_ 2365458686 AddHitchParameter__FrontDraft 0 "FrontDraftNotAvailable" 1 "FrontDraftAvailable" ;
VAL_ 2365458686 PTOInfo_FrontShaftEngagement 0 "FrontShaftEgtNotAvailable" 1 "FrontShaftEgtAvailable" ;
VAL_ 2365458686 PTOInfo_FrontShaftSpeed 0 "FrontShaftSpeedNotAvailable" 1 "FrontShaftSpeedAvailable" ;
VAL_ 2365458686 HitchInfo_FrontInWork 0 "FrontInWorkNotAvailable" 1 "FrontInWorkAvailable" ;
VAL_ 2365458686 HitchInfo_FrontPosition 0 "FrontPositionNotAvailable" 1 "FrontPositionAvailable" ;
VAL_ 2365458942 SpeedInfo_EngineSpeed 0 "EngineSpeedInfoNotAvailable" 1 "EngineSpeedInfoAvailable" ;
VAL_ 2365458942 SpeedInfo_GroundBasedSpeed 0 "GndBasedSpeedInfoNotAvailable" 1 "GndBasedSpeedInfoAvailable" ;
VAL_ 2365458942 SpeedInfo_WheelBasedSpeed 0 "WheelBasedSpeedInfoNotAvailable" 1 "WheelBasedSpeedInfoAvailable" ;
VAL_ 2365458942 PowerMgt_MaintainPower 0 "MainPwrMgtNotAvailable" 1 "MainPwrMgtAvailable" ;
VAL_ 2365458942 PowerMgt_MaxTimeTractorPower 0 "MaxTimeTractorPwrMgtNotAvailable" 1 "MaxTimeTractorPwrMgtAvailable" ;
VAL_ 2365458942 PowerMgt_KeySwitch 0 "KeySwitchPwrMgtNotAvailable" 1 "KeySwitchPwrMgtAvailable" ;
VAL_ 2365458942 TractorClass 0 "TECU_Class_1" 1 "TECU_Class_2" 2 "TECU_Class_3" 3 "NotAvailable" ;
VAL_ 2365458942 LanguageCmdStorageInTractorECU 0 "LangCmdNotAvailableInTractorECU" 1 "LangCmdAvailableInTractorECU" ;
VAL_ 2365458942 Lighting_MinimalSet 0 "MinSetNotAvailable" 1 "MinSetAvailable" ;
VAL_ 2365458942 PTOInfo_RearShaftEngagement 0 "PTOInfo_RearShaftEgtNotAvailable" 1 "PTOInfo_RearShaftEgtAvailable" ;
VAL_ 2365458942 PTOInfo_RearShaftSpeed 0 "PTOInfo_RearShaftSpdNotAvailable" 1 "PTOInfo_RearShaftSpdAvailable" ;
VAL_ 2365458942 HitchInfo_RearInWork 0 "HitchInfo_RearInWorkNotAvailable" 1 "HitchInfo_RearInWorkAvailable" ;
VAL_ 2365458942 HitchInfo_RearPosition 0 "HitchInfo_RearInPosNotAvailable" 1 "HitchInfo_RearInPosAvailable" ;
VAL_ 2365458942 EstimatedOrMeasuredAuxValveState 0 "EstOrMeasAuxValStatNotAvailable" 1 "EstOrMeasAuxValStatAvailable" ;
VAL_ 2365458942 Light_FullImplLightingMessageSet 0 "FullImplLightMsgSetNotAvailable" 1 "FullImplLightMsgSetAvailable" ;
VAL_ 2365458942 AddHitchParameter_RearDraft 0 "HitchInfo_RearDraftNotAvailable" 1 "HitchInfo_RearDraftAvailable" ;
VAL_ 2365458942 SpeedAndDist_WheelBasedDirection 0 "WheelBasedDirectionNotAvailable" 1 "WheelBasedDirectionAvailable" ;
VAL_ 2365458942 SpeedAndDist_WheelBasedDistance 0 "WheelBasedDistanceNotAvailable" 1 "WheelBasedDistanceAvailable" ;
VAL_ 2365458942 SpeedAndDist_GndBasedDirection 0 "GndBasedDirectionNotAvailable" 1 "GndBasedDirectionAvailable" ;
VAL_ 2365458942 SpeedAndDist_GndBasedDistance 0 "GndBasedDistanceNotAvailable" 1 "GndBasedDistanceAvailable" ;
VAL_ 2365458942 TimeDate 0 "TimeAndDateNotAvailable" 1 "TimeAndDateAvailable" ;
VAL_ 2365458942 LimitStatusReporting 1 "Facility available" 0 "Facility not available" ;
VAL_ 2365458942 AuxiliaryValveCmd 0 "AuxiliaryValveCmdsNotAvailable" 1 "AuxiliaryValveCmdsAvailable" ;
VAL_ 2365458942 PTOCmd_RearPTOEngagementCmd 0 "RearPTOEgtCmdNotAvailable" 1 "RearPTOEgtCmdAvailable" ;
VAL_ 2365458942 PTOCmd_RearPTOSpeedCmd 0 "RearPTOSpeedCmdNotAvailable" 1 "RearPTOSpeedCmdAvailable" ;
VAL_ 2365458942 HitchCmd_RearHitchPosition 0 "HitchRearPosNotAvailable" 1 "HitchRearPosAvailable" ;
VAL_ 2365458942 NavigPseudorangeNoiseStatistic 0 "NavigPsdoNoiseStatNotAvailable" 1 "NavigPsdoNoiseStatAvailable" ;
VAL_ 2365458942 NavigSystemPositionData 0 "NavigSysPosDataNotAvailable" 1 "NavigSysPosDataAvailable" ;
VAL_ 2365458942 NavigSystemHighOutputPosition 0 "NavigSysHOutPosDataNotAvailable" 1 "NavigSysHOutPosDataAvailable" ;
VAL_ 2365458942 PTOCmd_FrontPTOEngagementCmd 0 "FrontPTOEgtCmdNotAvailable" 1 "FrontPTOEgtCmdAvailable" ;
VAL_ 2365458942 PTOCmd_FrontPTOSpeedCmd 0 "FrontPTOSpeedCmdNotAvailable" 1 "FrontPTOSpeedCmdAvailable" ;
VAL_ 2365458942 HitchCmd_FrontHitchPosition 0 "FrontHitchPosNotAvailable" 1 "FrontHitchPosAvailable" ;
VAL_ 2365458942 AddHitchParameter__FrontDraft 0 "FrontDraftNotAvailable" 1 "FrontDraftAvailable" ;
VAL_ 2365458942 PTOInfo_FrontShaftEngagement 0 "FrontShaftEgtNotAvailable" 1 "FrontShaftEgtAvailable" ;
VAL_ 2365458942 PTOInfo_FrontShaftSpeed 0 "FrontShaftSpeedNotAvailable" 1 "FrontShaftSpeedAvailable" ;
VAL_ 2365458942 HitchInfo_FrontInWork 0 "FrontInWorkNotAvailable" 1 "FrontInWorkAvailable" ;
VAL_ 2365458942 HitchInfo_FrontPosition 0 "FrontPositionNotAvailable" 1 "FrontPositionAvailable" ;
VAL_ 2365459198 TractorControlLimitStatus1 7 "Not available" 6 "Non-recoverable Fault" 5 "Reserver" 4 "Reserved" 3 "Limited Low" 2 "Limited High" 1 "Operator Limited" 0 "Not limited" ;
VAL_ 2365459198 TractorControlModeResponse1 0 "DisableRemoteControl" 1 "EnableGroundSpeedCruiseControl" 2 "EnableWheelSpeedCruiseControl" 3 "EnableNavigationSpeedCruiseCtrl" 4 "EnableFrontHitchSlipCtrl" 5 "EnableRearHitchSlipControl" 6 "EnableFrontPTOSlipControl" 7 "EnableRearPTOSlipControl" 8 "EnableAuxiliaryValveSlipControl" 9 "EnableReduceSpeedSlipControl" 10 "EnableMaximumDraftPowerControl" 11 "EnableConstantPTOSpeedControl" 12 "EnCoPTOSpeedGndSpeedCruisCtrl" 13 "EnCoPTOSpeedWheelSpeedCruiseCtrl" 14 "EnCoPTOSpeedNavigSpeedCruisCtrl" 15 "EnableMinimumEngineSpeedControl" 16 "EnEngineEcoSpdGndSpeedCruiseCtrl" 17 "EnEngineEcoSpdWheelSpdCrusieCtrl" 18 "EnEngineEcoSpdNavigSpdCruiseCtrl" 19 "EnableFrontPTOTorqueControl" 20 "EnableRearPTOTorqueControl" 21 "EnableFrontDraftForceControl" 22 "EnableRearDraftForceControl" 23 "EnableGuidanceControl" 31 "NotAvailable" ;
VAL_ 2365459198 TractorControlLimitStatus2 7 "Not available" 6 "Non-recoverable Fault" 5 "Reserver" 4 "Reserved" 3 "Limited Low" 2 "Limited High" 1 "Operator Limited" 0 "Not limited" ;
VAL_ 2365459198 TractorControlModeResponse2 0 "DisableRemoteControl" 1 "EnableGroundSpeedCruiseControl" 2 "EnableWheelSpeedCruiseControl" 3 "EnableNavigationSpeedCruiseCtrl" 4 "EnableFrontHitchSlipCtrl" 5 "EnableRearHitchSlipControl" 6 "EnableFrontPTOSlipControl" 7 "EnableRearPTOSlipControl" 8 "EnableAuxiliaryValveSlipControl" 9 "EnableReduceSpeedSlipControl" 10 "EnableMaximumDraftPowerControl" 11 "EnableConstantPTOSpeedControl" 12 "EnCoPTOSpeedGndSpeedCruisCtrl" 13 "EnCoPTOSpeedWheelSpeedCruiseCtrl" 14 "EnCoPTOSpeedNavigSpeedCruisCtrl" 15 "EnableMinimumEngineSpeedControl" 16 "EnEngineEcoSpdGndSpeedCruiseCtrl" 17 "EnEngineEcoSpdWheelSpdCrusieCtrl" 18 "EnEngineEcoSpdNavigSpdCruiseCtrl" 19 "EnableFrontPTOTorqueControl" 20 "EnableRearPTOTorqueControl" 21 "EnableFrontDraftForceControl" 22 "EnableRearDraftForceControl" 23 "EnableGuidanceControl" 31 "NotAvailable" ;
VAL_ 2365459454 TractorControlModeCmd1 0 "DisableRemoteControl" 1 "EnableCruiseControl" 2 "EnableFrontHitchSlipControl" 3 "EnableRearHitchSlipControl" 4 "EnableFrontPTOSlipControl" 5 "EnableRearPTOSlipControl" 6 "EnableReduceSpeedSlipControl" 7 "EnableAuxiliaryValveSlipControl" 8 "EnableMaximumDraftPowerControl" 9 "EnableConstantPTOSpeedControl" 10 "EnableConstPTOSpeedCruiseControl" 11 "EnableMinimumEngineSpeedControl" 12 "EnableEngineEconomyCruiseControl" 13 "EnableFrontPTOTorqueControl" 14 "EnableRearPTOTorqueControl" 15 "EnableFrontDraftForceControl" 16 "EnableRearDraftForceControl" 17 "EnableGuidanceControl" 31 "DontCare" ;
VAL_ 2365459454 TactorControlModeCmd2 0 "DisableRemoteControl" 1 "EnableCruiseControl" 2 "EnableFrontHitchSlipControl" 3 "EnableRearHitchSlipControl" 4 "EnableFrontPTOSlipControl" 5 "EnableRearPTOSlipControl" 6 "EnableReduceSpeedSlipControl" 7 "EnableAuxiliaryValveSlipControl" 8 "EnableMaximumDraftPowerControl" 9 "EnableConstantPTOSpeedControl" 10 "EnableConstPTOSpeedCruiseControl" 11 "EnableMinimumEngineSpeedControl" 12 "EnableEngineEconomyCruiseControl" 13 "EnableFrontPTOTorqueControl" 14 "EnableRearPTOTorqueControl" 15 "EnableFrontDraftForceControl" 16 "EnableRearDraftForceControl" 17 "EnableGuidanceControl" 18 "UserDefinedControl" 31 "DoNotCare" ;
VAL_ 2633895166 VehicleSystem5 127 "Not Available" 0 "Ind. Process Control Stationary" ;
VAL_ 2633895166 VehicleSystem4 125 "Entertainment" 120 "Display" 85 "External Environment" 75 "Sensor Communication Interface" 35 "Electrical Generation" 100 "Deck, Cargo and Fishing Equipment" 90 "Internal Environment" 80 "Instrumentation/General Systems (deprecate)" 70 "Communications" 60 "Navigation" 50 "Propulsion" 40 "Steering and Control Surfaces" 30 "Electrical Distribution" 25 "Inter/Intranetwork Device" 20 "Safety Systems" 10 "System Tools" 127 "Not Available" 0 "Non-specific System" ;
VAL_ 2633895166 VehicleSystem3 8 "Grader" 7 "Four Wheel Drive Loader" 6 "Forklift" 5 "Excavator" 4 "Crawler" 3 "Backhoe" 2 "Articulated Dump Truck" 1 "Skid Steer Loader" 127 "Not Available" 0 "Non-specific System" ;
VAL_ 2633895166 VehicleSystem2 25 "Slurry Applicators" 24 "Utility Vehicles" 23 "Mulchers" 22 "Timber Processing Machines" 21 "Timber loaders" 20 "Forwarders" 19 "Timber Harvesters" 17 "Sensor Systems" 16 "Skidder" 15 "Earth Work" 14 "Special Crops" 13 "Powered Auxiliary Device" 12 "Farm Yard Operations" 11 "Transport/Trailer" 10 "Irrigation" 9 "Forage" 8 "Root Harvesters" 7 "Harvesters" 6 "Sprayers" 5 "Fertilizers" 4 "Planters/Seeders" 3 "Secondary Tillage" 2 "Tillage" 1 "Tractor" 127 "Not Available" 0 "Non-specific System" ;
VAL_ 2633895166 VehicleSystem1 2 "Trailer" 1 "Tractor" 127 "Not Available" 0 "Non-specific System" ;
VAL_ 2633895166 VehicleSystem 0 "Non-specific System" 127 "Not Available" ;
VAL_ 2633895166 ManufacturerCode 454 "NGK Spark Plug Co. Ltd" 453 "Cooper Bussmann" 452 "WIKA Alexander Wiegand SE & Co. KG" 451 "Parker Hannifin Corp" 450 "Dycor Technologies Ltd." 449 "Polaris Industries Inc" 448 "Stanadyne Corporation, Electronics Systems" 447 "Great Plains Mfg." 446 "CertTech, L.L.C." 445 "KAT MECHATRONIC, Electronic Product Division" 444 "ITT Power Solutions" 443 "SignalQuest, Inc." 442 "Horsch Maschinen GmbH" 441 "PTG Reifendruckregelsysteme GmbH" 440 "Cummins Power Generation" 439 "Hyundai Heavy Industries" 438 "Comar Systems Ltd" 437 "Digital Yacht Limited" 436 "Kinze Manufacturing" 435 "Zunhammer GmbH" 434 "Stored Energy Systems" 433 "Rowe Electronics" 432 "S&A Systems, Inc." 431 "Tohatsu Corporation" 430 "Auteq Telematica S.A." 479 "Vapor Bus International" 478 "OceanSat BV" 477 "OilQuick AB" 476 "Hummingbird Marine Electronics" 475 "GME" 474 "Persen Technologies Inc." 473 "Boss Industries, Inc." 472 "Tenneco Inc." 471 "Sea Cross Marine AB" 470 "SI-TEX Marine Electronics" 469 "RA Consulting GmbH" 468 "Tyco Fire Protection Products" 467 "Lely Industries N.V." 466 "Veethree Electronics and Marine LLC" 465 "Ashcroft Inc" 464 "Leach International Corporation" 463 "PROBOTIQ" 462 "IHI Shibaura Machinery Corporation" 461 "HAWE Hydraulik SE" 460 "San Giorgio S.E.I.N." 459 "Alltek Marine Electronics Corp" 458 "Control Solutions, Inc." 457 "RUSELPROM-ElectricDrive Ltd" 456 "General Kinetics" 455 "ADZ NAGANO GmbH" 429 "Rota Engineering Ltd." 428 "Mfg_428" 427 "Mfg_427" 426 "Mfg_426" 425 "Methode Electronics Inc, MDI" 424 "Odyne LLC" 423 "BSM Wireless, Inc." 422 "True Heading AB" 421 "Vertex Standard Co., Ltd" 420 "Vermeer Corporation, ACS Group" 419 "Fusion Electronics Ltd" 418 "Intellistick Inc" 417 "KZValve" 416 "Kubota Corporation" 415 "Valid Manufacturing Ltd." 414 "Cattron Group International" 413 "Datapross Nijbroek bv" 412 "WebTech Wireless Inc." 411 "Hy-Drive Technologies Ltd." 410 "COBO S.p.A. Divisione 3B6" 409 "Transfluid S.r.L." 408 "Corvus Energy Ltd." 407 "Comtech Mobile Datacom" 406 "Vecima Networks Inc." 405 "Wema System AS" 404 "Com Nav Marine Ltd" 403 "Trackwell ADS, Inc." 402 "Simma Software, Inc." 401 "Torqeedo GmbH" 400 "Livorsi Marine" 399 "ISEKI & Co., Ltd." 398 "Hilite International" 397 "Sanyo-kiki Co Ltd." 396 "Beyond Measure" 395 "GENTEC S.R.L." 394 "Capi 2 Nederland BV" 393 "Harvest Tec, Inc" 392 "Tianyuan Technology Co Ltd." 391 "Electronic Design for Industry, Inc" 390 "Partech Inc." 389 "Benchmark Electronics, Minnesota Division" 388 "Innomatix, LLC" 387 "Orscheln Products, LLC" 386 "JLG Automation BVBA" 385 "Johnson Outdoor Marine Electronics" 384 "Camano Light" 383 "MCL Industries" 382 "National Agricultural and Food Research Organization" 380 "Suntech International Ltd." 379 "Yamabiko Corporation" 378 "Glendinning Marine Products" 377 "ifm electronic gmbh" 376 "Quake Global" 375 "Williams Controls Inc." 372 "Delphi" 381 "B&G" 374 "Northern Lights, Inc." 373 "Electronic Design Inc." 371 "Heinzmann GmbH & Co. KG" 370 "Rolls-Royce Marine AS" 369 "Power Torque Engineering Ltd" 368 "HANSENHOF_electronic" 367 "Fliegl Agrartechnik" 366 "Viewnyx Corp." 365 "Digi-Star, LLC" 364 "OEM Controls Inc." 363 "BEI Duncan" 362 "Alois Poettinger Maschinenfabrik GmbH" 361 "InMach" 360 "HJS Emission Technology GmbH & Co KG" 359 "Ludwig Bergmann GmbH" 358 "Victron Energy BV" 357 "Hardi International A/S" 356 "Fischer Panda Generators, Inc" 355 "Mastervolt International B.V." 354 "Junkkari OY" 353 "Hegemon Electronics, Inc." 352 "SAME DEUTZ-FAHR" 351 "Thrane & Thrane" 350 "Noris Marine Systems GmbH & Co KG" 349 "Suonentiet" 348 "Amazonen Werke H. Dreyer" 347 "Honeywell" 346 "Control Solutions" 345 "Korean Maritime University" 344 "Parvus Corporation" 343 "Baumer Group" 342 "THOMAS MAGNETE GmbH" 341 "Boning GmbH & Co" 340 "Continental AG" 339 "Competence Center ISOBUS e.V." 338 "GRAF-SYTECO" 337 "Carraro S.p.A." 336 "APE s.r.o." 335 "Evo Electric Ltd" 334 "Takata-Petri AG" 333 "Hadley Products Corporation" 332 "HWH Corporation" 331 "Horton, Inc." 330 "Kidde Aerospace and Defense" 329 "Deif A/S" 328 "Qwerty Electronik AB" 252 "Sensor-Technik Wiedemann GmbH" 251 "German Agricultural Society" 250 "Kuhn Group" 249 "Schaltbau GmbH" 233 "Yacht Monitoring Solutions Inc." 232 "TSD Integrated Controls" 1863 "Thomas G. Faria Co." 1862 "Sanshin" 1861 "Vector CANtech" 1860 "MMP" 1859 "Kvasar AB" 1858 "Litton" 1857 "Simrad" 1856 "Trimble" 1855 "Furuno USA" 1854 "Northstar Technologies" 1853 "Japan Radio Co." 1852 "Navionics" 1851 "Raymarine" 1850 "Teleflex" 222 "Generac Power Systems, Inc." 221 "SiE" 220 "Beede Electrical Instrument Company, Inc." 219 "Cat OEM Solutions" 218 "Gits Manufacturing Company" 217 "RM Michaelides Software & Elektronik GmbH" 216 "Paneltronics Inc." 215 "Aetna Engineering/Fireboy-Xintex" 214 "MC elettronica Srl" 213 "CNH Belgium N.V." 212 "Sure Power Industries, Inc." 211 "DNA Group" 210 "Iteris, Inc." 209 "Bell Equip. Co. SA (PTY) LTD" 208 "Drew Technologies, Inc." 207 "Otto Engineering" 206 "port GmbH" 205 "SmarTire Systems Inc" 204 "The Morey Corporation" 203 "MILtronik GmbH" 202 "Curtis Instruments, Inc." 201 "Disenos y Tecnologia S.A." 200 "MGM Brakes" 199 "Actia Corp." 198 "Mystic Valley Communications" 197 "Mechron Power Systems" 196 "LEMKEN GmbH & Co. KG" 195 "General Engine Products" 194 "TriMark Corporation" 193 "Nobletec" 192 "Floscan" 191 "XATA Corporation" 190 "Hella KGaA Hueck & Co." 189 "QUALCOMM" 188 "EMP Corp." 187 "Air-Weigh" 186 "Altronic, Inc." 185 "Beede Electrical Instrument Company" 184 "EIA Electronics" 183 "KDS Controls, Inc." 182 "Vehicle Systems Engineering B.V." 181 "Coretronics, Inc." 180 "Smart Power Systems" 179 "TeeJet Technologies Denmark" 178 "Siemens VDO Automotive AG" 177 "Diagnostic System Associates" 176 "Moritz Aerospace" 175 "Veris Technologies, Inc." 174 "AB Volvo Penta" 173 "Ryeso, Inc." 172 "Yanmar Marine USA" 171 "Wachendorff Elektronik GmbH & Co. KG" 170 "Computronics Corporation Ltd." 169 "Marlin Technologies Inc." 168 "Xantrex" 167 "JLG Industries Inc." 166 "Phoenix International" 165 "CPAC Systems AB" 164 "DaimlerChrysler Off-Highway" 163 "BRP Inc." 162 "Axiomatic Technologies" 161 "Offshore Systems (UK) Limited" 160 "Nido" 159 "NTech Industries Inc." 158 "Firestone Industrial Products Company" 157 "ISSPRO Inc." 156 "ITT Industries - Cannon" 155 "Vetronix Corporation" 154 "Westerbeke Corporation" 153 "Woodward, Industrial Controls Division" 152 "elobau GmbH & Co. KG" 151 "Raven Industries Inc. - Flow Controls Division" 150 "Fleetguard" 149 "Holset" 148 "Blue Water Data, Inc." 147 "Nautibus Electronic GmbH" 146 "Maxima Technologies" 145 "MurCal Controls" 144 "Mercury Marine" 143 "W. Gmeiner GmbH & Co." 142 "TRW Automotive (Commercial Steering Systems)" 141 "Thales Navigation Ltd." 140 "Lowrance Electronics, Inc." 139 "Caterpillar Trimble Control Technologies (CTCT), LLC" 138 "Georg Fritzmeier GmbH & Co. KG" 137 "Maretron" 136 "Komatsu Ltd." 135 "Airmar Technology Corporation" 134 "Iris Technology Ltd." 133 "Bucher Schoerling GmbH" 132 "Mulag-Fahrzeugwerk" 131 "ITT Industries" 130 "Nido - Universal Machines B.V." 129 "OMNEX Control Systems, Inc." 128 "Gerhard Duecker GmbH & Co. KG" 127 "Holland USA" 126 "Driver Tech" 125 "Nevada Automotive Test Center" 124 "Hydac Electronic" 123 "Basler Electric" 122 "FG Wilson (Engineering) Limited" 121 "HED (Hydro Electronic Devices, Inc.)" 120 "RDS Technology Ltd." 119 "IntegriNautics" 118 "Intron GmbH" 117 "HUSCO International" 116 "BEELINE Technologies" 115 "NACCO Materials Handling Group, Inc." 114 "EControls, Inc." 113 "Stress-Tek, Inc." 112 "MECALAC" 111 "Maschinenfabrik Bernard Krone GmbH" 110 "EPIQ Sensor-Nite" 109 "TeeJet Technologies Denmark" 108 "WTK-Elecktronik GmbH" 107 "Grimme Landmaschinen GmbH & Co. KG" 106 "BAE Systems Controls, Inc." 105 "Kiepe Elektrik GmbH & Co. KG" 104 "Claas Selbstfahrende Erntemaschinen GmbH" 103 "CLAAS Agrosystems GmbH & Co. KG" 102 "AGCO GmbH & Co." 101 "Sensoria" 100 "VDO Technik AG" 99 "International Transmissions Ltd (ITL)" 98 "Mueller-Elektronik GmbH & Co." 97 "Ag Leader Technology, Inc." 96 "Mech@tronic IT GmbH" 95 "Pacific Insight Electronics Corp." 94 "CNH Global N.V." 93 "Perkins Engines Company Ltd." 92 "Ag-Chem Equipment Co., Inc." 91 "BSG Bodensee Steuergeraete GmbH" 90 "Knorr-Bremse SfN GmbH" 89 "Kverneland Group, Electronics Division" 88 "Satloc Precision GPS" 87 "J.C. Bamford Excavators Ltd (JCB)" 86 "C.E. Niehoff & Company" 85 "Kohler Co." 84 "New Holland UK Limited" 83 "Eaton VORAD Technologies" 82 "Bobcat/Ingersoll-Rand" 81 "Fire Research Corp" 80 "Twin Disc, Inc." 79 "Daimler Benz AG - Engine Division (PBM)" 78 "Frank W. Murphy Manufacturing, Inc." 77 "Deere Power Systems Group" 76 "unused" 75 "Deere & Co. Agricultural Division" 74 "Eaton Axle-Brake Division" 73 "LeTourneau, Inc." 72 "Sisu Corporation" 71 "Vansco Electronics Ltd." 70 "Flex-Coil Limited" 69 "Trimble Navigation" 68 "Scania" 67 "Funk Manufacturing Company" 66 "John Deere Construction Equipment Division" 65 "MAN Nutzfahrzeuge AG" 64 "unused" 63 "ZF Industries Inc." 62 "Wabco" 61 "Volvo Truck Corp." 60 "Volvo Trucks North America Inc." 59 "VES Inc." 58 "SPX Corporation, OTC Division" 57 "Sauer-Danfoss Co." 56 "SAIC" 55 "Ryder System Inc." 54 "Meritor Wabco" 53 "Continental Automotive Systems US, Inc." 52 "Meritor Automotive, Inc." 51 "Robert Bosch GmbH" 50 "Robert Bosch Corp" 49 "RE America Inc." 48 "Pollak Alphabet" 47 "Phillips Semiconductor" 46 "Noregon Systems, Inc" 45 "PACCAR" 44 "Nippondenso Co. Ltd." 43 "International Truck and Engine Corp. Vehicle Electronics" 42 "International Truck and Engine Corp. Engine Electronics" 41 "Motorola Inc." 40 "Motorola AIEG Inc." 39 "Microfirm Inc." 38 "Micro Processor Systems Inc." 37 "Mack Trucks Inc." 36 "Lucas Ltd." 35 "Kenworth Truck Co." 34 "Kelsey Hayes Co." 33 "John Deere" 32 "Jacobs Vehicle Systems" 31 "J Pollak Corp." 30 "Isuzu Motors Ltd." 29 "Hino Motors Ltd." 28 "Grote Ind. Inc." 27 "GMC" 26 "General Motors Corp., Service Technology Group" 25 "Daimler Trucks North America LLC" 24 "Ford Motor Co., Vehicle Controls" 23 "Ford Motor Co., Heavy Truck" 22 "Ford Motor Co., Electronic Concepts $ Systems" 21 "Echilin Inc., Midland Brake Inc." 20 "Eaton Ltd" 19 "Eaton Corp. Trucking Info Services" 18 "Eaton Corp, Transmission Division" 17 "Eaton Corp. Res & Dev" 16 "Eaton Corp." 15 "Dickey-John Corp." 14 "Detroit Diesel Corporation" 13 "Delco Electronics" 12 "Deere & Company, Precision Farming" 11 "Dearborn Group Inc." 10 "Cummins Engine Co." 9 "Chrysler Corp." 8 "Caterpillar Inc." 7 "Case Corp." 6 "Berifors Electronics AB" 5 "AMP Inc." 4 "Ametek-Dixson" 3 "Ametek, US Gauge Division" 2 "Allison Transmission, GMC" 1 "Allied Signal Inc." 0 "Reserved" 231 "Topcon Positioning Systems, Inc." 230 "Saucon Technologies" 229 "Garmin International Inc." 228 "ZF Marine Electronics" 227 "Lykketronic A/S" 226 "Monaco Coach Corporation" 225 "SKF" 224 "EMMI Network, S.L." 223 "Vaueo Retarder Co., Ltd." 263 "IMMI" 262 "HydraForce, Inc" 261 "Red Dot Corporation" 260 "Reichhardt GmbH" 259 "Jetter AG" 258 "ARAG" 257 "Honda Motor Co., Ltd" 256 "Tyco Electronics AMP" 255 "MEAS France" 254 "GE Sensing" 253 "Mobile Control Systems" 298 "Holley Performance" 297 "Zonar Systems Inc" 296 "micro dynamics GmbH" 295 "BEP Marine" 294 "Grayhill Inc." 293 "Spyder Controls Corp." 292 "IKUSI - Angel Iglesias S.A." 291 "Groeneveld Transport Efficiency BV" 290 "Kuebler GmbH" 289 "Watlow" 288 "Mitsubishi FUSO Truck & Bus Corp." 287 "NTech Industries, Inc" 286 "Coelmo srl" 285 "Sea Recovery Corp" 284 "Mobile Tech Chile" 283 "CWF Hamilton & Co Ltd" 282 "Medallion Instrumentation Systems" 281 "Precision Governors LLC" 311 "Patrick Power Products" 310 "TECNORD srl" 309 "Krauss-Maffei Wegmann GmbH & Co. KG" 308 "Cyntrx" 307 "MAS Technologies" 306 "Sleipner Motor AB" 305 "NovAtel Inc" 304 "EmpirBus AB" 303 "CTS Corporation" 302 "Nissin Kogyo Co., LTD" 301 "Parker Hannifin (UK) Ltd FDE group" 300 "Systron Donner Automotive" 299 "Rauch Landmaschinen GmbH" 280 "Leica Geosystems Pty Ltd" 279 "Geometris LP" 278 "Takata Electronics" 277 "LHP Telematics" 276 "Aqua-Hot Heating Systems" 275 "Navico Egersund AS" 274 "LTW Technology Co., LTD" 273 "Active Research Limited" 272 "Gross Mechanical Laboratories, Inc" 327 "Sonceboz SA" 326 "Akron Brass Company" 325 "ASM Automation Sensorik Messtechnik GmbH" 324 "Snap-on Diagnostics" 323 "Mobileye Vision Technologies Ltd." 322 "MICHENKA s.r.o." 321 "Ultra Electronics, Electrics" 320 "Miedema Landbouwwerktuigenfabriek B.V." 319 "Cadec Global" 318 "SAT Plan" 317 "Navtronics Bvba" 316 "ITT Flow Control" 315 "Icom Incorporated" 314 "CSM GmbH" 313 "Ilmor Engineering, Inc" 312 "Lectronix, Inc." 271 "Cole Hersee" 270 "Tennant" 269 "Saft America Inc.,  Space & Defense Division" 268 "Accurate Technologies" 267 "Red Lion Controls, Inc" 266 "International Thermal Research Ltd" 265 "MTS Sensor Technologie GmbH" 264 "Autolync" 248 "Cooper Standard Automotive Active Systems Group" 247 "ePULSE" 246 "Class 1, Inc" 245 "Capstan Ag Systems, Inc." 244 "Techno-Matic" 243 "eRide, Inc." 242 "Kokusandenki Co. Ltd" 241 "Schneider Automation SAS " 240 "Vanair Mfg" 239 "May & Scofield Ltd" 238 "ZF Friedrichshafen AG" 237 "Agtron Enterprises Inc" 236 "Norac Systems International Inc" 235 "SailorMade Marine Telemetry - Tetra Technology Ltd." 234 "Mondial electronic GmbH" ;
VAL_ 2633895166 IndustryGroup 6 "Reserved for SAE" 0 "Global" 1 "On-Highway" 2 "Agricultural and Forestry" 3 "Construction" 4 "Marine" 5 "IndustrialProcessCtrlStationary" 7 "Reserved for SAE" ;
VAL_ 2633895166 Function 127 "Reserved" 126 "Reserved" 125 "Reserved" 124 "Reserved" 123 "Reserved" 122 "Reserved" 121 "Reserved" 120 "Reserved" 119 "Reserved" 118 "Reserved" 117 "Reserved" 116 "Reserved" 115 "Reserved" 114 "Reserved" 113 "Reserved" 112 "Reserved" 111 "Reserved" 110 "Reserved" 109 "Reserved" 108 "Reserved" 107 "Reserved" 106 "Reserved" 105 "Reserved" 104 "Reserved" 103 "Reserved" 102 "Reserved" 101 "Reserved" 42 "Water Pump Control" 41 "Lighting - Operator Controls" 40 "Seat Control" 39 "Ignition Control Module" 38 "Tire Pressure Control" 37 "Cab Controller" 36 "Pneumatic - System Controller" 35 "Suspension - System Controller" 34 "Hydraulic Pump Controller" 33 "System Monitor" 32 "Headway Controller" 31 "Propulsion Battery Charger" 30 "Management Computer" 29 "Virtual Terminal (in cab)" 28 "Off Vehicle Gateway" 27 "Power TakeOff (Secondary or Front)" 26 "Body Controller" 25 "Network Interconnect ECU" 24 "Vehicle Security" 23 "Vehicle Navigation" 22 "Aerodynamic Control" 21 "Cab Climate Control" 20 "Trip Recorder" 19 "Instrument Cluster" 18 "Suspension - Drive Axle" 17 "Suspension - Steer Axle" 16 "Steering Controller" 15 "Fuel System" 14 "Cruise Control" 13 "Retarder - Driveline" 12 "Retarder - Engine" 11 "Brakes - Drive Axle" 10 "Brakes - Steer Axle" 9 "Brakes - System Controller" 8 "Axle - Drive" 7 "Axle - Steering" 6 "Power TakeOff - (Main or Rear)" 5 "Shift Control/Console" 4 "Battery Pack Monitor" 3 "Transmission" 2 "Electric Propulsion Control" 1 "Auxiliary Power Unit (APU)" 0 "Engine" 100 "Reserved" 99 "Reserved" 98 "Reserved" 97 "Reserved" 96 "Reserved" 95 "Reserved" 94 "Reserved" 93 "Reserved" 92 "Reserved" 91 "Reserved" 90 "Reserved" 89 "Reserved" 88 "Reserved" 87 "Reserved" 86 "Reserved" 85 "Reserved" 84 "Reserved" 83 "Reserved" 82 "Reserved" 81 "Reserved" 80 "Reserved" 79 "Reserved" 78 "Reserved" 77 "Fuel Properties Sensor" 76 "Temperature Sensor" 75 "Supplemental Fan" 74 "Lubrication System" 73 "Rollover Detection Control" 72 "Coolant Valve Controller" 71 "Transfer Case Control" 70 "Auxiliary Regeneration Device" 69 "Engine Emission Aftertreatement System" 68 "Aftertreatment system gas measurement" 67 "Electrical System Controller" 66 "I/O Controller" 65 "Gas Flow Measurement" 64 "Endurance Braking" 63 "Engine Valve Controller" 62 "On-Board Diagnostic Unit" 61 "File Server/Printer" 60 "Cab Display" 59 "Starter" 58 "Fan Drive Control" 57 "Steering Column Unit" 56 "Communications Unit, Radio" 55 "Communications Unit, Satellite" 54 "Communications Unit, Cellular" 53 "Alternator/Charging System" 52 "Chassis Controller" 51 "Forward-Looking Collision Warning System" 50 "Auxiliary Heater" 49 "Clutch/Converter Control" 48 "Ramp Control" 47 "Information System Controller" 46 "Oil Sensor Unit" 45 "Vehicle Dynamic Stability Control" 44 "Exhaust Emission Control" 43 "Transmission Display" ;
VAL_ 2566787070 TimeFormatCmd 0 "Hour24" 1 "Hour12" 3 "NoAction" ;
VAL_ 2566787070 DecimalSymbolCmd 0 "CommaIsUsed" 1 "PointIsUsed" 3 "NoAction" ;
VAL_ 2566787070 DateFormatCmd 0 "ddmmyyyy" 1 "ddyyyymm" 2 "mmyyyydd" 3 "mmddyyyy" 4 "yyyymmdd" 5 "yyyyddmm" ;
VAL_ 2566787070 MassUnitCmd 0 "Metric" 1 "Imperial" 2 "TonsPounds" 3 "NoAction" ;
VAL_ 2566787070 VolumeUnitCmd 0 "Metric" 1 "Imperial" 2 "US" 3 "NoAction" ;
VAL_ 2566787070 AreaUnitCmd 0 "Metric" 1 "Imperial" 3 "NoAction" ;
VAL_ 2566787070 DistanceUnitCmd 0 "Metric" 1 "Imperial" 3 "NoAction" ;
VAL_ 2566787070 UnitsSystem 0 "Metric" 1 "Imperial" 2 "US" 3 "NoAction" ;
VAL_ 2566787070 ForceUnits 0 "Metric" 1 "Imperial" 2 "Reserved" 3 "NoAction" ;
VAL_ 2566787070 PressureUnits 0 "Metric" 1 "Imperial" 2 "Reserved" 3 "NoAction" ;
VAL_ 2566787070 TemperatureUnits 0 "Metric" 1 "Imperial" 2 "Reserved" 3 "NoAction" ;
VAL_ 2365460734 Valve0ValveState 0 "Blocked" 1 "Extend" 2 "Retract" 3 "Floating" 14 "ErrorIndication" 15 "DoNotCare" ;
VAL_ 2365460734 Valve0FailSafeMode 0 "Block" 1 "Float" 2 "ErrorIndication" 3 "NotAvailable" ;
VAL_ 2365460734 Valve0LimitStatus 7 "Not available" 6 "Non-recoverable Fault" 5 "Reserver" 4 "Reserved" 3 "Limited Low" 2 "Limited High" 1 "Operator Limited" 0 "Not limited" ;
VAL_ 2365460990 Valve1ValveState 0 "Blocked" 1 "Extend" 2 "Retract" 3 "Floating" 14 "ErrorIndication" 15 "DoNotCare" ;
VAL_ 2365460990 Valve1FailSafeMode 0 "Block" 1 "Float" 2 "ErrorIndication" 3 "NotAvailable" ;
VAL_ 2365460990 Valve1LimitStatus 7 "Not available" 6 "Non-recoverable Fault" 5 "Reserver" 4 "Reserved" 3 "Limited Low" 2 "Limited High" 1 "Operator Limited" 0 "Not limited" ;
VAL_ 2365461246 Valve2ValveState 0 "Blocked" 1 "Extend" 2 "Retract" 3 "Floating" 14 "ErrorIndication" 15 "DoNotCare" ;
VAL_ 2365461246 Valve2FailSafeMode 0 "Block" 1 "Float" 2 "ErrorIndication" 3 "NotAvailable" ;
VAL_ 2365461246 Valve2LimitStatus 7 "Not available" 6 "Non-recoverable Fault" 5 "Reserver" 4 "Reserved" 3 "Limited Low" 2 "Limited High" 1 "Operator Limited" 0 "Not limited" ;
VAL_ 2365461502 Valve3ValveState 0 "Blocked" 1 "Extend" 2 "Retract" 3 "Floating" 14 "ErrorIndication" 15 "DoNotCare" ;
VAL_ 2365461502 Valve3FailSafeMode 0 "Block" 1 "Float" 2 "ErrorIndication" 3 "NotAvailable" ;
VAL_ 2365461502 Valve3LimitStatus 7 "Not available" 6 "Non-recoverable Fault" 5 "Reserver" 4 "Reserved" 3 "Limited Low" 2 "Limited High" 1 "Operator Limited" 0 "Not limited" ;
VAL_ 2365461758 Valve4ValveState 0 "Blocked" 1 "Extend" 2 "Retract" 3 "Floating" 14 "ErrorIndication" 15 "DoNotCare" ;
VAL_ 2365461758 Valve4FailSafeMode 0 "Block" 1 "Float" 2 "ErrorIndication" 3 "NotAvailable" ;
VAL_ 2365461758 Valve4LimitStatus 7 "Not available" 6 "Non-recoverable Fault" 5 "Reserver" 4 "Reserved" 3 "Limited Low" 2 "Limited High" 1 "Operator Limited" 0 "Not limited" ;
VAL_ 2365462014 Valve5ValveState 0 "Blocked" 1 "Extend" 2 "Retract" 3 "Floating" 14 "ErrorIndication" 15 "DoNotCare" ;
VAL_ 2365462014 Valve5FailSafeMode 0 "Block" 1 "Float" 2 "ErrorIndication" 3 "NotAvailable" ;
VAL_ 2365462014 Valve5LimitStatus 7 "Not available" 6 "Non-recoverable Fault" 5 "Reserver" 4 "Reserved" 3 "Limited Low" 2 "Limited High" 1 "Operator Limited" 0 "Not limited" ;
VAL_ 2365462270 Valve6ValveState 0 "Blocked" 1 "Extend" 2 "Retract" 3 "Floating" 14 "ErrorIndication" 15 "DoNotCare" ;
VAL_ 2365462270 Valve6FailSafeMode 0 "Block" 1 "Float" 2 "ErrorIndication" 3 "NotAvailable" ;
VAL_ 2365462270 Valve6LimitStatus 7 "Not available" 6 "Non-recoverable Fault" 5 "Reserver" 4 "Reserved" 3 "Limited Low" 2 "Limited High" 1 "Operator Limited" 0 "Not limited" ;
VAL_ 2365462526 Valve7ValveState 0 "Blocked" 1 "Extend" 2 "Retract" 3 "Floating" 14 "ErrorIndication" 15 "DoNotCare" ;
VAL_ 2365462526 Valve7FailSafeMode 0 "Block" 1 "Float" 2 "ErrorIndication" 3 "NotAvailable" ;
VAL_ 2365462526 Valve7LimitStatus 7 "Not available" 6 "Non-recoverable Fault" 5 "Reserver" 4 "Reserved" 3 "Limited Low" 2 "Limited High" 1 "Operator Limited" 0 "Not limited" ;
VAL_ 2365462782 Valve8ValveState 0 "Blocked" 1 "Extend" 2 "Retract" 3 "Floating" 14 "ErrorIndication" 15 "DoNotCare" ;
VAL_ 2365462782 Valve8FailSafeMode 0 "Block" 1 "Float" 2 "ErrorIndication" 3 "NotAvailable" ;
VAL_ 2365462782 Valve8LimitStatus 7 "Not available" 6 "Non-recoverable Fault" 5 "Reserver" 4 "Reserved" 3 "Limited Low" 2 "Limited High" 1 "Operator Limited" 0 "Not limited" ;
VAL_ 2365463038 Valve9ValveState 0 "Blocked" 1 "Extend" 2 "Retract" 3 "Floating" 14 "ErrorIndication" 15 "DoNotCare" ;
VAL_ 2365463038 Valve9FailSafeMode 0 "Block" 1 "Float" 2 "ErrorIndication" 3 "NotAvailable" ;
VAL_ 2365463038 Valve9LimitStatus 7 "Not available" 6 "Non-recoverable Fault" 5 "Reserver" 4 "Reserved" 3 "Limited Low" 2 "Limited High" 1 "Operator Limited" 0 "Not limited" ;
SIG_VALTYPE_ 2565340926 ZoomValue : 1;
SIG_VALTYPE_ 2565340926 ZoomValue_PanZoom : 1;
SG_MUL_VAL_ 2632384254 AcknowledgmentStoreVersion VTFunctionVTtoECU 208-208, 212-212;
SG_MUL_VAL_ 2632384254 AcknowledgmentLoadVersion VTFunctionVTtoECU 209-209, 213-213;
SG_MUL_VAL_ 2632384254 AcknowledgmentDeleteVersion VTFunctionVTtoECU 210-210, 214-214;
SG_MUL_VAL_ 2565340926 AuxCapabilitiesRequestType VTFunctionECUtoVT 39-39;
SG_MUL_VAL_ 2565340926 MacroObjectID_2 VTFunctionECUtoVT 188-188;
SG_MUL_VAL_ 2565340926 ExtendedVersionLabelToStore VTFunctionECUtoVT 212-212;
SG_MUL_VAL_ 2565340926 ExtendedVersionLabelToLoad VTFunctionECUtoVT 213-213;
SG_MUL_VAL_ 2565340926 ExtendedVersionLabelToDelete VTFunctionECUtoVT 214-214;
SG_MUL_VAL_ 2565340926 ObjectId_1 VTFunctionECUtoVT 9-9;
SG_MUL_VAL_ 2565340926 SourceAddressOfAuxiliaryInputDev VTFunctionECUtoVT 32-32;
SG_MUL_VAL_ 2565340926 InputObjectId VTFunctionECUtoVT 33-33;
SG_MUL_VAL_ 2565340926 KeyActivationCode VTFunctionECUtoVT 0-0;
SG_MUL_VAL_ 2565340926 ButtonActivationCode VTFunctionECUtoVT 1-1;
SG_MUL_VAL_ 2565340926 XPosition VTFunctionECUtoVT 2-2;
SG_MUL_VAL_ 2565340926 VTSelectInputObjectID VTFunctionECUtoVT 3-3;
SG_MUL_VAL_ 2565340926 VTEscObjectID VTFunctionECUtoVT 4-4;
SG_MUL_VAL_ 2565340926 VTChangeNumericValueObjectID VTFunctionECUtoVT 5-5;
SG_MUL_VAL_ 2565340926 VTChangeActiveMaskObjectID VTFunctionECUtoVT 6-6;
SG_MUL_VAL_ 2565340926 VTChangeSoftKeyMaskParentID VTFunctionECUtoVT 7-7;
SG_MUL_VAL_ 2565340926 ChangeChildPositionParentOb_0000 VTFunctionECUtoVT 180-180;
SG_MUL_VAL_ 2565340926 ObjectPoolRecord VTFunctionECUtoVT 17-17;
SG_MUL_VAL_ 2565340926 AuxiliaryFunctionObjectID VTFunctionECUtoVT 36-36;
SG_MUL_VAL_ 2565340926 NumberOfInpuUnits VTFunctionECUtoVT 34-34;
SG_MUL_VAL_ 2565340926 AuxModelIdentification VTFunctionECUtoVT 35-35;
SG_MUL_VAL_ 2565340926 InputStatusObjectId VTFunctionECUtoVT 37-37;
SG_MUL_VAL_ 2565340926 ObjectToShowHideID VTFunctionECUtoVT 160-160;
SG_MUL_VAL_ 2565340926 ObjectoEnableDisbaleID VTFunctionECUtoVT 161-161;
SG_MUL_VAL_ 2565340926 SelectInputObjectID VTFunctionECUtoVT 162-162;
SG_MUL_VAL_ 2565340926 NumberOfRepetitions_Audio VTFunctionECUtoVT 163-163;
SG_MUL_VAL_ 2565340926 AudioVolume VTFunctionECUtoVT 164-164;
SG_MUL_VAL_ 2565340926 ChangeChildLocationParentOb_0000 VTFunctionECUtoVT 165-165;
SG_MUL_VAL_ 2565340926 ObjectToSizeID VTFunctionECUtoVT 166-166;
SG_MUL_VAL_ 2565340926 ObjectToChangeColourID VTFunctionECUtoVT 167-167;
SG_MUL_VAL_ 2565340926 ObjectToChangeNumValueID VTFunctionECUtoVT 168-168;
SG_MUL_VAL_ 2565340926 ObjectToChangeEndPointID VTFunctionECUtoVT 169-169;
SG_MUL_VAL_ 2565340926 ObjectToChangeFontID VTFunctionECUtoVT 170-170;
SG_MUL_VAL_ 2565340926 ObjectToChangeLineAttributesID VTFunctionECUtoVT 171-171;
SG_MUL_VAL_ 2565340926 ObjectToChangeFillAttributesID VTFunctionECUtoVT 172-172;
SG_MUL_VAL_ 2565340926 WorkingSetObjectID VTFunctionECUtoVT 173-173;
SG_MUL_VAL_ 2565340926 MaskType VTFunctionECUtoVT 174-174;
SG_MUL_VAL_ 2565340926 ObjectToChangeAttributeID VTFunctionECUtoVT 175-175;
SG_MUL_VAL_ 2565340926 AlarmMaskObjectID VTFunctionECUtoVT 176-176;
SG_MUL_VAL_ 2565340926 ListInputObjectID VTFunctionECUtoVT 177-177;
SG_MUL_VAL_ 2565340926 ObjectToChangeStringValueID VTFunctionECUtoVT 179-179;
SG_MUL_VAL_ 2565340926 ParentObjectID VTFunctionECUtoVT 8-8;
SG_MUL_VAL_ 2565340926 ObjectToAssociateLabelWithID VTFunctionECUtoVT 181-181;
SG_MUL_VAL_ 2565340926 PolygonObjectToChangeID VTFunctionECUtoVT 182-182;
SG_MUL_VAL_ 2565340926 PolygonObjectToScaleID VTFunctionECUtoVT 183-183;
SG_MUL_VAL_ 2565340926 GraphicsContextObjectID VTFunctionECUtoVT 184-184;
SG_MUL_VAL_ 2565340926 ObjectToGetAttributeID VTFunctionECUtoVT 185-185;
SG_MUL_VAL_ 2565340926 ColourMapObjectID VTFunctionECUtoVT 186-186;
SG_MUL_VAL_ 2565340926 LockUnlockCommand VTFunctionECUtoVT 189-189;
SG_MUL_VAL_ 2565340926 MacroObjecID VTFunctionECUtoVT 190-190;
SG_MUL_VAL_ 2565340926 CodePlane VTFunctionECUtoVT 193-193;
SG_MUL_VAL_ 2565340926 VersionLabelToStore VTFunctionECUtoVT 208-208;
SG_MUL_VAL_ 2565340926 VersionLabelToLoad VTFunctionECUtoVT 209-209;
SG_MUL_VAL_ 2565340926 VersionLabelToDelete VTFunctionECUtoVT 210-210;
SG_MUL_VAL_ 2565340926 WSMaintenanceInitiating WSMaintenanceVersion 3-254;
SG_MUL_VAL_ 2565340926 AuxiliaryInputNumber VTFunctionECUtoVT 32-32;
SG_MUL_VAL_ 2565340926 WSMaintenanceVersion VTFunctionECUtoVT 255-255;
SG_MUL_VAL_ 2565340926 KeyObjectID VTFunctionECUtoVT 0-0;
SG_MUL_VAL_ 2565340926 ButtonObjectID VTFunctionECUtoVT 1-1;
SG_MUL_VAL_ 2565340926 Frequency_Audio VTFunctionECUtoVT 163-163;
SG_MUL_VAL_ 2565340926 DataOrAlarmMaskObjectID VTFunctionECUtoVT 174-174;
SG_MUL_VAL_ 2565340926 ObjectIDOfDataMaskToLock VTFunctionECUtoVT 189-189;
SG_MUL_VAL_ 2565340926 MemoryRequired VTFunctionECUtoVT 192-192;
SG_MUL_VAL_ 2565340926 FirstWideChar VTFunctionECUtoVT 193-193;
SG_MUL_VAL_ 2565340926 Status_1 VTFunctionECUtoVT 9-9;
SG_MUL_VAL_ 2565340926 AuxiliaryFunctionID VTFunctionECUtoVT 32-32;
SG_MUL_VAL_ 2565340926 YPosition VTFunctionECUtoVT 2-2;
SG_MUL_VAL_ 2565340926 VTSelectInputObjectStatus VTFunctionECUtoVT 3-3;
SG_MUL_VAL_ 2565340926 VTChangeSoftKeyMaskObjectID VTFunctionECUtoVT 7-7;
SG_MUL_VAL_ 2565340926 ObjectOfChangedStringValueID VTFunctionECUtoVT 8-8;
SG_MUL_VAL_ 2565340926 AssignmentErrorNotAccepted VTFunctionECUtoVT 36-36;
SG_MUL_VAL_ 2565340926 AuxInputEnable VTFunctionECUtoVT 37-37;
SG_MUL_VAL_ 2565340926 ShowOrHide VTFunctionECUtoVT 160-160;
SG_MUL_VAL_ 2565340926 EnableOrDisable VTFunctionECUtoVT 161-161;
SG_MUL_VAL_ 2565340926 SetFocusOpenForEditing VTFunctionECUtoVT 162-162;
SG_MUL_VAL_ 2565340926 ChangeChildPositionObjectID VTFunctionECUtoVT 180-180;
SG_MUL_VAL_ 2565340926 NewWidth VTFunctionECUtoVT 166-166;
SG_MUL_VAL_ 2565340926 NewBackgroundColour VTFunctionECUtoVT 167-167;
SG_MUL_VAL_ 2565340926 Width VTFunctionECUtoVT 169-169;
SG_MUL_VAL_ 2565340926 FontColour VTFunctionECUtoVT 170-170;
SG_MUL_VAL_ 2565340926 LineColour VTFunctionECUtoVT 171-171;
SG_MUL_VAL_ 2565340926 FillType VTFunctionECUtoVT 172-172;
SG_MUL_VAL_ 2565340926 NewActiveMaskObjectID VTFunctionECUtoVT 173-173;
SG_MUL_VAL_ 2565340926 AttributeID VTFunctionECUtoVT 185-185;
SG_MUL_VAL_ 2565340926 NewPriority VTFunctionECUtoVT 176-176;
SG_MUL_VAL_ 2565340926 ListIndex VTFunctionECUtoVT 177-177;
SG_MUL_VAL_ 2565340926 ChangeChildLocationObjectID VTFunctionECUtoVT 165-165;
SG_MUL_VAL_ 2565340926 StringVariableObjectID VTFunctionECUtoVT 181-181;
SG_MUL_VAL_ 2565340926 IndexOfThePointToReplace VTFunctionECUtoVT 182-182;
SG_MUL_VAL_ 2565340926 NewWidthAttribute VTFunctionECUtoVT 183-183;
SG_MUL_VAL_ 2565340926 SubCommandID VTFunctionECUtoVT 184-184;
SG_MUL_VAL_ 2565340926 AttributeIDToChange VTFunctionECUtoVT 175-175;
SG_MUL_VAL_ 2565340926 TotalNumberOfBytes VTFunctionECUtoVT 179-179;
SG_MUL_VAL_ 2565340926 Value1 VTFunctionECUtoVT 33-33;
SG_MUL_VAL_ 2565340926 ObjectId_2 VTFunctionECUtoVT 9-9;
SG_MUL_VAL_ 2565340926 KeyObjectParentID VTFunctionECUtoVT 0-0;
SG_MUL_VAL_ 2565340926 ButtonObjectParentID VTFunctionECUtoVT 1-1;
SG_MUL_VAL_ 2565340926 VTChangeNumericValueValue VTFunctionECUtoVT 5-5;
SG_MUL_VAL_ 2565340926 AuxErrorInvalidInputID VTFunctionECUtoVT 37-37;
SG_MUL_VAL_ 2565340926 OnTimeDuration_Audio VTFunctionECUtoVT 163-163;
SG_MUL_VAL_ 2565340926 NewValue VTFunctionECUtoVT 168-168;
SG_MUL_VAL_ 2565340926 FontSize VTFunctionECUtoVT 170-170;
SG_MUL_VAL_ 2565340926 LineWidth VTFunctionECUtoVT 171-171;
SG_MUL_VAL_ 2565340926 FillColour VTFunctionECUtoVT 172-172;
SG_MUL_VAL_ 2565340926 NewSoftKeyMaskObjectID VTFunctionECUtoVT 174-174;
SG_MUL_VAL_ 2565340926 NewAttributeValue VTFunctionECUtoVT 175-175;
SG_MUL_VAL_ 2565340926 NewObjectID VTFunctionECUtoVT 177-177;
SG_MUL_VAL_ 2565340926 NewValueX VTFunctionECUtoVT 182-182;
SG_MUL_VAL_ 2565340926 LockTimeout VTFunctionECUtoVT 189-189;
SG_MUL_VAL_ 2565340926 LastWideChar VTFunctionECUtoVT 193-193;
SG_MUL_VAL_ 2565340926 PictureGraphicsID_Viewport SubCommandID 20-20;
SG_MUL_VAL_ 2565340926 PictureGraphicsID_Canvas SubCommandID 19-19;
SG_MUL_VAL_ 2565340926 ObjectID SubCommandID 18-18;
SG_MUL_VAL_ 2565340926 NewViewportWidth SubCommandID 17-17;
SG_MUL_VAL_ 2565340926 ViewportX_PanZoom SubCommandID 16-16;
SG_MUL_VAL_ 2565340926 ZoomValue SubCommandID 15-15;
SG_MUL_VAL_ 2565340926 ViewportX SubCommandID 14-14;
SG_MUL_VAL_ 2565340926 TextOption SubCommandID 13-13;
SG_MUL_VAL_ 2565340926 NumberOfPoints SubCommandID 12-12;
SG_MUL_VAL_ 2565340926 EllipseWidth SubCommandID 11-11;
SG_MUL_VAL_ 2565340926 RectangleWidth_Draw SubCommandID 10-10;
SG_MUL_VAL_ 2565340926 EndPixelOffsetX SubCommandID 9-9;
SG_MUL_VAL_ 2565340926 PixelOffsetX SubCommandID 8-8;
SG_MUL_VAL_ 2565340926 RectangleHeight_Erase SubCommandID 7-7;
SG_MUL_VAL_ 2565340926 RectangleWidth_Erase SubCommandID 7-7;
SG_MUL_VAL_ 2565340926 FontAttributesObjectID SubCommandID 6-6;
SG_MUL_VAL_ 2565340926 FillAttributesObjectID SubCommandID 5-5;
SG_MUL_VAL_ 2565340926 LineAttributesObjectID SubCommandID 4-4;
SG_MUL_VAL_ 2565340926 BackgroundColour SubCommandID 3-3;
SG_MUL_VAL_ 2565340926 ForegroundColour SubCommandID 2-2;
SG_MUL_VAL_ 2565340926 CursorOffsetY SubCommandID 1-1;
SG_MUL_VAL_ 2565340926 CursorOffsetX SubCommandID 1-1;
SG_MUL_VAL_ 2565340926 CursorPosX SubCommandID 0-0;
SG_MUL_VAL_ 2565340926 AuxErrorAnyOther VTFunctionECUtoVT 37-37;
SG_MUL_VAL_ 2565340926 TextLength SubCommandID 13-13;
SG_MUL_VAL_ 2565340926 TouchState VTFunctionECUtoVT 2-2;
SG_MUL_VAL_ 2565340926 XPosChangeTopLeft VTFunctionECUtoVT 165-165;
SG_MUL_VAL_ 2565340926 NewHeight VTFunctionECUtoVT 166-166;
SG_MUL_VAL_ 2565340926 Height VTFunctionECUtoVT 169-169;
SG_MUL_VAL_ 2565340926 LabelFontType VTFunctionECUtoVT 181-181;
SG_MUL_VAL_ 2565340926 LineArt VTFunctionECUtoVT 171-171;
SG_MUL_VAL_ 2565340926 FillPatternObjectID VTFunctionECUtoVT 172-172;
SG_MUL_VAL_ 2565340926 XPosChangeTopLeftLong VTFunctionECUtoVT 180-180;
SG_MUL_VAL_ 2565340926 FontType VTFunctionECUtoVT 170-170;
SG_MUL_VAL_ 2565340926 NewHeigthAttribute VTFunctionECUtoVT 183-183;
SG_MUL_VAL_ 2565340926 Value2 VTFunctionECUtoVT 33-33;
SG_MUL_VAL_ 2565340926 NewStringValue VTFunctionECUtoVT 179-179;
SG_MUL_VAL_ 2565340926 CursorPosY SubCommandID 0-0;
SG_MUL_VAL_ 2565340926 PixelOffsetY SubCommandID 8-8;
SG_MUL_VAL_ 2565340926 EndPixelOffsetY SubCommandID 9-9;
SG_MUL_VAL_ 2565340926 RectangleHeight_Draw SubCommandID 10-10;
SG_MUL_VAL_ 2565340926 EllipseHeight SubCommandID 11-11;
SG_MUL_VAL_ 2565340926 ViewportY SubCommandID 14-14;
SG_MUL_VAL_ 2565340926 ViewportY_PanZoom SubCommandID 16-16;
SG_MUL_VAL_ 2565340926 NewViewportHeight SubCommandID 17-17;
SG_MUL_VAL_ 2565340926 Status_2 VTFunctionECUtoVT 9-9;
SG_MUL_VAL_ 2565340926 SoftKeyCode VTFunctionECUtoVT 0-0;
SG_MUL_VAL_ 2565340926 ButtonKeyCode VTFunctionECUtoVT 1-1;
SG_MUL_VAL_ 2565340926 OffTimeDuration_Audio VTFunctionECUtoVT 163-163;
SG_MUL_VAL_ 2565340926 YPosChangeTopLeft VTFunctionECUtoVT 165-165;
SG_MUL_VAL_ 2565340926 FontStyle VTFunctionECUtoVT 170-170;
SG_MUL_VAL_ 2565340926 GraphicRepresentationObjectID VTFunctionECUtoVT 181-181;
SG_MUL_VAL_ 2565340926 NewValueY VTFunctionECUtoVT 182-182;
SG_MUL_VAL_ 2565340926 LineDirection VTFunctionECUtoVT 169-169;
SG_MUL_VAL_ 2565340926 YPosChangeTopLeftLong VTFunctionECUtoVT 180-180;
SG_MUL_VAL_ 2565340926 OperatingState1 VTFunctionECUtoVT 33-33;
SG_MUL_VAL_ 2565340926 OperatingState2 VTFunctionECUtoVT 33-33;
SG_MUL_VAL_ 2565340926 ZoomValue_PanZoom SubCommandID 16-16;
SG_MUL_VAL_ 2565340926 ModelIdentificationCode VTFunctionECUtoVT 34-34;
SG_MUL_VAL_ 2565340926 NumOfPreferredFunctions VTFunctionECUtoVT 34-34;
SG_MUL_VAL_ 2565340926 AuxiliaryFunctionID_1 VTFunctionECUtoVT 34-34;
SG_MUL_VAL_ 2565340926 AuxiliaryInputID_1 VTFunctionECUtoVT 34-34;
